VERSION ""

NS_ :

BS_:

BU_: ICC DVR EPC BBCM EAMP CMSM SBOX FLZCU_HCU_IC FLZCU_IC HCU_IC FLZCU_Signal_IC CGW TBOX BNCM CWC FRZCU

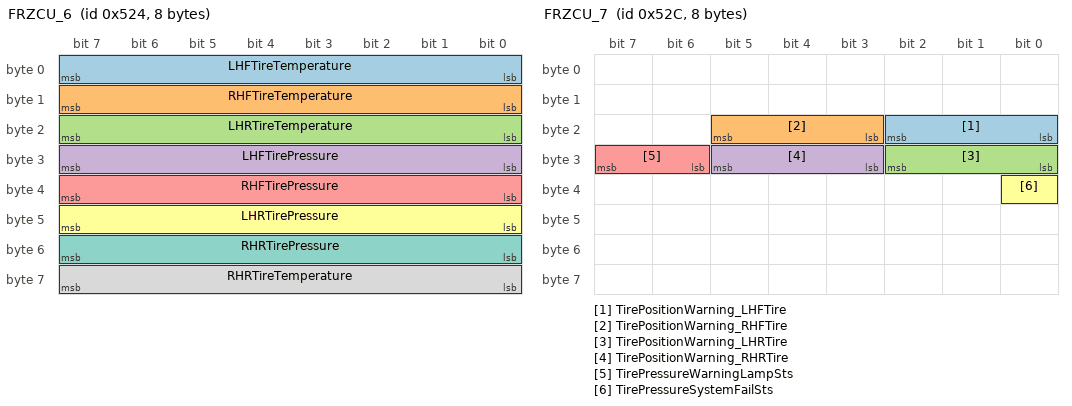
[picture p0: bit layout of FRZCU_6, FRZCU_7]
BO_ 1316 FRZCU_6: 8 CGW
 SG_ LHFTireTemperature : 7|8@0+ (0.65,-40) [-40|125.1] "℃"  ICC
 SG_ RHFTireTemperature : 15|8@0+ (0.65,-40) [-40|125.1] "℃"  ICC
 SG_ LHRTireTemperature : 23|8@0+ (0.65,-40) [-40|125.1] "℃"  ICC
 SG_ LHFTirePressure : 31|8@0+ (1.373,0) [0|350.115] "kPa"  ICC
 SG_ RHFTirePressure : 39|8@0+ (1.373,0) [0|350.115] "kPa"  ICC
 SG_ LHRTirePressure : 47|8@0+ (1.373,0) [0|350.115] "kPa"  ICC
 SG_ RHRTirePressure : 55|8@0+ (1.373,0) [0|350.115] "kPa"  ICC
 SG_ RHRTireTemperature : 63|8@0+ (0.65,-40) [-40|125.1] "℃"  ICC

BO_ 1324 FRZCU_7: 8 CGW
 SG_ TirePositionWarning_LHFTire : 18|3@0+ (1,0) [0|7] ""  ICC
 SG_ TirePositionWarning_RHFTire : 21|3@0+ (1,0) [0|7] ""  ICC
 SG_ TirePositionWarning_LHRTire : 26|3@0+ (1,0) [0|7] ""  ICC
 SG_ TirePositionWarning_RHRTire : 29|3@0+ (1,0) [0|7] ""  ICC
 SG_ TirePressureWarningLampSts : 31|2@0+ (1,0) [0|3] ""  ICC
 SG_ TirePressureSystemFailSts : 32|1@0+ (1,0) [0|1] ""  ICC

BO_ 991 TMS_2: 24 CGW
 SG_ TMS_MotorLoopErrorLevel : 126|3@0+ (1,0) [0|7] ""  ICC
 SG_ TMS_BatteryLoopErrorLevel : 123|3@0+ (1,0) [0|7] ""  ICC

BO_ 1188 TMS_3: 32 CGW
 SG_ FrontDeforestDisplaySts : 16|1@0+ (1,0) [0|1] ""  ICC
 SG_ TMS_DisplayActive : 18|1@0+ (1,0) [0|1] ""  ICC
 SG_ TMS_ZoneSelectionDisplaySts : 19|1@0+ (1,0) [0|1] ""  ICC
 SG_ TMS_AutoDisplaySts : 20|1@0+ (1,0) [0|1] ""  ICC
 SG_ TMS_FiltertchangeDisplaySts : 21|1@0+ (1,0) [0|1] ""  ICC
 SG_ TMS_AUTODefrostOnSts : 22|1@0+ (1,0) [0|1] ""  ICC
 SG_ TMS_AUTODefrostDisplaySts : 23|1@0+ (1,0) [0|1] ""  ICC
 SG_ TMS_RefInSufDispSts : 24|1@0+ (1,0) [0|1] ""  ICC
 SG_ TMS_CooltInSufDispSts : 25|1@0+ (1,0) [0|1] ""  ICC
 SG_ TMS_DLOnOffSts : 26|1@0+ (1,0) [0|1] ""  ICC
 SG_ TMS_DROnOffSts : 27|1@0+ (1,0) [0|1] ""  ICC
 SG_ TMS_PLOnOffSts : 28|1@0+ (1,0) [0|1] ""  ICC
 SG_ WorkingSts : 29|1@0+ (1,0) [0|1] ""  ICC
 SG_ TMS_PROnOffSts : 30|1@0+ (1,0) [0|1] ""  ICC
 SG_ TMS_DCOnOffSts : 31|1@0+ (1,0) [0|1] ""  ICC
 SG_ TMS_ACFastCool : 48|1@0+ (1,0) [0|1] ""  ICC
 SG_ TMS_ACFastHeat : 49|1@0+ (1,0) [0|1] ""  ICC
 SG_ TMS_LoveRemind : 50|1@0+ (1,0) [0|1] ""  ICC
 SG_ TMS_InteCleanCar : 51|1@0+ (1,0) [0|1] ""  ICC
 SG_ TMS_ACVentilationSts : 52|1@0+ (1,0) [0|1] ""  ICC
 SG_ TMS_AutoAirCleanSts : 53|1@0+ (1,0) [0|1] ""  ICC
 SG_ PM25Sts : 54|1@0+ (1,0) [0|1] ""  ICC
 SG_ TMS_ACModeCustomSts : 33|2@0+ (1,0) [0|3] ""  ICC
 SG_ TMS_ACRequestDisplaySts : 36|3@0+ (1,0) [0|7] ""  ICC
 SG_ TMS_AUTODefLevelSts : 39|3@0+ (1,0) [0|7] ""  ICC
 SG_ TMS_KeepWarm : 41|2@0+ (1,0) [0|3] ""  ICC
 SG_ TMS_DSwingSts : 44|3@0+ (1,0) [0|7] ""  ICC
 SG_ TMS_PSwingSts : 47|3@0+ (1,0) [0|7] ""  ICC
 SG_ TMS_TuisongDispSts : 58|3@0+ (1,0) [0|7] ""  ICC
 SG_ TMS_SetTemperature_L_C : 63|5@0+ (0.5,15.5) [15.5|30.5] ""  ICC
 SG_ TMS_SetTemperature_R_C : 68|5@0+ (0.5,15.5) [15.5|30.5] ""  ICC
 SG_ TMS_ModeAdjustDisplaySts : 75|4@0+ (1,0) [0|15] ""  ICC
 SG_ TMS_CirculationModeDisplaySts : 79|2@0+ (1,0) [0|3] ""  ICC
 SG_ TMS_IncarTemp : 87|8@0+ (0.5,-40) [-40|85] ""  ICC
 SG_ TMS_FliterLife : 94|7@0+ (1,0) [0|100] ""  ICC
 SG_ TMS_DLSwingUpDwnWPosn : 102|7@0+ (1,0) [0|100] ""  ICC
 SG_ TMS_DLSwingLeRiWPosn : 110|7@0+ (1,0) [0|100] ""  ICC
 SG_ TMS_DRSwingUpDwnWPosn : 118|7@0+ (1,0) [0|100] ""  ICC
 SG_ TMS_DRSwingLeRiWPosn : 126|7@0+ (1,0) [0|100] ""  ICC
 SG_ TMS_PLSwingUpDwnWPosn : 134|7@0+ (1,0) [0|100] ""  ICC
 SG_ TMS_PLSwingLeRiWPosn : 142|7@0+ (1,0) [0|100] ""  ICC
 SG_ TMS_PRSwingUpDwnWPosn : 150|7@0+ (1,0) [0|100] ""  ICC
 SG_ TMS_PRSwingLeRiWPosn : 158|7@0+ (1,0) [0|100] ""  ICC
 SG_ TMS_DCSwingLeRiWPosn : 166|7@0+ (1,0) [0|100] ""  ICC
 SG_ AirSwingSts : 168|1@0+ (1,0) [0|1] ""  ICC
 SG_ TemperatureUnit : 169|1@0+ (1,0) [0|1] ""  ICC
 SG_ BlowAdvanceOnSts : 170|1@0+ (1,0) [0|1] ""  ICC
 SG_ BlowDelayOffSts : 171|1@0+ (1,0) [0|1] ""  ICC
 SG_ TMS_PM25_ExtSts : 172|1@0+ (1,0) [0|1] ""  ICC
 SG_ TMS_PM25_IncarSts : 173|1@0+ (1,0) [0|1] ""  ICC
 SG_ TMS_AQS_Sts : 174|1@0+ (1,0) [0|1] ""  ICC
 SG_ PM25overproofDisplaySts : 175|1@0+ (1,0) [0|1] ""  ICC
 SG_ AQSDisplaySts : 176|1@0+ (1,0) [0|1] ""  ICC
 SG_ PM25AutoRunSts : 177|1@0+ (1,0) [0|1] ""  ICC
 SG_ PM25AutoRunSetSts : 178|1@0+ (1,0) [0|1] ""  ICC
 SG_ FragranceWelcomeModeSts : 179|1@0+ (1,0) [0|1] ""  ICC
 SG_ FragranceDisplaysts : 180|1@0+ (1,0) [0|1] ""  ICC
 SG_ TMS_AQS_Level : 185|2@0+ (1,0) [0|3] ""  ICC
 SG_ ACRequestCommand : 188|3@0+ (1,0) [0|7] ""  ICC
 SG_ PM25_Outcar_Level : 191|3@0+ (1,0) [0|7] ""  ICC
 SG_ PM25_Incar_Level : 194|3@0+ (1,0) [0|7] ""  ICC
 SG_ SetTemperature_L_F : 215|5@0+ (1,63) [63|93] ""  ICC
 SG_ SetTemperature_R_F : 223|5@0+ (1,63) [63|93] ""  ICC
 SG_ TMS_PM25_incar : 231|10@0+ (1,0) [0|1000] ""  ICC
 SG_ TMS_PM25_ext : 237|10@0+ (1,0) [0|1000] ""  ICC
 SG_ TMS_KeepWarmMemoryFb : 243|2@0+ (1,0) [0|3] ""  ICC

BO_ 612 EPB_R_1: 24 CGW
 SG_ Fusa_264_5 : 40|17@0+ (1,0) [0|131071] ""  ICC
 SG_ Fusa_264_4 : 47|6@0+ (1,0) [0|63] ""  ICC
 SG_ Fusa_264_3 : 24|5@0+ (1,0) [0|31] ""  ICC
 SG_ Fusa_264_2 : 16|7@0+ (1,0) [0|127] ""  ICC
 SG_ Fusa_264_1 : 15|4@0+ (1,0) [0|15] ""  ICC
 SG_ EPB_R_1_CRC1 : 7|8@0+ (1,0) [0|255] ""  ICC
 SG_ EPB_R_1_RollgCntr1 : 11|4@0+ (1,0) [0|14] ""  ICC
 SG_ EPB_1_FltLamp : 18|2@0+ (1,0) [0|3] ""  ICC
 SG_ EPB_1_ParkLamp : 20|2@0+ (1,0) [0|3] ""  ICC
 SG_ EPB_1_ActrSt : 23|3@0+ (1,0) [0|7] ""  ICC,DVR
 SG_ EPB_1_RWUSt : 25|1@0+ (1,0) [0|1] ""  ICC
 SG_ EPB_1_TextDisp : 35|4@0+ (1,0) [0|15] ""  ICC
 SG_ IPB_EPBErrorStatus : 41|1@0+ (1,0) [0|1] ""  ICC

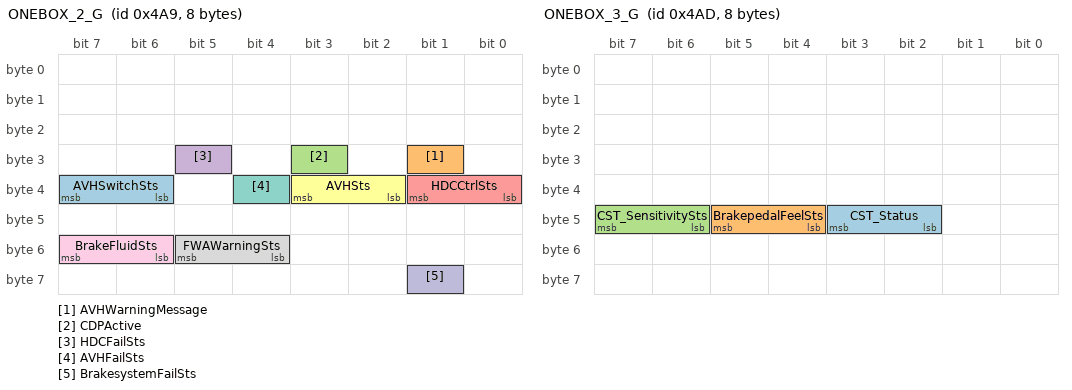
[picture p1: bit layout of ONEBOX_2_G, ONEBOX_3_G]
BO_ 1193 ONEBOX_2_G: 8 CGW
 SG_ AVHSwitchSts : 39|2@0+ (1,0) [0|3] ""  ICC
 SG_ AVHWarningMessage : 25|1@0+ (1,0) [0|1] ""  ICC
 SG_ CDPActive : 27|1@0+ (1,0) [0|1] ""  ICC
 SG_ HDCFailSts : 29|1@0+ (1,0) [0|1] ""  ICC
 SG_ HDCCtrlSts : 33|2@0+ (1,0) [0|3] ""  ICC
 SG_ AVHSts : 35|2@0+ (1,0) [0|3] ""  ICC
 SG_ AVHFailSts : 36|1@0+ (1,0) [0|1] ""  ICC
 SG_ FWAWarningSts : 53|2@0+ (1,0) [0|3] ""  ICC
 SG_ BrakeFluidSts : 55|2@0+ (1,0) [0|3] ""  ICC
 SG_ BrakesystemFailSts : 57|1@0+ (1,0) [0|1] ""  ICC

BO_ 1197 ONEBOX_3_G: 8 CGW
 SG_ CST_Status : 43|2@0+ (1,0) [0|3] ""  ICC
 SG_ BrakepedalFeelSts : 45|2@0+ (1,0) [0|3] ""  ICC
 SG_ CST_SensitivitySts : 47|2@0+ (1,0) [0|3] ""  ICC

BO_ 1200 FLZCU_6: 8 CGW
 SG_ EBS_SOC : 7|8@0+ (1,0) [0|100] "%"  ICC

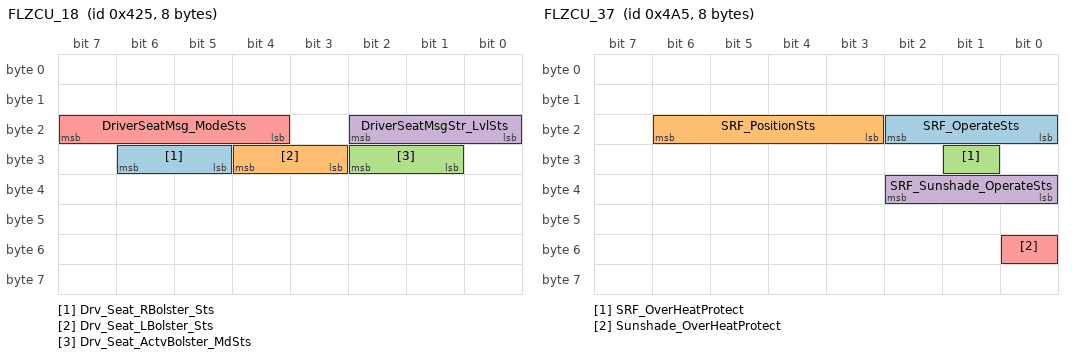
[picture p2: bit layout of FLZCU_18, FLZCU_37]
BO_ 1061 FLZCU_18: 8 CGW
 SG_ Drv_Seat_RBolster_Sts : 30|2@0+ (1,0) [0|3] ""  ICC
 SG_ Drv_Seat_LBolster_Sts : 28|2@0+ (1,0) [0|3] ""  ICC
 SG_ Drv_Seat_ActvBolster_MdSts : 26|2@0+ (1,0) [0|3] ""  ICC
 SG_ DriverSeatMsgStr_LvlSts : 18|3@0+ (1,0) [0|7] ""  ICC
 SG_ DriverSeatMsg_ModeSts : 23|4@0+ (1,0) [0|15] ""  ICC

BO_ 1065 FLZCU_19: 8 CGW
 SG_ LeftSeatMsgStr_LvlSts : 18|3@0+ (1,0) [0|7] ""  ICC
 SG_ LeftSeatMsg_ModeSts : 23|4@0+ (1,0) [0|15] ""  ICC

BO_ 1069 FLZCU_20: 8 CGW
 SG_ PassSeatMsgStr_LvlSts : 18|3@0+ (1,0) [0|7] ""  ICC
 SG_ PassSeatMsg_ModeSts : 23|4@0+ (1,0) [0|15] ""  ICC

BO_ 1087 FLZCU_21: 8 CGW
 SG_ RightSeatMsgStr_LvlSts : 18|3@0+ (1,0) [0|7] ""  ICC
 SG_ RightSeatMsg_ModeSts : 23|4@0+ (1,0) [0|15] ""  ICC

BO_ 1189 FLZCU_37: 8 CGW
 SG_ SRF_OperateSts : 18|3@0+ (1,0) [0|7] ""  ICC
 SG_ SRF_PositionSts : 22|4@0+ (1,0) [0|12] ""  ICC
 SG_ SRF_OverHeatProtect : 25|1@0+ (1,0) [0|1] ""  ICC
 SG_ SRF_Sunshade_OperateSts : 34|3@0+ (1,0) [0|7] ""  ICC
 SG_ Sunshade_OverHeatProtect : 48|1@0+ (1,0) [0|1] ""  ICC

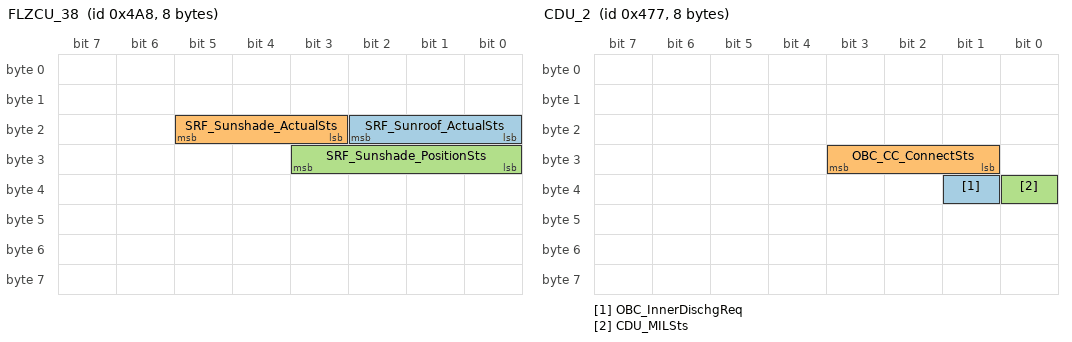
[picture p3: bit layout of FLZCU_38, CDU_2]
BO_ 1192 FLZCU_38: 8 CGW
 SG_ SRF_Sunroof_ActualSts : 18|3@0+ (1,0) [0|7] ""  ICC
 SG_ SRF_Sunshade_ActualSts : 21|3@0+ (1,0) [0|7] ""  ICC
 SG_ SRF_Sunshade_PositionSts : 27|4@0+ (1,0) [0|12] ""  ICC

BO_ 1143 CDU_2: 8 CGW
 SG_ OBC_InnerDischgReq : 33|1@0+ (1,0) [0|1] ""  ICC
 SG_ OBC_CC_ConnectSts : 27|3@0+ (1,0) [0|7] ""  ICC
 SG_ CDU_MILSts : 32|1@0+ (1,0) [0|1] ""  ICC

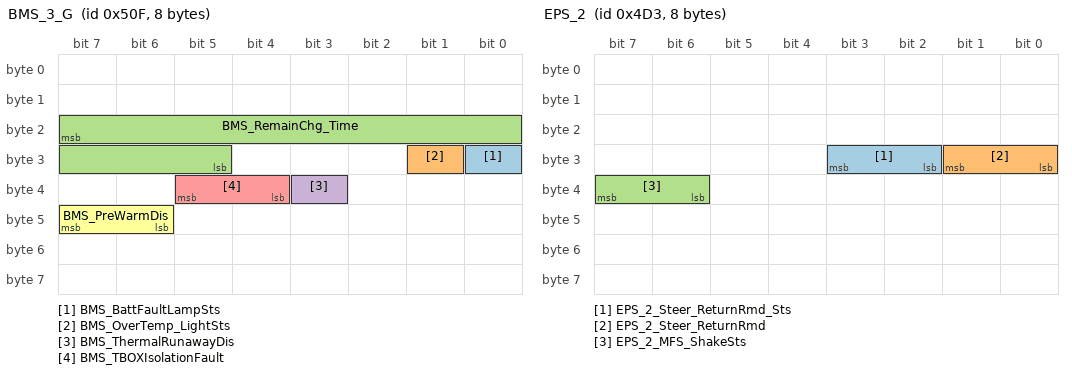
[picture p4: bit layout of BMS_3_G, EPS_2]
BO_ 1295 BMS_3_G: 8 CGW
 SG_ BMS_BattFaultLampSts : 24|1@0+ (1,0) [0|1] ""  ICC
 SG_ BMS_OverTemp_LightSts : 25|1@0+ (1,0) [0|1] ""  ICC
 SG_ BMS_RemainChg_Time : 23|11@0+ (1,0) [0|2047] "min"  ICC
 SG_ BMS_ThermalRunawayDis : 35|1@0+ (1,0) [0|1] ""  ICC
 SG_ BMS_TBOXIsolationFault : 37|2@0+ (1,0) [0|3] ""  ICC
 SG_ BMS_PreWarmDis : 47|2@0+ (1,0) [0|2] ""  ICC

BO_ 1531 BMS_9: 32 CGW
 SG_ BMS_HvBattSoeActDisChaCyc : 23|16@0+ (0.1,0) [0|999.9] "kWh"  ICC
 SG_ BMS_HvBattSoeActReChaCyc : 39|16@0+ (0.1,0) [0|999.9] "kWh"  ICC
 SG_ BMS_HvBattRatedEnergy : 55|14@0+ (0.1,0) [0|999.9] "KW?h"  ICC
 SG_ BMS_HvBattRatedU : 71|14@0+ (0.1,0) [0|999.9] "V"  ICC
 SG_ BMS_HvBattTypeCode : 87|8@0+ (1,0) [0|255] ""  ICC
 SG_ BMS_HvBattManufcCode : 95|32@0+ (1,0) [0|4294967295] ""  ICC
 SG_ BMS_HvBattTempSensorTotalNum : 127|16@0+ (1,0) [0|65534] ""  ICC
 SG_ BMS_HvBattTempSensorTempMaxNum : 143|8@0+ (1,0) [1|250] ""  ICC
 SG_ BMS_HvBattTempSensorTempMinNum : 151|8@0+ (1,0) [1|250] ""  ICC
 SG_ BMS_HvBattTempMaxNum : 159|8@0+ (1,0) [1|250] ""  ICC
 SG_ BMS_HvBattTempMinNum : 167|8@0+ (1,0) [1|250] ""  ICC
 SG_ BMS_BattCellTotalNum : 175|16@0+ (1,0) [0|65531] ""  ICC
 SG_ BMS_HvBattVoltMaxNum : 191|8@0+ (1,0) [1|250] ""  ICC
 SG_ BMS_HvBattVoltMinNum : 199|8@0+ (1,0) [1|250] ""  ICC
 SG_ BMS_ActualSOCMin : 207|12@0+ (0.025,0) [0|100] "%"  ICC
 SG_ BMS_ActualSOCMax : 211|12@0+ (0.025,0) [0|100] "%"  ICC

BO_ 1224 BMS_12: 16 CGW
 SG_ BMS_HvBattCellVoltMax_Num : 23|8@0+ (1,0) [0|250] ""  ICC
 SG_ BMS_HvBattCellVoltMax : 31|16@0+ (0.001,0) [0|15] "V"  ICC
 SG_ BMS_HvBattCellVoltMin_Num : 47|8@0+ (1,0) [0|250] ""  ICC
 SG_ BMS_HvBattCellVoltMin : 55|16@0+ (0.001,0) [0|15] "V"  ICC
 SG_ BMS_Chg_Sts : 87|4@0+ (1,0) [0|15] ""  ICC

BO_ 1235 EPS_2: 8 CGW
 SG_ EPS_2_Steer_ReturnRmd_Sts : 27|2@0+ (1,0) [0|3] ""  ICC
 SG_ EPS_2_Steer_ReturnRmd : 25|2@0+ (1,0) [0|3] ""  ICC
 SG_ EPS_2_MFS_ShakeSts : 39|2@0+ (1,0) [0|3] ""  ICC

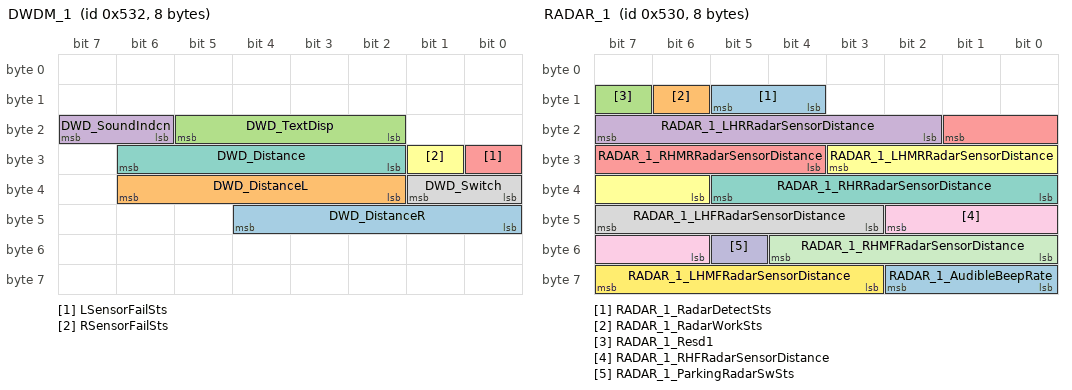
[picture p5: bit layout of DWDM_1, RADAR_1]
BO_ 1330 DWDM_1: 8 CGW
 SG_ DWD_DistanceR : 44|5@0+ (1,0) [0|31] ""  ICC
 SG_ DWD_DistanceL : 38|5@0+ (1,0) [0|31] ""  ICC
 SG_ DWD_TextDisp : 21|4@0+ (1,0) [0|15] ""  ICC
 SG_ DWD_SoundIndcn : 23|2@0+ (1,0) [0|3] ""  ICC
 SG_ LSensorFailSts : 24|1@0+ (1,0) [0|1] ""  ICC
 SG_ RSensorFailSts : 25|1@0+ (1,0) [0|1] ""  ICC
 SG_ DWD_Distance : 30|5@0+ (1,0) [0|31] ""  ICC
 SG_ DWD_Switch : 33|2@0+ (1,0) [0|3] ""  ICC

BO_ 1328 RADAR_1: 8 CGW
 SG_ RADAR_1_RadarDetectSts : 13|2@0+ (1,0) [0|3] "Bit"  ICC
 SG_ RADAR_1_RadarWorkSts : 14|1@0+ (1,0) [0|1] "Bit"  ICC
 SG_ RADAR_1_Resd1 : 15|1@0+ (1,0) [0|1] ""  ICC
 SG_ RADAR_1_LHRRadarSensorDistance : 23|6@0+ (5,25) [25|180] "Cm"  ICC
 SG_ RADAR_1_RHMRRadarSensorDistance : 17|6@0+ (5,25) [25|180] "Cm"  ICC
 SG_ RADAR_1_LHMRRadarSensorDistance : 27|6@0+ (5,25) [25|180] "Cm"  ICC
 SG_ RADAR_1_RHRRadarSensorDistance : 37|6@0+ (5,25) [25|180] "Cm"  ICC
 SG_ RADAR_1_LHFRadarSensorDistance : 47|5@0+ (5,25) [25|160] "Cm"  ICC
 SG_ RADAR_1_RHFRadarSensorDistance : 42|5@0+ (5,25) [25|160] "Cm"  ICC
 SG_ RADAR_1_ParkingRadarSwSts : 53|1@0+ (1,0) [0|1] "Bit"  ICC
 SG_ RADAR_1_RHMFRadarSensorDistance : 52|5@0+ (5,25) [25|160] "Cm"  ICC
 SG_ RADAR_1_LHMFRadarSensorDistance : 63|5@0+ (5,25) [25|160] "Cm"  ICC
 SG_ RADAR_1_AudibleBeepRate : 58|3@0+ (1,0) [0|7] "Bit"  ICC

BO_ 259 EMS_6: 16 CGW
 SG_ EMS_EngineSpeed_Actual : 39|16@0+ (0.25,0) [0|16383] "rpm"  ICC

BO_ 1234 FRZCU_11: 32 CGW
 SG_ FRZCU_ManualPowerOFFWarning_4D2h : 16|1@0+ (1,0) [0|1] ""  ICC
 SG_ FRZCU_FRSeatHeiFb : 23|7@0+ (1,-1) [-1|100] "%"  ICC,BBCM
 SG_ FRZCU_FRSeatLvlFb : 31|7@0+ (1,-1) [-1|100] "%"  ICC,BBCM
 SG_ FRZCU_FRSeatBackAgFb : 39|7@0+ (1,-1) [-1|100] "%"  ICC,BBCM
 SG_ FRZCU_FRSeatLegSpprtFb : 47|7@0+ (1,-1) [-1|100] "%"  ICC
 SG_ FRZCU_FRWinSts : 55|3@0+ (1,0) [0|7] ""  ICC
 SG_ FRZCU_RRWinSts : 52|3@0+ (1,0) [0|7] ""  ICC
 SG_ FRZCU_FRSeatLegRestAngleFb : 62|7@0+ (1,-1) [-1|100] "%"  ICC
 SG_ FRZCU_FRSeatCushFb : 86|7@0+ (1,-1) [-1|100] "%"  ICC,BBCM
 SG_ FRZCU_FRSeatNeedMemory : 105|2@0+ (1,0) [0|3] ""  ICC
 SG_ FRZCU_FRMemoryFb : 107|2@0+ (1,0) [0|3] ""  ICC
 SG_ FRZCU_FRRecoverFb : 109|2@0+ (1,0) [0|3] ""  ICC
 SG_ FRZCU_EasyEntryExitFb : 111|2@0+ (1,0) [0|3] ""  ICC
 SG_ FRZCU_EnjoyableSeatWarning : 113|2@0+ (1,0) [0|3] ""  ICC
 SG_ FRZCU_EnjoyableSeatSts : 115|2@0+ (1,0) [0|3] ""  ICC
 SG_ SeatHeatLevelsFR : 127|3@0+ (1,0) [0|7] ""  ICC
 SG_ SeatVentLevelsFR : 123|2@0+ (1,0) [0|3] ""  ICC
 SG_ SeatHeatLevelsRR : 151|3@0+ (1,0) [0|7] ""  ICC
 SG_ SeatVentLevelsRR : 147|2@0+ (1,0) [0|3] ""  ICC
 SG_ FRZCU_FRSeatFoldFb : 167|7@0+ (1,-1) [-1|100] "%"  ICC

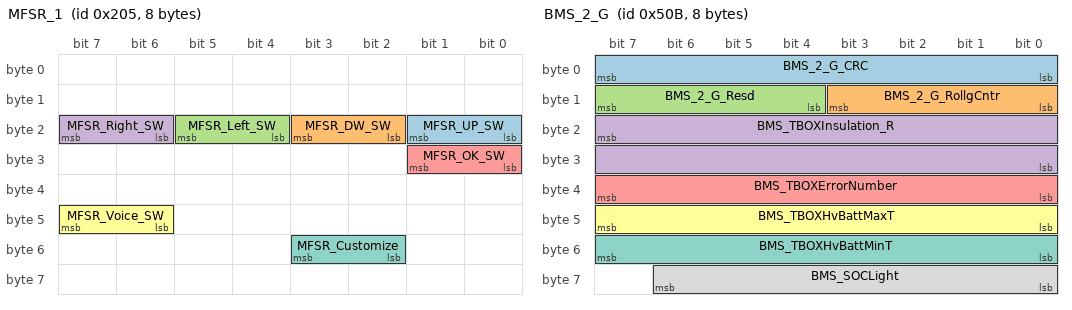
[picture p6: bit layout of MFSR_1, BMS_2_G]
BO_ 517 MFSR_1: 8 CGW
 SG_ MFSR_UP_SW : 17|2@0+ (1,0) [0|3] ""  ICC
 SG_ MFSR_DW_SW : 19|2@0+ (1,0) [0|3] ""  ICC
 SG_ MFSR_Left_SW : 21|2@0+ (1,0) [0|3] ""  ICC
 SG_ MFSR_Right_SW : 23|2@0+ (1,0) [0|3] ""  ICC
 SG_ MFSR_OK_SW : 25|2@0+ (1,0) [0|3] ""  ICC
 SG_ MFSR_Voice_SW : 47|2@0+ (1,0) [0|3] ""  ICC
 SG_ MFSR_Customize : 51|2@0+ (1,0) [0|3] ""  ICC

BO_ 1096 TMS_11: 32 CGW
 SG_ TMS_ICAstsFed_448h : 111|2@0+ (1,0) [0|3] ""  ICC
 SG_ TMS_SailEACDisable_448h : 109|2@0+ (1,0) [0|3] ""  ICC
 SG_ TMS_LowbattACDisable_448h : 107|2@0+ (1,0) [0|3] ""  ICC
 SG_ TMS_AutoDefogActiveSts : 37|1@0+ (1,0) [0|1] ""  ICC
 SG_ TMS_AirPurgeReminderSts : 17|2@0+ (1,0) [0|3] ""  ICC
 SG_ TMS_BT_Reduce_Wind_SpeedSts : 23|2@0+ (1,0) [0|3] "Bit"  ICC
 SG_ TMS_First_BlowingSts : 21|2@0+ (1,0) [0|3] "Bit"  ICC
 SG_ TMS_CirculationInTunnelsSts : 19|2@0+ (1,0) [0|3] "Bit"  ICC
 SG_ TMS_crosscountry_coolingSts : 29|2@0+ (1,0) [0|3] "Bit"  ICC
 SG_ TMS_ParkingAirConditioningStatus : 27|2@0+ (1,0) [0|3] "Bit"  ICC
 SG_ TMS_CoolantFillSts : 25|2@0+ (1,0) [0|3] "Bit"  ICC
 SG_ TMS_UVC_ControlSts : 39|2@0+ (1,0) [0|3] "Bit"  ICC
 SG_ TMS_UVC_LuminanceSts : 36|3@0+ (1,0) [0|7] "Bit"  ICC
 SG_ TMS_ICC_Lightoff_Sts : 33|2@0+ (1,0) [0|3] ""  ICC
 SG_ TMS_ICC_Memoff_Sts : 47|2@0+ (1,0) [0|3] ""  ICC
 SG_ TMS_keepwarmSet_TemperatureSts : 55|8@0+ (1,0) [0|254] "Bit"  ICC
 SG_ TMS_BiochemicalFuncSts : 95|2@0+ (1,0) [0|3] ""  ICC
 SG_ TMS_TimedVentilationSts : 97|2@0+ (1,0) [0|3] ""  ICC

BO_ 1240 TDU_9: 32 CGW
 SG_ TMS_CFSSwitchFb : 17|2@0+ (1,0) [0|3] ""  ICC
 SG_ TDU_CFSPosOneType : 21|4@0+ (1,0) [0|15] ""  ICC
 SG_ TDU_CFSPosTwoType : 27|4@0+ (1,0) [0|15] ""  ICC
 SG_ TDU_CFSPosThreeType : 31|4@0+ (1,0) [0|15] ""  ICC
 SG_ TDU_CFSRunOut : 39|4@0+ (1,0) [0|15] ""  ICC
 SG_ TMS_CFSShortWarn : 43|4@0+ (1,0) [0|15] ""  ICC
 SG_ TMS_CFSLevelSetFb : 47|4@0+ (1,0) [0|15] ""  ICC
 SG_ TMS_CFSPosSetFb : 49|2@0+ (1,0) [0|3] ""  ICC
 SG_ TMS_CFSPosOneLife : 63|8@0+ (1,0) [0|100] "%"  ICC
 SG_ TMS_CFSPosTwoLife : 87|8@0+ (1,0) [0|100] "%"  ICC
 SG_ TMS_CFSPosThreeLife : 95|8@0+ (1,0) [0|100] "%"  ICC
 SG_ TMS_PM25SwitchFb : 97|2@0+ (1,0) [0|3] ""  ICC
 SG_ TMS_ThrModeStsFb : 122|3@0+ (1,0) [0|6] ""  ICC
 SG_ TMS_ThrSetTempFb_C : 127|5@0+ (0.5,15.5) [15.5|30.5] "℃"  ICC
 SG_ TMS_ThrCLMSwitchFb : 145|2@0+ (1,0) [0|3] ""  ICC
 SG_ TMS_ThrAutoSwitchFb : 147|2@0+ (1,0) [0|3] ""  ICC
 SG_ TMS_ThrBlowSpeedLevelKeyStsFb : 151|4@0+ (1,0) [0|15] ""  ICC

BO_ 638 FRZCU_9: 16 CGW
 SG_ FRZCU_HoodSts : 45|2@0+ (1,0) [0|3] ""  ICC
 SG_ FRZCU_AuthenResult : 48|1@0+ (1,0) [0|1] ""  ICC
 SG_ FRZCU_PowerMode : 51|2@0+ (1,0) [0|3] ""  ICC
 SG_ FRZCU_TrunkSts : 53|2@0+ (1,0) [0|3] ""  ICC
 SG_ FRZCU_HandleSwitchStsFL : 57|2@0+ (1,0) [0|3] ""  ICC,BBCM
 SG_ FRZCU_HandleSwitchStsFR : 59|2@0+ (1,0) [0|3] ""  ICC,BBCM
 SG_ FRZCU_HandleSwitchStsRR : 61|2@0+ (1,0) [0|3] ""  ICC
 SG_ FRZCU_HandleSwitchStsRL : 63|2@0+ (1,0) [0|3] ""  ICC
 SG_ SeatLength_target_Passenger : 87|4@0+ (1,0) [0|15] ""  ICC
 SG_ SeatBackrest_target_Passenger : 95|5@0+ (1,0) [0|15] ""  ICC
 SG_ FRZCU_TrunkLockSts : 89|2@0+ (1,0) [0|3] ""  ICC
 SG_ FRZCU_HoodLockSts : 103|2@0+ (1,0) [0|3] ""  ICC
 SG_ FrontBackSpeedAdj_Cmd : 101|3@0+ (1,0) [0|7] ""  ICC
 SG_ FRZCU_GloveboxSW : 98|1@0+ (1,0) [0|1] ""  ICC
 SG_ FRZCU_FRReleaseLockSts : 111|3@0+ (1,0) [0|7] ""  ICC
 SG_ FRZCU_RRReleaseLockSts : 108|3@0+ (1,0) [0|7] ""  ICC
 SG_ FRZCU_PELockInKeyWarning : 105|1@0+ (1,0) [0|1] ""  ICC
 SG_ FRZCU_PowerOFFWarning : 118|1@0+ (1,0) [0|1] ""  ICC
 SG_ FRZCU_KeylessWarning : 116|1@0+ (1,0) [0|1] ""  ICC
 SG_ FRZCU_OTAPwrDwnReqFb : 113|2@0+ (1,0) [0|3] ""  ICC
 SG_ FRZCU_OTAPwrOnReqFb : 127|2@0+ (1,0) [0|3] ""  ICC

BO_ 949 PEPS_1: 16 CGW
 SG_ PEPS_InformationSource : 23|2@0+ (1,0) [0|3] ""  ICC,BBCM
 SG_ PEPS_OrderInformation : 21|4@0+ (1,0) [0|15] ""  ICC,BBCM
 SG_ PEPS_IDInformation : 31|4@0+ (1,0) [0|15] ""  ICC,BBCM
 SG_ PEPS_KeySts : 27|3@0+ (1,0) [0|7] ""  ICC,BBCM
 SG_ PEPS_ETRUnLockReq : 39|2@0+ (1,0) [0|3] ""  ICC,BBCM

BO_ 1028 PEPS_2: 16 CGW
 SG_ PEPS_WelcomeON : 17|2@0+ (1,0) [0|3] ""  ICC,BBCM
 SG_ PEPS_VehicleSearchReq : 19|2@0+ (1,0) [0|3] ""  ICC,BBCM
 SG_ PEPS_SATOReminder : 21|2@0+ (1,0) [0|3] ""  ICC,BBCM
 SG_ PEPS_PLGUnlockReq : 23|2@0+ (1,0) [0|3] ""  ICC,BBCM
 SG_ PEPS_RKETrunkSts : 25|2@0+ (1,0) [0|3] ""  ICC,BBCM
 SG_ PEPS_SSBInhibitCWCSts : 27|2@0+ (1,0) [0|3] ""  ICC,BBCM
 SG_ PEPS_WirelessChargingCtrSts : 29|2@0+ (1,0) [0|3] ""  ICC,BBCM
 SG_ PEPS_EmgyShutdown : 35|2@0+ (1,0) [0|3] ""  ICC,BBCM
 SG_ PEPS_SSBInputFailure : 37|2@0+ (1,0) [0|3] ""  ICC,BBCM
 SG_ PEPS_SmartSystemWarning1_1 : 39|2@0+ (1,0) [0|3] ""  ICC,BBCM
 SG_ PEPS_SmartSystemWarning2_2 : 41|2@0+ (1,0) [0|3] ""  ICC,BBCM
 SG_ PEPS_SmartSystemWarning3_1 : 43|2@0+ (1,0) [0|3] ""  ICC,BBCM
 SG_ PEPS_SmartSystemWarning3_2 : 45|2@0+ (1,0) [0|3] ""  ICC,BBCM
 SG_ PEPS_SmartSystemWarning4_2 : 47|2@0+ (1,0) [0|3] ""  ICC,BBCM
 SG_ PEPS_SmartSystemWarning4_3 : 49|2@0+ (1,0) [0|3] ""  ICC,BBCM
 SG_ PEPS_SystemWarning : 51|2@0+ (1,0) [0|3] ""  ICC,BBCM
 SG_ PEPS_BLTKeyPESts : 53|2@0+ (1,0) [0|3] ""  ICC,BBCM

BO_ 1291 BMS_2_G: 8 CGW
 SG_ BMS_2_G_CRC : 7|8@0+ (1,0) [0|255] ""  ICC
 SG_ BMS_2_G_RollgCntr : 11|4@0+ (1,0) [0|14] ""  ICC
 SG_ BMS_2_G_Resd : 15|4@0+ (1,0) [0|15] ""  ICC
 SG_ BMS_TBOXInsulation_R : 23|16@0+ (1,0) [0|60000] "kiloohm(kΩ)"  ICC
 SG_ BMS_TBOXErrorNumber : 39|8@0+ (1,0) [0|255] ""  ICC
 SG_ BMS_TBOXHvBattMaxT : 47|8@0+ (1,-40) [-40|210] "gradcelsius(°C)"  ICC
 SG_ BMS_TBOXHvBattMinT : 55|8@0+ (1,-40) [-40|210] "gradcelsius(°C)"  ICC
 SG_ BMS_SOCLight : 62|7@0+ (1,0) [0|100] "%"  ICC

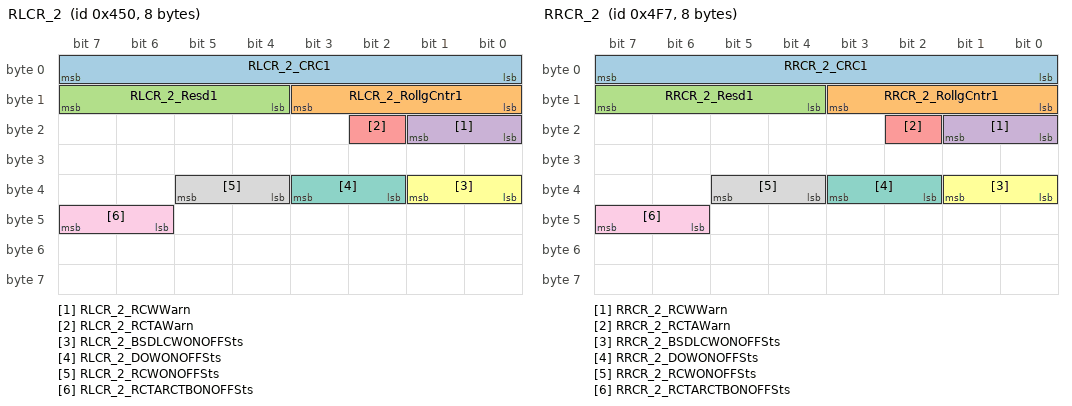
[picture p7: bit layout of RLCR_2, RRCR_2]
BO_ 1104 RLCR_2: 8 CGW
 SG_ RLCR_2_CRC1 : 7|8@0+ (1,0) [0|255] ""  ICC
 SG_ RLCR_2_RollgCntr1 : 11|4@0+ (1,0) [0|14] ""  ICC
 SG_ RLCR_2_Resd1 : 15|4@0+ (1,0) [0|15] ""  ICC
 SG_ RLCR_2_RCWWarn : 17|2@0+ (1,0) [0|3] ""  ICC
 SG_ RLCR_2_RCTAWarn : 18|1@0+ (1,0) [0|1] ""  ICC
 SG_ RLCR_2_BSDLCWONOFFSts : 33|2@0+ (1,0) [0|3] ""  ICC
 SG_ RLCR_2_DOWONOFFSts : 35|2@0+ (1,0) [0|3] ""  ICC
 SG_ RLCR_2_RCWONOFFSts : 37|2@0+ (1,0) [0|3] ""  ICC
 SG_ RLCR_2_RCTARCTBONOFFSts : 47|2@0+ (1,0) [0|3] ""  ICC

BO_ 1271 RRCR_2: 8 CGW
 SG_ RRCR_2_CRC1 : 7|8@0+ (1,0) [0|255] ""  ICC
 SG_ RRCR_2_RollgCntr1 : 11|4@0+ (1,0) [0|14] ""  ICC
 SG_ RRCR_2_Resd1 : 15|4@0+ (1,0) [0|15] ""  ICC
 SG_ RRCR_2_RCWWarn : 17|2@0+ (1,0) [0|3] ""  ICC
 SG_ RRCR_2_RCTAWarn : 18|1@0+ (1,0) [0|1] ""  ICC
 SG_ RRCR_2_BSDLCWONOFFSts : 33|2@0+ (1,0) [0|3] ""  ICC
 SG_ RRCR_2_DOWONOFFSts : 35|2@0+ (1,0) [0|3] ""  ICC
 SG_ RRCR_2_RCWONOFFSts : 37|2@0+ (1,0) [0|3] ""  ICC
 SG_ RRCR_2_RCTARCTBONOFFSts : 47|2@0+ (1,0) [0|3] ""  ICC

BO_ 587 ONEBOX_4: 48 CGW
 SG_ IPB_SandABSSwSts_24Bh : 269|2@0+ (1,0) [0|3] ""  ICC
 SG_ IPB_SandABSAvl_24Bh : 277|2@0+ (1,0) [0|3] ""  ICC
 SG_ ONEBOX_4_LHFWheelSpeedRPM : 23|16@0+ (0.0625,0) [0|4095.875] "rpm"  ICC
 SG_ ONEBOX_4_RHFWheelSpeedRPM : 39|16@0+ (0.0625,0) [0|4095.875] "rpm"  ICC
 SG_ LHRWheelSpeedRPM : 55|16@0+ (0.0625,0) [0|4095.875] "rpm"  ICC
 SG_ RHRWheelSpeedRPM : 87|16@0+ (0.0625,0) [0|4095.875] "rpm"  ICC
 SG_ LHRPulseCounterFailSts : 106|1@0+ (1,0) [0|1] ""  ICC
 SG_ LHRPulseCounter : 103|13@0+ (1,0) [0|8191] "pulse"  ICC
 SG_ RHRPulseCounterFailSts : 122|1@0+ (1,0) [0|1] ""  ICC
 SG_ RHRPulseCounter : 119|13@0+ (1,0) [0|8191] "pulse"  ICC
 SG_ RHFPulseCounterFailSts : 154|1@0+ (1,0) [0|1] ""  ICC
 SG_ RHFPulseCounter : 151|13@0+ (1,0) [0|8191] "pulse"  ICC
 SG_ LHFPulseCounterFailSts : 170|1@0+ (1,0) [0|1] ""  ICC
 SG_ LHFPulseCounter : 167|13@0+ (1,0) [0|8191] "pulse"  ICC
 SG_ LHFWheelDriveDirection : 187|3@0+ (1,0) [0|7] ""  ICC
 SG_ RHFWheelDriveDirection : 219|3@0+ (1,0) [0|7] ""  ICC
 SG_ LHRWheelDriveDirection : 235|3@0+ (1,0) [0|7] ""  ICC
 SG_ RHRWheelDriveDirection : 251|3@0+ (1,0) [0|7] ""  ICC

BO_ 1338 FMCU_1_G: 8 CGW
 SG_ FMCU_ErrLvlDis : 19|3@0+ (1,0) [0|7] ""  ICC
 SG_ FMCU_SpdAct_EDR : 39|16@0+ (1,-32767) [-32767|32766] "rpm"  ICC

BO_ 777 ISGF_2: 8 CGW
 SG_ ISGF_ErrLvl : 20|4@0+ (1,0) [0|6] ""  ICC

BO_ 1403 RMCU_1_G: 8 CGW
 SG_ RMCU_ErrLvlDis : 19|3@0+ (1,0) [0|7] ""  ICC
 SG_ RMCU_Speed_EDR : 39|16@0+ (1,-32767) [-32767|32766] "rpm"  ICC

BO_ 1299 BMS_1_G: 8 CGW
 SG_ BMS_PackVoltageDis : 23|16@0+ (0.1,0) [0|1000] "volt(V)"  ICC
 SG_ BMS_PackCurrentDis : 39|16@0+ (0.1,-2047) [-2047|2047] "ampere(A)"  ICC

BO_ 1099 ISGF_4: 8 CGW
 SG_ ISGF_SysTempOvrInd : 40|1@0+ (1,0) [0|1] ""  ICC

BO_ 1130 TCU_23: 64 CGW
 SG_ TCU_23_GBFaultstatus : 23|2@0+ (1,0) [0|3] ""  ICC
 SG_ TCU_23_TeachInState : 30|3@0+ (1,0) [0|7] ""  ICC

BO_ 1180 ACU_1: 8 CGW
 SG_ New_Signal_49C_9 : 32|25@0+ (1,0) [0|33554431] ""  ICC
 SG_ New_Signal_49C_8 : 37|4@0+ (1,0) [0|15] ""  ICC
 SG_ New_Signal_49C_7 : 27|1@0+ (1,0) [0|1] ""  ICC
 SG_ New_Signal_49C_6 : 29|1@0+ (1,0) [0|1] ""  ICC
 SG_ New_Signal_49C_5 : 31|1@0+ (1,0) [0|1] ""  ICC
 SG_ New_Signal_49C_4 : 19|2@0+ (1,0) [0|3] ""  ICC
 SG_ New_Signal_49C_3 : 21|1@0+ (1,0) [0|1] ""  ICC
 SG_ New_Signal_49C_2 : 23|1@0+ (1,0) [0|1] ""  ICC
 SG_ New_Signal_49C_1 : 15|4@0+ (1,0) [0|15] ""  ICC
 SG_ ACU_1_RollgCntr1 : 11|4@0+ (1,0) [0|15] ""  ICC
 SG_ ACU_1_CRC1 : 7|8@0+ (1,0) [0|255] ""  ICC
 SG_ ABM_1_Rollover_Status : 33|1@0+ (1,0) [0|1] ""  ICC
 SG_ ACU_1_AirBagFailSts : 17|2@0+ (1,0) [0|3] ""  ICC
 SG_ ACU_1_ThdRowLBeltWarning : 20|1@0+ (1,0) [0|1] ""  ICC
 SG_ ACU_1_ThdRowRBeltWarning : 22|1@0+ (1,0) [0|1] ""  ICC
 SG_ ACU_1_PsngrSeatBeltWarning : 25|2@0+ (1,0) [0|3] ""  ICC
 SG_ ACU_1_SecRowLBeltWarning : 26|1@0+ (1,0) [0|1] ""  ICC
 SG_ ACU_1_SecRowMBeltWarning : 28|1@0+ (1,0) [0|1] ""  ICC
 SG_ ACU_1_SecRowRBeltWarning : 30|1@0+ (1,0) [0|1] ""  ICC
 SG_ ACU_1_PsngrSeatOccupiedSts : 39|2@0+ (1,0) [0|3] ""  ICC,BBCM

BO_ 1248 FRZCU_TO_FLZCU: 48 CGW

BO_ 1341 BMS_44: 48 CGW
 SG_ BMS_44_PackPowerRealTime : 23|15@0+ (0.1,-1024) [-1024|1024] "kW"  ICC

BO_ 811 BMS_6: 16 CGW
 SG_ BMS_Chg_Sts : 87|4@0+ (1,0) [0|15] ""  ICC

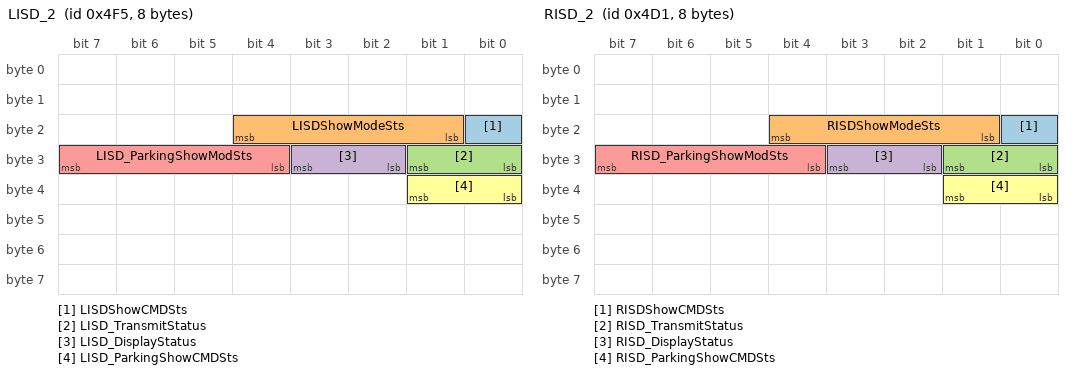
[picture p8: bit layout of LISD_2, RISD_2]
BO_ 1269 LISD_2: 8 CGW
 SG_ LISDShowCMDSts : 16|1@0+ (1,0) [0|1] ""  ICC
 SG_ LISDShowModeSts : 20|4@0+ (1,0) [0|15] ""  ICC
 SG_ LISD_TransmitStatus : 25|2@0+ (1,0) [0|3] ""  ICC
 SG_ LISD_DisplayStatus : 27|2@0+ (1,0) [0|3] ""  ICC
 SG_ LISD_ParkingShowModSts : 31|4@0+ (1,0) [0|15] ""  ICC
 SG_ LISD_ParkingShowCMDSts : 33|2@0+ (1,0) [0|3] ""  ICC

BO_ 1233 RISD_2: 8 CGW
 SG_ RISDShowCMDSts : 16|1@0+ (1,0) [0|1] ""  ICC
 SG_ RISDShowModeSts : 20|4@0+ (1,0) [0|15] ""  ICC
 SG_ RISD_TransmitStatus : 25|2@0+ (1,0) [0|3] ""  ICC
 SG_ RISD_DisplayStatus : 27|2@0+ (1,0) [0|3] ""  ICC
 SG_ RISD_ParkingShowModSts : 31|4@0+ (1,0) [0|15] ""  ICC
 SG_ RISD_ParkingShowCMDSts : 33|2@0+ (1,0) [0|3] ""  ICC

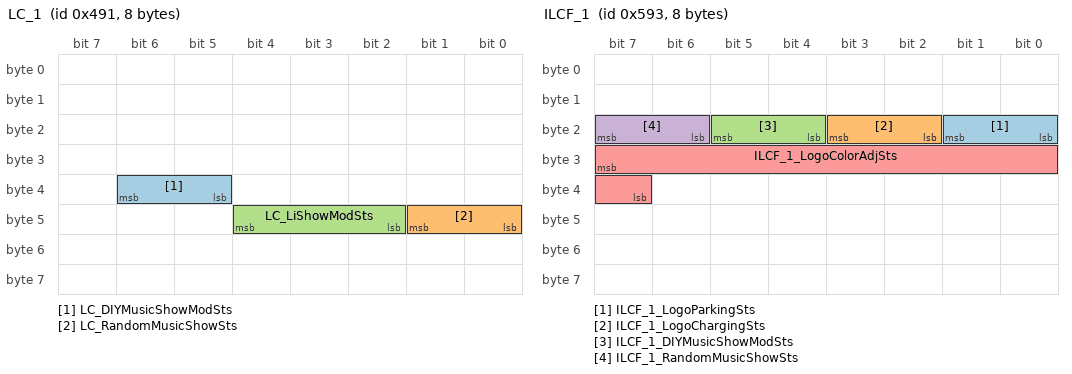
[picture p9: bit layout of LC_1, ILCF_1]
BO_ 1169 LC_1: 8 CGW
 SG_ LC_DIYMusicShowModSts : 38|2@0+ (1,0) [0|3] ""  ICC
 SG_ LC_RandomMusicShowSts : 41|2@0+ (1,0) [0|3] ""  ICC
 SG_ LC_LiShowModSts : 44|3@0+ (1,0) [0|7] ""  ICC

BO_ 1427 ILCF_1: 8 CGW
 SG_ ILCF_1_LogoParkingSts : 17|2@0+ (1,0) [0|3] ""  ICC
 SG_ ILCF_1_LogoChargingSts : 19|2@0+ (1,0) [0|3] ""  ICC
 SG_ ILCF_1_DIYMusicShowModSts : 21|2@0+ (1,0) [0|3] ""  ICC
 SG_ ILCF_1_RandomMusicShowSts : 23|2@0+ (1,0) [0|3] ""  ICC
 SG_ ILCF_1_LogoColorAdjSts : 31|9@0+ (1,0) [0|511] ""  ICC

BO_ 821 ADS_5: 48 CGW
 SG_ ADS_5_CRC1 : 7|8@0+ (1,0) [0|255] ""  ICC
 SG_ ADS_5_RollgCntr1 : 11|4@0+ (1,0) [0|14] ""  ICC
 SG_ ADS_5_Resd1 : 15|4@0+ (1,0) [0|15] ""  ICC
 SG_ ADS_5_ILOASts : 18|3@0+ (1,0) [0|7] ""  ICC
 SG_ ADS_5_ICAQuitReason : 21|3@0+ (1,0) [0|7] ""  ICC
 SG_ ADS_5_ISLISt : 23|2@0+ (1,0) [0|3] ""  ICC
 SG_ ADS_5_ILOATextInfo : 28|2@0+ (1,0) [0|3] ""  ICC
 SG_ ADS_5_ILOAActdirection : 30|2@0+ (1,0) [0|3] ""  ICC
 SG_ ADS_5_LKS_warning : 31|1@0+ (1,0) [0|1] ""  ICC
 SG_ ADS_5_ISLIOverSpeedWarn : 34|2@0+ (1,0) [0|3] ""  ICC
 SG_ ADS_5_ISLISpeedLimitSign : 26|8@0+ (1,0) [0|255] ""  ICC
 SG_ ADS_5_EgoLeftLineHeatgAg : 32|9@0+ (0.004,-1.02) [-1.02|1.02] "Rad"  ICC
 SG_ ADS_5_EgoLeLineID : 51|1@0+ (1,0) [0|1] ""  ICC
 SG_ ADS_5_EgoLeLineColor : 53|2@0+ (1,0) [0|3] ""  ICC
 SG_ ADS_5_EgoLeLineTyp : 55|2@0+ (1,0) [0|3] ""  ICC
 SG_ ADS_5_EgoLeLineHozlDst : 48|9@0+ (0.1,-25) [-25|25] "m"  ICC
 SG_ ADS_5_CRC2 : 71|8@0+ (1,0) [0|255] ""  ICC
 SG_ ADS_5_RollgCntr2 : 75|4@0+ (1,0) [0|14] ""  ICC
 SG_ ADS_5_Resd2 : 79|4@0+ (1,0) [0|15] ""  ICC
 SG_ ADS_5_NeborLeLineID : 89|1@0+ (1,0) [0|1] ""  ICC
 SG_ ADS_5_NeborLeLineColor : 91|2@0+ (1,0) [0|3] ""  ICC
 SG_ ADS_5_NeborLeLineTyp : 93|2@0+ (1,0) [0|3] ""  ICC
 SG_ ADS_5_EgoLeLineCrvt : 87|10@0+ (6E-005,-0.0156) [-0.0156|0.0156] "1/m"  ICC
 SG_ ADS_5_NeborLeLineHozlDst : 88|9@0+ (0.1,-25) [-25|25] "m"  ICC
 SG_ ADS_5_NeborRiLineID : 113|1@0+ (1,0) [0|1] ""  ICC
 SG_ ADS_5_NeborRiLineColor : 115|2@0+ (1,0) [0|3] ""  ICC
 SG_ ADS_5_NeborRiLineTyp : 117|2@0+ (1,0) [0|3] ""  ICC
 SG_ ADS_5_NeborLeLineCrvt : 111|10@0+ (6E-005,-0.0156) [-0.0156|0.0156] "1/m"  ICC
 SG_ ADS_5_NeborRiLineHozlDst : 112|9@0+ (0.1,-25) [-25|25] "m"  ICC
 SG_ ADS_5_CRC3 : 135|8@0+ (1,0) [0|255] ""  ICC
 SG_ ADS_5_RollgCntr3 : 139|4@0+ (1,0) [0|14] ""  ICC
 SG_ ADS_5_Resd3 : 143|4@0+ (1,0) [0|15] ""  ICC
 SG_ ADS_5_ELKSettingSt : 153|2@0+ (1,0) [0|3] ""  ICC
 SG_ ADS_5_LDWLDPSnvtySet : 155|2@0+ (1,0) [0|3] ""  ICC
 SG_ ADS_5_LDWWarnType : 157|2@0+ (1,0) [0|3] ""  ICC
 SG_ ADS_5_NeborRiLineCrvt : 151|10@0+ (6E-005,-0.0156) [-0.0156|0.0156] "1/m"  ICC
 SG_ ADS_5_IESSwtSet : 161|2@0+ (1,0) [0|3] ""  ICC
 SG_ ADS_5_IHCSettingSt : 163|2@0+ (1,0) [0|3] ""  ICC
 SG_ ADS_5_ISLIWarningMod : 165|2@0+ (1,0) [0|3] ""  ICC
 SG_ ADS_5_ICAEnableBtnSts : 167|2@0+ (1,0) [0|3] ""  ICC
 SG_ ADS_5_FCM_Camera_textinfo : 175|2@0+ (1,0) [0|3] ""  ICC
 SG_ ADS_5_EgoRiLineID : 183|2@0+ (1,0) [0|1] ""  ICC
 SG_ ADS_5_EgoRiLineTyp : 169|2@0+ (1,0) [0|3] ""  ICC
 SG_ ADS_5_EgoRiLineColor : 181|2@0+ (1,0) [0|3] ""  ICC
 SG_ ADS_5_EgoRiLineHozlDst : 179|9@0+ (0.1,-25) [-25|25] "m"  ICC
 SG_ ADS_5_CRC4 : 199|8@0+ (1,0) [0|255] ""  ICC
 SG_ ADS_5_RollgCntr4 : 203|4@0+ (1,0) [0|14] ""  ICC
 SG_ ADS_5_Resd4 : 207|4@0+ (1,0) [0|15] ""  ICC
 SG_ ADS_5_EgoRightLineHeatgAg : 215|9@0+ (0.004,-1.02) [-1.02|1.02] "Rad"  ICC
 SG_ ADS_5_EgoRiLineCrvt : 222|10@0+ (6E-005,-0.0156) [-0.0156|0.0156] "1/m"  ICC
 SG_ ADS_5_NeborLeftLineHeatgAg : 228|9@0+ (0.004,-1.02) [-1.02|1.02] "Rad"  ICC
 SG_ ADS_5_NeborRightLineHeatgAg : 235|9@0+ (0.004,-1.02) [-1.02|1.02] "Rad"  ICC

BO_ 819 ADS_4: 48 CGW
 SG_ ADS_4_CRC1 : 7|8@0+ (1,0) [0|255] ""  ICC
 SG_ ADS_4_RollgCntr1 : 11|4@0+ (1,0) [0|14] ""  ICC
 SG_ ADS_4_Resd1 : 15|4@0+ (1,0) [0|15] ""  ICC
 SG_ ADS_4_AEBStatus : 19|3@0+ (1,0) [0|7] ""  ICC
 SG_ ADS_4_ACCSts : 23|4@0+ (1,0) [0|15] ""  ICC
 SG_ ADS_4_TimeGapSet : 26|3@0+ (1,0) [0|7] ""  ICC
 SG_ ADS_4_FcwMode : 29|3@0+ (1,0) [0|7] ""  ICC
 SG_ ADS_4_AEBReqType : 16|3@0+ (1,0) [0|7] ""  ICC
 SG_ ADS_4_SetSpd : 39|8@0+ (1,0) [0|255] "kph"  ICC
 SG_ ADS_4_DAIStatus : 41|2@0+ (1,0) [0|3] ""  ICC
 SG_ ADS_4_ACCTextMessage : 45|4@0+ (1,0) [0|15] ""  ICC
 SG_ ADS_4_LongiTakeOverReq : 46|1@0+ (1,0) [0|1] ""  ICC
 SG_ ADS_4_SetSpdUnit : 47|1@0+ (1,0) [0|1] ""  ICC
 SG_ ADS_4_GoNotifier : 50|3@0+ (1,0) [0|7] ""  ICC
 SG_ ADS_4_DAISts : 52|2@0+ (1,0) [0|3] ""  ICC
 SG_ ADS_4_Radar_textinfo : 55|3@0+ (1,0) [0|7] ""  ICC
 SG_ ADS_4_SCF_PopoverReq : 57|1@0+ (1,0) [0|1] ""  ICC
 SG_ ADS_4_DrvrCfmSCFDispFb : 58|1@0+ (1,0) [0|1] ""  ICC
 SG_ ADS_4_SCF_SpdLimUnit : 60|2@0+ (1,0) [0|3] ""  ICC
 SG_ ADS_4_SCF_SpdLimSts : 63|3@0+ (1,0) [0|7] ""  ICC
 SG_ ADS_4_CRC2 : 71|8@0+ (1,0) [0|255] ""  ICC
 SG_ ADS_4_RollgCntr2 : 75|4@0+ (1,0) [0|14] ""  ICC
 SG_ ADS_4_Resd2 : 79|4@0+ (1,0) [0|15] ""  ICC
 SG_ ADS_4_ACCObjTyp : 83|4@0+ (1,0) [0|15] ""  ICC
 SG_ ADS_4_FrntFarObjTyp : 87|4@0+ (1,0) [0|15] ""  ICC
 SG_ ADS_4_ACCObjLgtDstX : 95|8@0+ (0.5,0) [0|127] "m"  ICC
 SG_ ADS_4_FrntFarObjID : 107|1@0+ (1,0) [0|1] ""  ICC
 SG_ ADS_4_Resd : 108|1@0+ (1,0) [0|1] ""  ICC
 SG_ ADS_4_ACCObjID : 109|1@0+ (1,0) [0|1] ""  ICC
 SG_ ADS_4_ACCObjHozDstY : 103|10@0+ (0.1,-50) [-50|50] "m"  ICC
 SG_ ADS_4_FrntFarObjHozDstY : 105|10@0+ (0.1,-50) [-50|50] "m"  ICC
 SG_ ADS_4_FrntFarObjLgtDstX : 127|8@0+ (0.5,0) [0|127] "m"  ICC
 SG_ ADS_4_CRC3 : 135|8@0+ (1,0) [0|255] ""  ICC
 SG_ ADS_4_RollgCntr3 : 139|4@0+ (1,0) [0|14] ""  ICC
 SG_ ADS_4_Resd3 : 143|4@0+ (1,0) [0|15] ""  ICC
 SG_ ADS_4_Resd_1 : 146|1@0+ (1,0) [0|1] ""  ICC
 SG_ ADS_4_LeObjID : 147|1@0+ (1,0) [0|1] ""  ICC
 SG_ ADS_4_LeObjTyp : 151|4@0+ (1,0) [0|15] ""  ICC
 SG_ ADS_4_LeObjHozDstY : 145|10@0+ (0.1,-50) [-50|50] "m"  ICC
 SG_ ADS_4_LeObjLgtDstX : 167|8@0+ (0.5,0) [0|127] "m"  ICC
 SG_ ADS_4_RiObjID : 171|1@0+ (1,0) [0|1] ""  ICC
 SG_ ADS_4_RiObjTyp : 175|4@0+ (1,0) [0|15] ""  ICC
 SG_ ADS_4_RiObjHozDstY : 169|10@0+ (0.1,-50) [-50|50] "m"  ICC
 SG_ ADS_4_RiObjLgtDstX : 191|8@0+ (0.5,0) [0|127] "m"  ICC
 SG_ ADS_4_CRC4 : 199|8@0+ (1,0) [0|255] ""  ICC
 SG_ ADS_4_RollgCntr4 : 203|4@0+ (1,0) [0|14] ""  ICC
 SG_ ADS_4_Resd4 : 207|4@0+ (1,0) [0|15] ""  ICC
 SG_ ADS_4_SCFSwtSet : 210|2@0+ (1,0) [0|3] ""  ICC
 SG_ ADS_4_AEBSettingSt : 212|2@0+ (1,0) [0|3] ""  ICC
 SG_ ADS_4_FCWSettingSt : 215|3@0+ (1,0) [0|7] ""  ICC
 SG_ ADS_4_DAISwtSet : 223|2@0+ (1,0) [0|3] ""  ICC
 SG_ ADS_4_CruiseAccelerateSts : 221|2@0+ (1,0) [0|3] ""  ICC

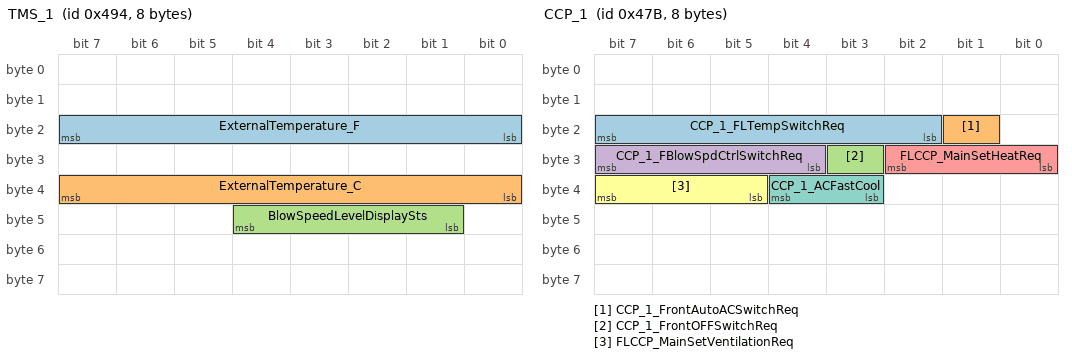
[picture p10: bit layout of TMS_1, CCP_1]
BO_ 1172 TMS_1: 8 CGW
 SG_ ExternalTemperature_F : 23|8@0+ (1,-67) [-67|158] "°F"  ICC,EPC
 SG_ ExternalTemperature_C : 39|8@0+ (0.5,-40) [-40|85] "°C"  ICC,EPC
 SG_ BlowSpeedLevelDisplaySts : 44|4@0+ (1,0) [0|15] ""  ICC,EAMP

BO_ 1147 CCP_1: 8 CGW
 SG_ CCP_1_FLTempSwitchReq : 23|6@0+ (0.5,15.5) [15.5|30.5] "℃"  ICC
 SG_ CCP_1_FrontAutoACSwitchReq : 17|1@0+ (1,0) [0|1] ""  ICC
 SG_ CCP_1_FrontOFFSwitchReq : 27|1@0+ (1,0) [0|1] ""  ICC
 SG_ CCP_1_FBlowSpdCtrlSwitchReq : 31|4@0+ (1,0) [0|15] ""  ICC
 SG_ FLCCP_MainSetHeatReq : 26|3@0+ (1,0) [0|7] ""  ICC
 SG_ FLCCP_MainSetVentilationReq : 39|3@0+ (1,0) [0|7] ""  ICC
 SG_ CCP_1_ACFastCool : 36|2@0+ (1,0) [0|3] ""  ICC

CM_ SG_ 1316 LHFTireTemperature "左前轮胎温度";
CM_ SG_ 1316 RHFTireTemperature "右前轮胎温度";
CM_ SG_ 1316 LHRTireTemperature "左后轮胎温度";
CM_ SG_ 1316 LHFTirePressure "左前轮胎胎压";
CM_ SG_ 1316 RHFTirePressure "右前轮胎胎压";
CM_ SG_ 1316 LHRTirePressure "左后轮胎胎压";
CM_ SG_ 1316 RHRTirePressure "左后轮胎胎压";
CM_ SG_ 1316 RHRTireTemperature "右后轮胎温度";
CM_ SG_ 1324 TirePositionWarning_LHFTire "左前方位轮胎胎压报警，含快速失压、低压、高压、高温。";
CM_ SG_ 1324 TirePositionWarning_RHFTire "右前方位轮胎胎压报警，含快速失压、低压、高压、高温。";
CM_ SG_ 1324 TirePositionWarning_LHRTire "左后方位轮胎胎压报警，含快速失压、低压、高压、高温。";
CM_ SG_ 1324 TirePositionWarning_RHRTire "右后方位轮胎胎压报警，含快速失压、低压、高压、高温。";
CM_ SG_ 1324 TirePressureWarningLampSts "胎压报警灯状态，含熄灭、闪烁（快速失压）、常亮（低压）三种状态";
CM_ SG_ 1324 TirePressureSystemFailSts "胎压系统故障";
CM_ SG_ 991 TMS_MotorLoopErrorLevel "Motor Loop Error Level
电驱回路故障等级";
CM_ SG_ 991 TMS_BatteryLoopErrorLevel "Battery Loop Error Level
电池回路故障等级";
CM_ SG_ 1188 FrontDeforestDisplaySts "前除霜工作指示灯
0x0:Off
0x1:On";
CM_ SG_ 1188 TMS_DisplayActive "空调信息显示状态
CLM检测到有面板击键或DVD控制命令，则发送active-1，DVD切屏显示空调信息；如果10秒没有检测到击键或命令，空调发_not_active-0，DVD停止显示空调信息；";
CM_ SG_ 1188 TMS_ZoneSelectionDisplaySts "Zone_Display_Status
空调温区状态显示";
CM_ SG_ 1188 TMS_AutoDisplaySts "Auto_Display_Status
空调自动状态显示";
CM_ SG_ 1188 TMS_FiltertchangeDisplaySts "Filter_replacement_reminder
滤芯重置提示";
CM_ SG_ 1188 TMS_AUTODefrostOnSts "AutoDefrost_Status
自动除雾开关状态";
CM_ SG_ 1188 TMS_AUTODefrostDisplaySts "When_the_AC_is_turned_on,_the_automatic_defogging_function_is_turned_on,_and_sends_this_signal
自动除雾工作状态";
CM_ SG_ 1188 TMS_RefInSufDispSts "Refrigerant_Insufficient_Display_Status
冷媒不足弹窗提醒";
CM_ SG_ 1188 TMS_CooltInSufDispSts "coolant_Insufficient_Display_Status
冷却液不足弹窗提醒";
CM_ SG_ 1188 TMS_DLOnOffSts "Driver_Left_On_Off_Status
主驾左出风口开关状态";
CM_ SG_ 1188 TMS_DROnOffSts "Driver_Right_On_Off_Status
主驾右出风口开关状态";
CM_ SG_ 1188 TMS_PLOnOffSts "Passenger_Left_On_Off_Status
副驾左出风口开关状态";
CM_ SG_ 1188 WorkingSts "Not_active-关闭空调
Active--打开空调
0x0:Off
0x1:On";
CM_ SG_ 1188 TMS_PROnOffSts "Passenger_Right_On_Off_Status
副驾右出风口开关状态";
CM_ SG_ 1188 TMS_DCOnOffSts "Driver_Center_On_Off_Status
中上出风口开关状态";
CM_ SG_ 1188 TMS_ACFastCool "AC_Fast_Cooling_Working_Status
空调极速降温工作状态";
CM_ SG_ 1188 TMS_ACFastHeat "AC_Fast_Heating_Working_Status
空调快速升温工作状态";
CM_ SG_ 1188 TMS_LoveRemind "Love_Remind_Working_Status
爱心提醒工作状态";
CM_ SG_ 1188 TMS_InteCleanCar "Intelligent_Clean_Car_Working_Status
智能除味工作状态";
CM_ SG_ 1188 TMS_ACVentilationSts "AC_Ventilation_Working_Status
新风系统通风状态";
CM_ SG_ 1188 TMS_AutoAirCleanSts "Auto_Air_Clean_Status
座舱自动清洁设置项状态";
CM_ SG_ 1188 PM25Sts "PM2.5_Status
0x0:Off
0x1:On";
CM_ SG_ 1188 TMS_ACModeCustomSts "AC_custom_mode_status_feedback
空调定制模式状态反馈";
CM_ SG_ 1188 TMS_ACRequestDisplaySts "AC请求指示
压缩机状态显示信号,和发给EMS的AC请求信号需区分开";
CM_ SG_ 1188 TMS_AUTODefLevelSts "AUTO_Defrost_Level_Status
自动除雾等级信息";
CM_ SG_ 1188 TMS_KeepWarm "Keep_Warm_Working_Status
恒温模式工作状态";
CM_ SG_ 1188 TMS_DSwingSts "Driver_Air_Swing_Mode_Status
主驾扫风模式显示";
CM_ SG_ 1188 TMS_PSwingSts "Passenge_rAir_Swing_Mode_Status
副驾扫风模式显示";
CM_ SG_ 1188 TMS_TuisongDispSts "Tuisong_Display_Status
不当操作体现";
CM_ SG_ 1188 TMS_SetTemperature_L_C "在单区模式下，调节左旋钮可以同时设定左右两边的温度设定。在双区模式下，左旋钮设定左区温度，右旋钮设定右区温度。
DVD未收到设定温值时，以及收到设定温值为startup_对应的1F时，DVD屏幕上温度显示区域均显示空白。";
CM_ SG_ 1188 TMS_ModeAdjustDisplaySts "Blower_Mode_Display_Status
出风模式现实状态";
CM_ SG_ 1188 TMS_CirculationModeDisplaySts "Circulation_Mode_Status
循环风门状态";
CM_ SG_ 1188 TMS_IncarTemp "Incar_Temperature
车内温度";
CM_ SG_ 1188 TMS_FliterLife "Fliter_Life
滤芯寿命";
CM_ SG_ 1188 TMS_DLSwingUpDwnWPosn "Driver_Left_Swing_Up_Down_Working_Position
主驾左上下扫风电机工作位置";
CM_ SG_ 1188 TMS_DLSwingLeRiWPosn "Driver_Left_Swing_Left_Right_Working_Position
主驾左左右扫风电机工作位置";
CM_ SG_ 1188 TMS_DRSwingUpDwnWPosn "Driver_Right_Swing_Up_Down_Working_Position
主驾右上下扫风电机工作位置";
CM_ SG_ 1188 TMS_DRSwingLeRiWPosn "Driver_Right_Swing_Left_Right_Working_Position
主驾右左右扫风电机工作位置";
CM_ SG_ 1188 TMS_PLSwingUpDwnWPosn "Passenger_Left_Swing_Up_Down_Working_Position
副驾左上下扫风电机工作位置";
CM_ SG_ 1188 TMS_PLSwingLeRiWPosn "Passenger_Left_Swing_Left_Right_Working_Position
副驾左左右扫风电机工作位置";
CM_ SG_ 1188 TMS_PRSwingUpDwnWPosn "Passenger_Right_Swing_Up_Down_Working_Position
副驾右上下扫风电机工作位置";
CM_ SG_ 1188 TMS_PRSwingLeRiWPosn "Passenger_Right_Swing_Left_Right_Working_Position
副驾右左右扫风电机工作位置";
CM_ SG_ 1188 TMS_DCSwingLeRiWPosn "Driver_Center_Swing_Left_Right_Working_Position
主驾中上左右扫风电机工作位置";
CM_ SG_ 1188 AirSwingSts "Air_Swing_Status
扫风状态显示";
CM_ SG_ 1188 BlowAdvanceOnSts "Blower_Advance_On_Status
鼓风机提前通风运行状态";
CM_ SG_ 1188 BlowDelayOffSts "Blower_Delay_Off_Status
鼓风机延迟关闭状态
0x0：开启延时
0x1：关闭延时";
CM_ SG_ 1188 TMS_PM25_ExtSts "External_PM2.5_sensor_fault_signal,_send_0X1_to_indicate_short_circuit_or_open_circuit_fault
车外PM2.5传感器故障状态";
CM_ SG_ 1188 TMS_PM25_IncarSts "Incar_PM2.5_sensor_fault_signal,_send_0X1_to_indicate_short_circuit_or_open_circuit_fault
车内PM2.5传感器故障状态";
CM_ SG_ 1188 TMS_AQS_Sts "Send_0X1_to_indicate_a_sensor_failure
AQS传感器故障状态";
CM_ SG_ 1188 PM25overproofDisplaySts "When_the_air_purification_is_not_turned_on_and_the_INcar_PM2.5_exceeds_the_upper_limit,_the_DVD_pop-up_window_prompts_the_user_to_turn_on_the_air_purification_function
PM2.5超标提醒";
CM_ SG_ 1188 AQSDisplaySts "AQS_Display_Status
AQS状态显示";
CM_ SG_ 1188 PM25AutoRunSts "When_the_air_quality_is_poor_and_the_air_purification_automatic_operation_setting_item_is_turned_on,This_signal_indicates_the_actual_working_mode_of_air_purification
PM2.5自动运行状态";
CM_ SG_ 1188 PM25AutoRunSetSts "Air_purification_automatic_operation_status_feedback
PM2.5自动运行开关状态";
CM_ SG_ 1188 FragranceWelcomeModeSts "Welcome_mode_status_feedback
迎宾模式状态反馈";
CM_ SG_ 1188 FragranceDisplaysts "Indicates_the_display_status_of_the_fragrance_interface";
CM_ SG_ 1188 TMS_AQS_Level "AQS_Level
AQS污染等级";
CM_ SG_ 1188 ACRequestCommand "AC_Request
AC请求指示";
CM_ SG_ 1188 PM25_Outcar_Level "Six_levels_of_out-car_air_quality_assessed_according_to_out-car_PM2.5
车外PM2.5等级";
CM_ SG_ 1188 PM25_Incar_Level "Six_levels_of_in-car_air_quality_assessed_according_to_in-car_PM2.5
车内PM2.5等级";
CM_ SG_ 1188 SetTemperature_L_F "SetLTemp_Fahrenheit";
CM_ SG_ 1188 SetTemperature_R_F "SetRTemp_Fahrenheit";
CM_ SG_ 1188 TMS_PM25_incar "In-car_PM2.5_value
车内PM2.5数值";
CM_ SG_ 1188 TMS_PM25_ext "OUTcar_PM2.5_value
车外PM2.5数值";
CM_ SG_ 1188 TMS_KeepWarmMemoryFb "Keep_Warm_Memory_Status
恒温模式记忆状态";
CM_ SG_ 612 EPB_R_1_CRC1 "Profile1A:E2E CRC (SAE J1850 CRC-8) for 8 Bytes
DataID:0x002B";
CM_ SG_ 612 EPB_R_1_RollgCntr1 "Profile1A:E2E Rolling message counter(the maximum value of Alive counter is 14)";
CM_ SG_ 612 EPB_1_FltLamp "EPB故障状态
诊断和转毂测试模式时闪烁";
CM_ SG_ 612 EPB_1_ParkLamp "EPB驻车灯状态
动态制动时闪烁";
CM_ SG_ 612 EPB_1_ActrSt "Current state of APB actuator connected to ECU
EPB卡钳执行状态

备注：
①一边夹紧一边释放，按博世最新平台策略，一按照Applied外发。
②0x5:CompletelyReleased（IPB2.0实际按照Reserved）
③0x6:Half Applied（IPB2.0实际按照Reserved）";
CM_ SG_ 612 EPB_1_RWUSt "EPB 后轮防抱死工作状态：
0x1:active仪表持续提示“紧急制动开启”且仪表红“P”灯闪烁，同时点亮制动尾灯，最后1帧信号显示完后结束";
CM_ SG_ 612 EPB_1_TextDisp "EPB文本提示
备注：
0x1:驻车坡度过大，请注意安全
0x2:IPB2.0实际按照Reserved
0x3:请关好车门并系好安全带
0x4:请同时踩下制动踏板
0x5:IPB2.0新增禁止P档手动释放EPB文字提示“请切换到非P档解除电子驻车”";
CM_ SG_ 612 IPB_EPBErrorStatus "用于EPB故障显示";
CM_ SG_ 1193 AVHWarningMessage "AVH Warning Message";
CM_ SG_ 1193 CDPActive "CDP Active";
CM_ SG_ 1193 HDCFailSts "After IGN OFF, this signal should be set to 0 for avoiding ICM HDC warning.";
CM_ SG_ 1193 HDCCtrlSts "HDC Ctrl Sts";
CM_ SG_ 1193 AVHSts "Auto Hold Status";
CM_ SG_ 1193 AVHFailSts "AVH Fail Status";
CM_ SG_ 1193 FWAWarningSts "FWA:Fading warning Assist
Indicate FWA state, dashboard need warn driver";
CM_ SG_ 1197 CST_Status "CST:Comfortable stop";
CM_ SG_ 1200 EBS_SOC "Battery state of charge calculated from IBS; 101-254 reserved;Invalid Raw Value:255.";
CM_ SG_ 1061 DriverSeatMsgStr_LvlSts "0x0:关
0x1:低
0x2:中
0x3:高";
CM_ SG_ 1061 DriverSeatMsg_ModeSts "0x0:无动作
0x1:脉冲模式
0x2:波浪模式
0x3:猫步模式
0x4:单排模式
0x5:交叉模式
0x6:蝶形模式
0x7:腰部按摩模式
0x8:蛇形模式
0x9:特殊模式1
0xA:特殊模式2
0xB:特殊模式3
0xC:特殊模式4";
CM_ SG_ 1065 LeftSeatMsgStr_LvlSts "0x0:关
0x1:低
0x2:中
0x3:高";
CM_ SG_ 1065 LeftSeatMsg_ModeSts "0x0:无动作
0x1:脉冲模式
0x2:波浪模式
0x3:猫步模式
0x4:单排模式
0x5:交叉模式
0x6:蝶形模式
0x7:腰部按摩模式
0x8:蛇形模式
0x9:特殊模式1
0xA:特殊模式2
0xB:特殊模式3
0xC:特殊模式4";
CM_ SG_ 1069 PassSeatMsgStr_LvlSts "0x0:关
0x1:低
0x2:中
0x3:高";
CM_ SG_ 1069 PassSeatMsg_ModeSts "0x0:无动作
0x1:脉冲模式
0x2:波浪模式
0x3:猫步模式
0x4:单排模式
0x5:交叉模式
0x6:蝶形模式
0x7:腰部按摩模式
0x8:蛇形模式
0x9:特殊模式1
0xA:特殊模式2
0xB:特殊模式3
0xC:特殊模式4";
CM_ SG_ 1087 RightSeatMsgStr_LvlSts "0x0:关
0x1:低
0x2:中
0x3:高";
CM_ SG_ 1087 RightSeatMsg_ModeSts "0x0:无动作
0x1:脉冲模式
0x2:波浪模式
0x3:猫步模式
0x4:单排模式
0x5:交叉模式
0x6:蝶形模式
0x7:腰部按摩模式
0x8:蛇形模式
0x9:特殊模式1
0xA:特殊模式2
0xB:特殊模式3
0xC:特殊模式4";
CM_ SG_ 1189 SRF_OperateSts "天窗玻璃运行状态";
CM_ SG_ 1189 SRF_PositionSts "天窗玻璃开度值";
CM_ SG_ 1189 SRF_OverHeatProtect "天窗过热保护激活状态";
CM_ SG_ 1189 SRF_Sunshade_OperateSts "遮阳帘状运行状态";
CM_ SG_ 1189 Sunshade_OverHeatProtect "遮阳帘过热保护激活状态";
CM_ SG_ 1192 SRF_Sunroof_ActualSts "天窗的实际状态";
CM_ SG_ 1192 SRF_Sunshade_ActualSts "遮阳帘的实际状态";
CM_ SG_ 1192 SRF_Sunshade_PositionSts "遮阳帘开度值";
CM_ SG_ 1143 OBC_CC_ConnectSts "CC connect states";
CM_ SG_ 1143 CDU_MILSts "CDU请求点亮MIL灯
OBD方案增加
0x1表示点亮MIL灯";
CM_ SG_ 1295 BMS_BattFaultLampSts "高压电池故障灯显示";
CM_ SG_ 1295 BMS_OverTemp_LightSts "BMS_OverTemp_LightSts";
CM_ SG_ 1295 BMS_RemainChg_Time "BMS_RemainChg_Time";
CM_ SG_ 1295 BMS_ThermalRunawayDis "Thermal run-away";
CM_ SG_ 1295 BMS_TBOXIsolationFault "battery insulation fault state";
CM_ SG_ 1295 BMS_PreWarmDis "preheat and keepwarm indication";
CM_ SG_ 1531 BMS_HvBattSoeActDisChaCyc "actual discahrge power acumulation in one driving cycle";
CM_ SG_ 1531 BMS_HvBattSoeActReChaCyc "actual recahrge power acumulation in one driving cycle";
CM_ SG_ 1531 BMS_HvBattRatedEnergy "battery  rated energy";
CM_ SG_ 1531 BMS_HvBattRatedU "battery  rated voltage";
CM_ SG_ 1531 BMS_HvBattTypeCode "battery type";
CM_ SG_ 1531 BMS_HvBattManufcCode "battery manufacture code";
CM_ SG_ 1531 BMS_HvBattTempSensorTotalNum "battery cell temperature sensor numbers";
CM_ SG_ 1531 BMS_HvBattTempSensorTempMaxNum "highest cell temperature sensor number";
CM_ SG_ 1531 BMS_HvBattTempSensorTempMinNum "lowest cell temperature sensor number";
CM_ SG_ 1531 BMS_HvBattTempMaxNum "highest temperature module number";
CM_ SG_ 1531 BMS_HvBattTempMinNum "lowest temperature module number";
CM_ SG_ 1531 BMS_BattCellTotalNum "battery cell numbers";
CM_ SG_ 1531 BMS_HvBattVoltMaxNum "highest cell voltage module number";
CM_ SG_ 1531 BMS_HvBattVoltMinNum "lowest cell voltage module number";
CM_ SG_ 1531 BMS_ActualSOCMin "最小真实SOC";
CM_ SG_ 1531 BMS_ActualSOCMax "最大真实SOC";
CM_ SG_ 1224 BMS_HvBattCellVoltMax_Num "highest voltage cell number";
CM_ SG_ 1224 BMS_HvBattCellVoltMax "highest cell voltage";
CM_ SG_ 1224 BMS_HvBattCellVoltMin_Num "lowest voltage cell number";
CM_ SG_ 1224 BMS_HvBattCellVoltMin "lowest cell voltage";
CM_ SG_ 1224 BMS_Chg_Sts "BMS_Chg_Sts";
CM_ SG_ 1235 EPS_2_Steer_ReturnRmd_Sts "Steer  wheeel return Sts(捷途D01）";
CM_ SG_ 1235 EPS_2_Steer_ReturnRmd "Steer  wheeel return remind(捷途D01）";
CM_ SG_ 1235 EPS_2_MFS_ShakeSts "方向盘震动反馈(捷途D01）";
CM_ SG_ 1330 DWD_TextDisp "报警提示内容";
CM_ SG_ 1330 DWD_SoundIndcn "报警声音提示";
CM_ SG_ 1330 LSensorFailSts "0x0：传感器正常
0x1：传感器故障";
CM_ SG_ 1330 RSensorFailSts "0x0：传感器正常
0x1：传感器故障";
CM_ SG_ 1330 DWD_Distance "报警距离分段";
CM_ SG_ 1330 DWD_Switch "涉水雷达开关状态";
CM_ SG_ 1328 RADAR_1_RadarDetectSts "雷达探测状态
当发01，IHU_以前探头音讯蜂鸣扬声器；
当发10，IHU_以后探头音讯蜂鸣扬声器
ICM_接收此信号，但前_后探头均用一种音讯蜂鸣。";
CM_ SG_ 1328 RADAR_1_RadarWorkSts "雷达系统工作状态
1、Active:当打开PAS_开关或打到倒文件，雷达模块开始工作，此时发1，
IHU_接收到后即便用户未打开IHU，也会通过此信号自动点亮屏幕；
2、Not_Active:当不在倒档且PAS_开关关闭，或者车速大于15km_h_时，发0(Not_Active)。
3、自检提示音:雷达工作状态位由0_变化为1_时，仪表根据探头状态信息发出相应提示音，如果探头有故障则长鸣2_秒提示探头故障，如果探头没有故障则鸣叫，0.5_秒提示雷达进入工作状态。";
CM_ SG_ 1328 RADAR_1_Resd1 "Profile1A:E2E Reserved";
CM_ SG_ 1328 RADAR_1_LHRRadarSensorDistance "左后探头信息
自检故障:发送Sensor_Err
自检正常或雷达待机:发送0x3
E正常测距:距离=(D)*5+25
无障碍物:发送0x3E
0x20~0x3D:无效数据";
CM_ SG_ 1328 RADAR_1_RHMRRadarSensorDistance "右中后探头信息
自检故障:发送Sensor_Err
自检正常或雷达待机:发送0x3
E正常测距:距离=(D)*5+25
无障碍物:发送0x3E
0x20~0x3D:无效数据";
CM_ SG_ 1328 RADAR_1_LHMRRadarSensorDistance "左中后探头信息
自检故障:发送Sensor_Err
自检正常或雷达待机:发送0x3
E正常测距:距离=(D)*5+25
无障碍物:发送0x3E
0x20~0x3D:无效数据";
CM_ SG_ 1328 RADAR_1_RHRRadarSensorDistance "右后探头信息
自检故障:发送Sensor_Err
自检正常或雷达待机:发送0x3
E正常测距:距离=(D)*5+25
无障碍物:发送0x3E
0x20~0x3D:无效数据";
CM_ SG_ 1328 RADAR_1_LHFRadarSensorDistance "左前探头信息
自检故障:发送Sensor_Err
自检正常或雷达待机:发送0x3
E正常测距:距离=(D)*5+25
无障碍物:发送0x1E
0x20~0x3D:无效数据";
CM_ SG_ 1328 RADAR_1_RHFRadarSensorDistance "右前探头信息
自检故障:发送Sensor_Err
自检正常或雷达待机:发送0x3
E正常测距:距离=(D)*5+25
无障碍物:发送0x1E
0x20~0x3D:无效数据";
CM_ SG_ 1328 RADAR_1_RHMFRadarSensorDistance "右中前探头信息
自检故障:发送Sensor_Err
自检正常或雷达待机:发送0x1E
正常测距:距离=(D)*5+25
无障碍物:发送0x1E
低配雷达(后4_探头):发送0x1E
0x1C~0x1D:无效数据";
CM_ SG_ 1328 RADAR_1_LHMFRadarSensorDistance "左中前探头信息
自检故障:发送Sensor_Err
自检正常或雷达待机:发送0x1E
正常测距:距离=(D)*5+25
无障碍物:发送0x1E
低配雷达(后4_探头):发送0x1E
0x1C~0x1D:无效数据";
CM_ SG_ 1328 RADAR_1_AudibleBeepRate "报警频率
1、自检过程或雷达待机时发送Startup
2、进入测距模式后:发送频率信息
3、自检提示音见
RadarWorkSts_详细说明";
CM_ SG_ 259 EMS_EngineSpeed_Actual "PHEV:Actual Engine speed send by EMS to HCU";
CM_ SG_ 1234 FRZCU_FRSeatHeiFb "副驾座椅高度调节目标位置";
CM_ SG_ 1234 FRZCU_FRSeatLvlFb "副驾座椅水平调节目标值";
CM_ SG_ 1234 FRZCU_FRSeatBackAgFb "副驾座椅靠背角度调节目标值";
CM_ SG_ 1234 FRZCU_FRSeatLegSpprtFb "副驾座椅腿托";
CM_ SG_ 1234 FRZCU_FRWinSts "右前车窗运行状态反馈";
CM_ SG_ 1234 FRZCU_RRWinSts "右后车窗运行状态反馈";
CM_ SG_ 1234 FRZCU_FRSeatLegRestAngleFb "副驾座椅腿托延伸调节目标";
CM_ SG_ 1234 FRZCU_FRSeatCushFb "副驾座椅坐垫角度调节目标";
CM_ SG_ 1234 FRZCU_FRSeatNeedMemory "副驾座椅记忆弹框请求";
CM_ SG_ 1234 FRZCU_FRMemoryFb "副驾记忆保存状态";
CM_ SG_ 1234 FRZCU_FRRecoverFb "副驾记忆恢复状态";
CM_ SG_ 1234 FRZCU_EasyEntryExitFb "副驾便捷进入\离车";
CM_ SG_ 1234 FRZCU_EnjoyableSeatWarning "一键尊享警示提示";
CM_ SG_ 1234 FRZCU_EnjoyableSeatSts "一键尊享状态反馈";
CM_ SG_ 1234 SeatHeatLevelsFR "座椅加热-副驾";
CM_ SG_ 1234 SeatVentLevelsFR "座椅通风-副驾";
CM_ SG_ 1234 SeatHeatLevelsRR "座椅加热-二排右侧";
CM_ SG_ 1234 SeatVentLevelsRR "座椅通风-二排右侧";
CM_ SG_ 1234 FRZCU_FRSeatFoldFb "副驾座椅放倒调节目标";
CM_ SG_ 517 MFSR_Voice_SW "语音唤醒";
CM_ SG_ 1096 TMS_AirPurgeReminderSts "空气净化提醒开关状态";
CM_ SG_ 1096 TMS_BT_Reduce_Wind_SpeedSts "蓝牙通话降低风速状态";
CM_ SG_ 1096 TMS_First_BlowingSts "空调启动时第一口风状态";
CM_ SG_ 1096 TMS_CirculationInTunnelsSts "隧道内循环状态";
CM_ SG_ 1096 TMS_crosscountry_coolingSts "越野散热状态";
CM_ SG_ 1096 TMS_ParkingAirConditioningStatus "驻车空调状态工作状态";
CM_ SG_ 1096 TMS_CoolantFillSts "一键除气";
CM_ SG_ 1096 TMS_UVC_ControlSts "UVC控制反馈";
CM_ SG_ 1096 TMS_UVC_LuminanceSts "UVC亮度反馈";
CM_ SG_ 1096 TMS_ICC_Lightoff_Sts "香氛氛围灯开关状态";
CM_ SG_ 1096 TMS_ICC_Memoff_Sts "香氛记忆开关状态";
CM_ SG_ 1096 TMS_keepwarmSet_TemperatureSts "恒温模式温度设置";
CM_ SG_ 1096 TMS_BiochemicalFuncSts "生化功能开关反馈";
CM_ SG_ 1096 TMS_TimedVentilationSts "大屏定时换气开关状态反馈";
CM_ SG_ 1240 TMS_CFSSwitchFb "香氛系统开关设置反馈";
CM_ SG_ 1240 TDU_CFSPosOneType "香氛位置1香型";
CM_ SG_ 1240 TDU_CFSPosTwoType "香氛位置2香型";
CM_ SG_ 1240 TDU_CFSPosThreeType "香氛位置3香型";
CM_ SG_ 1240 TDU_CFSRunOut "香氛已用完提醒";
CM_ SG_ 1240 TMS_CFSShortWarn "香氛不足提醒";
CM_ SG_ 1240 TMS_CFSLevelSetFb "香氛工作浓度";
CM_ SG_ 1240 TMS_CFSPosSetFb "香氛工作位置反馈";
CM_ SG_ 1240 TMS_CFSPosOneLife "通道一香氛寿命";
CM_ SG_ 1240 TMS_CFSPosTwoLife "通道二香氛寿命";
CM_ SG_ 1240 TMS_CFSPosThreeLife "通道三香氛寿命";
CM_ SG_ 1240 TMS_PM25SwitchFb "PM2.5状态反馈";
CM_ SG_ 1240 TMS_ThrModeStsFb "三排模式反馈";
CM_ SG_ 1240 TMS_ThrSetTempFb_C "三排温度反馈";
CM_ SG_ 1240 TMS_ThrCLMSwitchFb "三排空调状态反馈";
CM_ SG_ 1240 TMS_ThrAutoSwitchFb "空调自动状态显示";
CM_ SG_ 1240 TMS_ThrBlowSpeedLevelKeyStsFb "三排鼓风机档位";
CM_ SG_ 638 FRZCU_HoodSts "前舱盖状态";
CM_ SG_ 638 FRZCU_PowerMode "低压电源状态";
CM_ SG_ 638 SeatLength_target_Passenger "座椅水平位置调节";
CM_ SG_ 638 SeatBackrest_target_Passenger "座椅靠背角度调节";
CM_ SG_ 638 FrontBackSpeedAdj_Cmd "Front_Back_Speed_Adjust_Command
座椅前后调节速度信号";
CM_ SG_ 638 FRZCU_GloveboxSW "上报手套箱开关状态";
CM_ SG_ 638 FRZCU_FRReleaseLockSts "右前电释放状态
0x0:None
0x1:已释放
0x2:释放中
0x3:已复位
0x4:复位中";
CM_ SG_ 638 FRZCU_RRReleaseLockSts "右后电释放状态
0x0:None
0x1:已释放
0x2:释放中
0x3:已复位
0x4:复位中";
CM_ SG_ 638 FRZCU_PELockInKeyWarning "PE闭锁车内有钥匙提醒";
CM_ SG_ 638 FRZCU_PowerOFFWarning "电源下电提醒";
CM_ SG_ 638 FRZCU_KeylessWarning "无合法钥匙提醒";
CM_ SG_ 638 FRZCU_OTAPwrDwnReqFb "OTA_Power_Down_Request_FeedBack";
CM_ SG_ 638 FRZCU_OTAPwrOnReqFb "OTA_Power_On_Request_FeedBack";
CM_ SG_ 949 PEPS_InformationSource "To_show_the_lock/unlock_information_is_from_Smart_or_RKE_.";
CM_ SG_ 949 PEPS_OrderInformation "PEPS_do_not_add_any_additional_logic._Just_reflect_the_status_of_the_switch_state.";
CM_ SG_ 949 PEPS_KeySts "PEPS钥匙位置状态";
CM_ SG_ 949 PEPS_ETRUnLockReq "尾门靠近解锁请求";
CM_ SG_ 1028 PEPS_WelcomeON "welcome_light_request
迎宾开启请求";
CM_ SG_ 1028 PEPS_VehicleSearchReq "寻车请VehicleSearchRequest
寻车请求";
CM_ SG_ 1028 PEPS_SATOReminder "Easy_trunk_function_start_light
进入后备箱区域激活ETR功能闪灯信号";
CM_ SG_ 1028 PEPS_PLGUnlockReq "PLG解锁指令";
CM_ SG_ 1028 PEPS_RKETrunkSts "实体钥匙尾门按键";
CM_ SG_ 1028 PEPS_SSBInhibitCWCSts "OFF档时点按SSB，发送1值。
OFF档，CWC接收到SSBInhibitCWCSts=1后屏蔽无线充电功能；";
CM_ SG_ 1028 PEPS_WirelessChargingCtrSts "发送1时，PEPS处于搜索遥控钥匙的状态，无线充电功能应关闭";
CM_ SG_ 1028 PEPS_EmgyShutdown "Emergency_shut_down._If_happen_,Send_three_frame_continuous_signal_1
此信号代表发生过紧急熄火功能。如果没发生都是发0，如果发生了，连续发3帧1出来。";
CM_ SG_ 1028 PEPS_SSBInputFailure "The_warning_indicator_the_SSB_is_faulty";
CM_ SG_ 1028 PEPS_SmartSystemWarning1_1 "非OFF档关门钥匙不在车内报警";
CM_ SG_ 1028 PEPS_SmartSystemWarning2_2 "车速无钥匙报警";
CM_ SG_ 1028 PEPS_SmartSystemWarning3_1 "钥匙电池电量低报警";
CM_ SG_ 1028 PEPS_SmartSystemWarning3_2 "用于SSB启动时，非P档时启动报警";
CM_ SG_ 1028 PEPS_SmartSystemWarning4_2 "用于SSB启动时，未踩刹车提醒报警";
CM_ SG_ 1028 PEPS_SmartSystemWarning4_3 "下电不在P档报警";
CM_ SG_ 1028 PEPS_SystemWarning "PEPS系统故障提醒";
CM_ SG_ 1028 PEPS_BLTKeyPESts "蓝牙钥匙的PE功能开启关闭状态信号";
CM_ SG_ 1291 BMS_2_G_CRC "Profile1A:E2E CRC (SAE J1850 CRC-8) for 8 Bytes
DataID:0x0075";
CM_ SG_ 1291 BMS_2_G_RollgCntr "Profile1A:E2E Rolling message counter(the maximum value of Alive counter is 14)";
CM_ SG_ 1291 BMS_2_G_Resd "Profile1A:E2E Reserved";
CM_ SG_ 1291 BMS_TBOXInsulation_R "insulation resistance";
CM_ SG_ 1291 BMS_TBOXErrorNumber "BMS Error Numbers";
CM_ SG_ 1291 BMS_TBOXHvBattMaxT "battery max temperature";
CM_ SG_ 1291 BMS_TBOXHvBattMinT "battery min temperature";
CM_ SG_ 1291 BMS_SOCLight "BMS_SOCLight
SOC电量显示（仪表显示）";
CM_ SG_ 1104 RLCR_2_CRC1 "Profile1A:E2E CRC (SAE J1850 CRC-8) for 8 Bytes
DataID:0x0045";
CM_ SG_ 1104 RLCR_2_RollgCntr1 "Profile1A:E2E Rolling message counter(the maximum value of Alive counter is 14)";
CM_ SG_ 1104 RLCR_2_Resd1 "Profile1A:E2E Reserved";
CM_ SG_ 1104 RLCR_2_RCWWarn "Rear Collision Warning Warning";
CM_ SG_ 1104 RLCR_2_RCTAWarn "RCTA Warning（高配不发）";
CM_ SG_ 1104 RLCR_2_BSDLCWONOFFSts "BSD/LCA Switch status";
CM_ SG_ 1104 RLCR_2_DOWONOFFSts "Door open warning Switch status";
CM_ SG_ 1104 RLCR_2_RCWONOFFSts "Rear Collision Warning Switch Status";
CM_ SG_ 1104 RLCR_2_RCTARCTBONOFFSts "RCTA/RCTB Switch status（高配不发，低配无0x2）";
CM_ SG_ 1271 RRCR_2_CRC1 "Profile1A:E2E CRC (SAE J1850 CRC-8) for 8 Bytes
DataID:0x0047";
CM_ SG_ 1271 RRCR_2_RollgCntr1 "Profile1A:E2E Rolling message counter(the maximum value of Alive counter is 14)";
CM_ SG_ 1271 RRCR_2_Resd1 "Profile1A:E2E Reserved";
CM_ SG_ 1271 RRCR_2_RCWWarn "Rear Collision Warning Warning";
CM_ SG_ 1271 RRCR_2_RCTAWarn "FCTA Warning";
CM_ SG_ 1271 RRCR_2_BSDLCWONOFFSts "BSD/LCA Switch status";
CM_ SG_ 1271 RRCR_2_DOWONOFFSts "Door open warning Switch status";
CM_ SG_ 1271 RRCR_2_RCWONOFFSts "Rear Collision Warning Switch Status";
CM_ SG_ 1271 RRCR_2_RCTARCTBONOFFSts "RCTA/RCTB Switch status";
CM_ SG_ 587 ONEBOX_4_LHFWheelSpeedRPM "left front Wheel Speed(the unit is RPM)";
CM_ SG_ 587 ONEBOX_4_RHFWheelSpeedRPM "right front  Wheel Speed(the unit is RPM)";
CM_ SG_ 587 LHRWheelSpeedRPM "Left Rear Wheel Speed(the unit is RPM)";
CM_ SG_ 587 RHRWheelSpeedRPM "right Rear  Wheel Speed(the unit is RPM)";
CM_ SG_ 587 LHRPulseCounterFailSts "left rear wheel Pulse Counter Fail Status";
CM_ SG_ 587 LHRPulseCounter "left rear wheel Pulse Counter";
CM_ SG_ 587 RHRPulseCounterFailSts "right rear wheel Pulse Counter FailSts";
CM_ SG_ 587 RHRPulseCounter "right rear wheel Pulse Counter";
CM_ SG_ 587 RHFPulseCounterFailSts "right front wheel Pulse Counter FailSts";
CM_ SG_ 587 RHFPulseCounter "right front wheel Pulse Counter";
CM_ SG_ 587 LHFPulseCounterFailSts "left front wheel Pulse Counter FailSts";
CM_ SG_ 587 LHFPulseCounter "left front wheel Pulse Counter";
CM_ SG_ 587 LHFWheelDriveDirection "left front Wheel Drive Direction";
CM_ SG_ 587 RHFWheelDriveDirection "right front Wheel Speed Drive Direction";
CM_ SG_ 587 LHRWheelDriveDirection "left rear Wheel Speed Drive Direction";
CM_ SG_ 587 RHRWheelDriveDirection "right rear Wheel Speed Drive Direction";
CM_ SG_ 1338 FMCU_ErrLvlDis "Error Level";
CM_ SG_ 1338 FMCU_SpdAct_EDR "FMCU motor actual speed";
CM_ SG_ 777 ISGF_ErrLvl "Error Level";
CM_ SG_ 1403 RMCU_ErrLvlDis "Error Level";
CM_ SG_ 1403 RMCU_Speed_EDR "RMCU motor actual speed";
CM_ SG_ 1299 BMS_PackVoltageDis "Battery Voltage（高压后的表显电压，不上高压发0）";
CM_ SG_ 1299 BMS_PackCurrentDis "Battery Current(direction:discharge+ charge -)";
CM_ SG_ 1099 ISGF_SysTempOvrInd "Indicator of overheat warning lamp（捷途D01不使用）";
CM_ SG_ 1130 TCU_23_GBFaultstatus "Activation gearbox error Lamp, only for ICM including LCD to light LED and LCD. This signal should be sent with “AGErrorLamp” simultaneously";
CM_ SG_ 1130 TCU_23_TeachInState "TCU自学习状态";
CM_ SG_ 1180 ACU_1_ThdRowLBeltWarning "With Occupancy detection：
Third row (left) safety belt status
0x0:not occupied/occupied and fastened
0x1:occupied and not fastened 
Without Occupancy detection：
0x0:Seat belt is fastened
0x1:Seat belt is not fastened";
CM_ SG_ 1180 ACU_1_ThdRowRBeltWarning "With Occupancy detection：
Third row (right) safety belt status
0x0:not occupied/occupied and fastened
0x1:occupied and not fastened 
Without Occupancy detection：
0x0:Seat belt is fastened
0x1:Seat belt is not fastened";
CM_ SG_ 1180 ACU_1_PsngrSeatBeltWarning "In addition to the corresponding value sent by ACU with copilot safety belt alarm, the signal sent by ACU without alarm configuration sends the startup value.
The signal is judged in combination with SBR";
CM_ SG_ 1180 ACU_1_SecRowLBeltWarning "With Occupancy detection：
Second row (left) safety belt status
0x0:not occupied/occupied and fastened
0x1:occupied and not fastened 
Without Occupancy detection：
0x0:Seat belt is fastened
0x1:Seat belt is not fastened";
CM_ SG_ 1180 ACU_1_SecRowMBeltWarning "With Occupancy detection：
Second row (middle) safety belt status
0x0:not occupied/occupied and fastened
0x1:occupied and not fastened 
Without Occupancy detection：
0x0:Seat belt is fastened
0x1:Seat belt is not fastened";
CM_ SG_ 1180 ACU_1_SecRowRBeltWarning "With Occupancy detection：
Second row (right) safety belt status
0x0:not occupied/occupied and fastened
0x1:occupied and not fastened 
Without Occupancy detection：
0x0:Seat belt is fastened
0x1:Seat belt is not fastened";
CM_ SG_ 1180 ACU_1_PsngrSeatOccupiedSts "副驾座椅占位状态，0为未占位，1为占位
E03：国内\国际非欧盟一、二阶段都体现，类欧盟\欧盟不分阶段都体现；
E0Y：国内\国际非欧盟，类欧盟\欧盟都体现；
0x2:open circuit (03仅欧盟、类欧盟做，0Y都做)
0x3:short circuit (03仅欧盟、类欧盟做，0Y都做)";
CM_ SG_ 1341 BMS_44_PackPowerRealTime "捷途新增动力电池包实时功率";
CM_ SG_ 811 BMS_Chg_Sts "BMS_Chg_Sts";
CM_ SG_ 1269 LISDShowCMDSts "ISD灯光开启状态";
CM_ SG_ 1269 LISDShowModeSts "ISD灯光模式状态";
CM_ SG_ 1269 LISD_TransmitStatus "灯具反馈信息：反馈当前数据帧是否接收成功、数据校验是否正确、图片显示是否成功。";
CM_ SG_ 1269 LISD_DisplayStatus "灯具反馈信息：反馈当前图片显示状态。";
CM_ SG_ 1269 LISD_ParkingShowModSts "LISD驻车动画状态反馈";
CM_ SG_ 1269 LISD_ParkingShowCMDSts "驻车动画开关反馈";
CM_ SG_ 1233 RISDShowCMDSts "ISD灯光开启状态";
CM_ SG_ 1233 RISDShowModeSts "ISD灯光模式状态";
CM_ SG_ 1233 RISD_TransmitStatus "灯具反馈信息：反馈当前数据帧是否接收成功、数据校验是否正确、图片显示是否成功。";
CM_ SG_ 1233 RISD_DisplayStatus "灯具反馈信息：反馈当前图片显示状态。";
CM_ SG_ 1233 RISD_ParkingShowModSts "RISD驻车动画状态反馈";
CM_ SG_ 1233 RISD_ParkingShowCMDSts "驻车动画开关反馈";
CM_ SG_ 1169 LC_DIYMusicShowModSts "固定灯光秀状态反馈信号";
CM_ SG_ 1169 LC_RandomMusicShowSts "随机灯光秀状态反馈信号";
CM_ SG_ 1169 LC_LiShowModSts "解闭锁模式状态反馈信号";
CM_ SG_ 1427 ILCF_1_LogoParkingSts "前LOGO驻车点亮开关状态反馈";
CM_ SG_ 1427 ILCF_1_LogoChargingSts "前LOGO充电灯效开关状态反馈";
CM_ SG_ 1427 ILCF_1_DIYMusicShowModSts "固定灯光秀状态反馈信号";
CM_ SG_ 1427 ILCF_1_RandomMusicShowSts "随机灯光秀状态反馈信号";
CM_ SG_ 1427 ILCF_1_LogoColorAdjSts "Logo灯颜色设置反馈，1-256分别对应256种颜色";
CM_ SG_ 821 ADS_5_CRC1 "Profile1A:E2E CRC (SAE J1850 CRC-8) for 8 Bytes
DataID:No ASIL requirements.Not configure
CRC Reserved.";
CM_ SG_ 821 ADS_5_RollgCntr1 "Profile1A:E2E Rolling message counter(the maximum value of Alive counter is 14)";
CM_ SG_ 821 ADS_5_Resd1 "Profile1A:E2E Reserved";
CM_ SG_ 821 ADS_5_ILOASts "智慧躲闪功能执行状态";
CM_ SG_ 821 ADS_5_ICAQuitReason "ICA 退出原因";
CM_ SG_ 821 ADS_5_ISLISt "超速报警功能状态";
CM_ SG_ 821 ADS_5_ILOATextInfo "智慧躲闪提示信息";
CM_ SG_ 821 ADS_5_ILOAActdirection "智慧躲闪方向";
CM_ SG_ 821 ADS_5_LKS_warning "LKS声音报警信号";
CM_ SG_ 821 ADS_5_ISLIOverSpeedWarn "超速报警状态";
CM_ SG_ 821 ADS_5_ISLISpeedLimitSign "限速标志值";
CM_ SG_ 821 ADS_5_EgoLeftLineHeatgAg "自车中心线与本车道
 车道线的夹角";
CM_ SG_ 821 ADS_5_EgoLeLineID "左侧车道线有效信号";
CM_ SG_ 821 ADS_5_EgoLeLineColor "本车道左侧车道线颜色";
CM_ SG_ 821 ADS_5_EgoLeLineTyp "本车道左侧车道线类型";
CM_ SG_ 821 ADS_5_EgoLeLineHozlDst "自车中心线与本车道左侧车道线横向距离";
CM_ SG_ 821 ADS_5_CRC2 "Profile1A:E2E CRC (SAE J1850 CRC-8) for 8 Bytes
DataID:No ASIL requirements.Not configure
CRC Reserved.";
CM_ SG_ 821 ADS_5_RollgCntr2 "Profile1A:E2E Rolling message counter(the maximum value of Alive counter is 14)";
CM_ SG_ 821 ADS_5_Resd2 "Profile1A:E2E Reserved";
CM_ SG_ 821 ADS_5_NeborLeLineID "左侧相邻车道线有效信号";
CM_ SG_ 821 ADS_5_NeborLeLineColor "左侧相邻车道线颜色";
CM_ SG_ 821 ADS_5_NeborLeLineTyp "左侧相邻车道线类型";
CM_ SG_ 821 ADS_5_EgoLeLineCrvt "本车道左侧车道线曲率";
CM_ SG_ 821 ADS_5_NeborLeLineHozlDst "自车中心线与左侧相邻车 
 道线横向距离";
CM_ SG_ 821 ADS_5_NeborRiLineID "右侧相邻车道线有效信号";
CM_ SG_ 821 ADS_5_NeborRiLineColor "右侧相邻车道线颜色";
CM_ SG_ 821 ADS_5_NeborRiLineTyp "右侧相邻车道线类型";
CM_ SG_ 821 ADS_5_NeborLeLineCrvt "左侧相邻车道线曲率";
CM_ SG_ 821 ADS_5_NeborRiLineHozlDst "自车中心线与右侧相邻车 
 道线横向距离";
CM_ SG_ 821 ADS_5_CRC3 "Profile1A:E2E CRC (SAE J1850 CRC-8) for 8 Bytes
DataID:No ASIL requirements.Not configure
CRC Reserved.";
CM_ SG_ 821 ADS_5_RollgCntr3 "Profile1A:E2E Rolling message counter(the maximum value of Alive counter is 14)";
CM_ SG_ 821 ADS_5_Resd3 "Profile1A:E2E Reserved";
CM_ SG_ 821 ADS_5_ELKSettingSt "ELK功能设置状态反馈";
CM_ SG_ 821 ADS_5_LDWLDPSnvtySet "车道偏离敏感度反馈";
CM_ SG_ 821 ADS_5_LDWWarnType "LDW/LDP报警方式反馈";
CM_ SG_ 821 ADS_5_NeborRiLineCrvt "右侧相邻车道线曲率";
CM_ SG_ 821 ADS_5_IESSwtSet "智慧躲闪反馈开关（预留默认开）";
CM_ SG_ 821 ADS_5_IHCSettingSt "智能远光辅助开关反馈";
CM_ SG_ 821 ADS_5_ISLIWarningMod "智能限速提醒方式反馈";
CM_ SG_ 821 ADS_5_ICAEnableBtnSts "ICA功能使能开关反馈（车道居中辅助）";
CM_ SG_ 821 ADS_5_EgoRiLineID "右侧车道线有效信号";
CM_ SG_ 821 ADS_5_EgoRiLineTyp "本车道右侧车道线类型";
CM_ SG_ 821 ADS_5_EgoRiLineColor "本车道右侧车道线颜色";
CM_ SG_ 821 ADS_5_EgoRiLineHozlDst "自车中心线与本车道右侧车道线横向距离";
CM_ SG_ 821 ADS_5_CRC4 "Profile1A:E2E CRC (SAE J1850 CRC-8) for 8 Bytes
DataID:No ASIL requirements.Not configure
CRC Reserved.";
CM_ SG_ 821 ADS_5_RollgCntr4 "Profile1A:E2E Rolling message counter(the maximum value of Alive counter is 14)";
CM_ SG_ 821 ADS_5_Resd4 "Profile1A:E2E Reserved";
CM_ SG_ 821 ADS_5_EgoRightLineHeatgAg "自车中心线与本车道右侧车道线的夹角";
CM_ SG_ 821 ADS_5_EgoRiLineCrvt "本车道右侧车道线曲率";
CM_ SG_ 821 ADS_5_NeborLeftLineHeatgAg "自车中心线与相邻车道左侧车道线的夹角";
CM_ SG_ 821 ADS_5_NeborRightLineHeatgAg "自车中心线与相邻车道右侧车道线的夹角";
CM_ SG_ 819 ADS_4_CRC1 "Profile1A:E2E CRC (SAE J1850 CRC-8) for 8 Bytes
DataID:No ASIL requirements.Not configure
CRC Reserved.";
CM_ SG_ 819 ADS_4_RollgCntr1 "Profile1A:E2E Rolling message counter(the maximum value of Alive counter is 14)";
CM_ SG_ 819 ADS_4_Resd1 "Profile1A:E2E Reserved";
CM_ SG_ 819 ADS_4_AEBStatus "AEB功能状态";
CM_ SG_ 819 ADS_4_ACCSts "ACC功能状态";
CM_ SG_ 819 ADS_4_TimeGapSet "跟车时距";
CM_ SG_ 819 ADS_4_FcwMode "FCW功能状态";
CM_ SG_ 819 ADS_4_AEBReqType "AEB请求类型";
CM_ SG_ 819 ADS_4_SetSpd "巡航车速";
CM_ SG_ 819 ADS_4_DAIStatus "起步提醒功能状态";
CM_ SG_ 819 ADS_4_ACCTextMessage "ACC提示信息";
CM_ SG_ 819 ADS_4_LongiTakeOverReq "接管请求";
CM_ SG_ 819 ADS_4_SetSpdUnit "巡航车速单位";
CM_ SG_ 819 ADS_4_GoNotifier "起步提醒文言";
CM_ SG_ 819 ADS_4_DAISts "起步提醒功能执行状态";
CM_ SG_ 819 ADS_4_Radar_textinfo "雷达提示信息";
CM_ SG_ 819 ADS_4_SCF_PopoverReq "智能限速辅助弹窗提醒";
CM_ SG_ 819 ADS_4_DrvrCfmSCFDispFb "SCF 驾驶员确认信号 （确认后，setspeed变为摄像头限速值）";
CM_ SG_ 819 ADS_4_SCF_SpdLimUnit "智能限速辅助单位";
CM_ SG_ 819 ADS_4_SCF_SpdLimSts "智能限速辅助功能状态";
CM_ SG_ 819 ADS_4_CRC2 "Profile1A:E2E CRC (SAE J1850 CRC-8) for 8 Bytes
DataID:No ASIL requirements.Not configure
CRC Reserved.";
CM_ SG_ 819 ADS_4_RollgCntr2 "Profile1A:E2E Rolling message counter(the maximum value of Alive counter is 14)";
CM_ SG_ 819 ADS_4_Resd2 "Profile1A:E2E Reserved";
CM_ SG_ 819 ADS_4_ACCObjTyp "跟车目标类型";
CM_ SG_ 819 ADS_4_FrntFarObjTyp "前前车目标类型";
CM_ SG_ 819 ADS_4_ACCObjLgtDstX "跟车目标纵向距离";
CM_ SG_ 819 ADS_4_FrntFarObjID "前前车有效性";
CM_ SG_ 819 ADS_4_ACCObjID "跟车目标有效性";
CM_ SG_ 819 ADS_4_ACCObjHozDstY "跟车目标横向距离";
CM_ SG_ 819 ADS_4_FrntFarObjHozDstY "前前车横向距离";
CM_ SG_ 819 ADS_4_FrntFarObjLgtDstX "前前车纵向距离";
CM_ SG_ 819 ADS_4_CRC3 "Profile1A:E2E CRC (SAE J1850 CRC-8) for 8 Bytes
DataID:No ASIL requirements.Not configure
CRC Reserved.";
CM_ SG_ 819 ADS_4_RollgCntr3 "Profile1A:E2E Rolling message counter(the maximum value of Alive counter is 14)";
CM_ SG_ 819 ADS_4_Resd3 "Profile1A:E2E Reserved";
CM_ SG_ 819 ADS_4_LeObjID "左边车辆类型有效性";
CM_ SG_ 819 ADS_4_LeObjTyp "左边车辆类型";
CM_ SG_ 819 ADS_4_LeObjHozDstY "左边车辆横向距离";
CM_ SG_ 819 ADS_4_LeObjLgtDstX "左边车辆纵向距离";
CM_ SG_ 819 ADS_4_RiObjID "右边车辆类型有效性";
CM_ SG_ 819 ADS_4_RiObjTyp "右边车辆类型";
CM_ SG_ 819 ADS_4_RiObjHozDstY "右边车辆横向距离";
CM_ SG_ 819 ADS_4_RiObjLgtDstX "右边车辆纵向距离";
CM_ SG_ 819 ADS_4_CRC4 "Profile1A:E2E CRC (SAE J1850 CRC-8) for 8 Bytes
DataID:No ASIL requirements.Not configure
CRC Reserved.";
CM_ SG_ 819 ADS_4_RollgCntr4 "Profile1A:E2E Rolling message counter(the maximum value of Alive counter is 14)";
CM_ SG_ 819 ADS_4_Resd4 "Profile1A:E2E Reserved";
CM_ SG_ 819 ADS_4_SCFSwtSet "智能限速辅助反馈开关（预留默认开）";
CM_ SG_ 819 ADS_4_AEBSettingSt "AEB功能设置状态反馈";
CM_ SG_ 819 ADS_4_FCWSettingSt "FCW功能设置状态反馈";
CM_ SG_ 819 ADS_4_DAISwtSet "驶离提醒开关（预留默认开）";
CM_ SG_ 819 ADS_4_CruiseAccelerateSts "巡航跟车加减速状态指示，低配用于HMI显示";
CM_ SG_ 1172 ExternalTemperature_F "External_temperature（F）（外部温度（华氏度））";
CM_ SG_ 1172 ExternalTemperature_C "External_temperature（℃）
Invalid:_When_external_temperature_is_fail,_the_signal_value_is_0xFE.";
CM_ SG_ 1172 BlowSpeedLevelDisplaySts "Blow_Speed_Level_feedback
鼓风机档位
0xB:Auto后面要加这个属性";
CM_ SG_ 1147 CCP_1_FLTempSwitchReq "按下触摸到抬起一次，20ms信号有效的时候连发3帧，后期周期间隔100ms，按照当前状态发送";
CM_ SG_ 1147 CCP_1_FrontAutoACSwitchReq "前排自动功能";
CM_ SG_ 1147 CCP_1_FrontOFFSwitchReq "前排空调关闭";
CM_ SG_ 1147 CCP_1_FBlowSpdCtrlSwitchReq "前排风速";
CM_ SG_ 1147 FLCCP_MainSetHeatReq "主驾座椅加热";
CM_ SG_ 1147 FLCCP_MainSetVentilationReq "主驾座椅通风";
CM_ SG_ 1147 CCP_1_ACFastCool "一键制冷请求";
BA_DEF_ BO_  "GenMsgCycleTimeFast" INT 0 50000;
BA_DEF_ BO_  "GenMsgNrOfRepetition" INT 0 999999;
BA_DEF_ BO_  "GenMsgDelayTime" INT 0 1000;
BA_DEF_ BO_  "VFrameFormat" ENUM  "StandardCAN","ExtendedCAN","reserved","reserved","reserved","reserved","reserved","reserved","reserved","reserved","reserved","reserved","reserved","reserved","StandardCAN_FD","ExtendedCAN_FD";
BA_DEF_ BO_  "GenMsgILSupport" ENUM  "No","Yes";
BA_DEF_ BO_  "NmMessage" ENUM  "No","Yes";
BA_DEF_ BO_  "GenMsgSendType" ENUM  "Cycle","Event","IfActive","CE","CA","NoMsgSendType";
BA_DEF_ BO_  "GenMsgCycleTime" INT 0 50000;
BA_DEF_ BO_  "CANFD_BRS" INT 0 1;
BA_DEF_ BO_  "NmAsrMessage" ENUM  "No","Yes";
BA_DEF_ BO_  "GRC_ASIL" ENUM  "vector_leerstring","QM","A","B","C","D";
BA_DEF_ BO_  "GRC_History" STRING ;
BA_DEF_ SG_  "GenSigStartValue" FLOAT 0 100000000000;
BA_DEF_ SG_  "GenSigInactiveValue" INT 0 100000;
BA_DEF_ SG_  "GenSigInvalidValue" INT 0 100000;
BA_DEF_ SG_  "GenSigSendType" ENUM  "Cycle","OnChange","OnWrite","IfActive","OnChangeWithRepetition","OnWriteWithRepetition","IfActiveWithRepetition","NoSigSendType","OnChangeAndIfActive","OnChangeAndIfActiveWithRepetition","CA","CE","Event";
BA_DEF_ SG_  "GRC_Sig_ASIL" ENUM  "vector_leerstring","QM","A","B","C","D";
BA_DEF_ SG_  "E2EDataId" INT 0 0;
BA_DEF_ SG_  "E2EProfile" STRING ;
BA_DEF_ SG_  "E2EDataLength" INT 0 512;
BA_DEF_DEF_  "GenMsgCycleTimeFast" 0;
BA_DEF_DEF_  "GenMsgNrOfRepetition" 0;
BA_DEF_DEF_  "GenMsgDelayTime" 0;
BA_DEF_DEF_  "VFrameFormat" "StandardCAN";
BA_DEF_DEF_  "GenMsgILSupport" "No";
BA_DEF_DEF_  "NmMessage" "No";
BA_DEF_DEF_  "GenMsgSendType" "NoMsgSendType";
BA_DEF_DEF_  "GenMsgCycleTime" 0;
BA_DEF_DEF_  "CANFD_BRS" 0;
BA_DEF_DEF_  "NmAsrMessage" "No";
BA_DEF_DEF_  "GRC_ASIL" "";
BA_DEF_DEF_  "GRC_History" "";
BA_DEF_DEF_  "GenSigStartValue" 0;
BA_DEF_DEF_  "GenSigInactiveValue" 0;
BA_DEF_DEF_  "GenSigInvalidValue" 0;
BA_DEF_DEF_  "GenSigSendType" "NoSigSendType";
BA_DEF_DEF_  "GRC_Sig_ASIL" "";
BA_DEF_DEF_  "E2EDataId" 0;
BA_DEF_DEF_  "E2EProfile" "";
BA_DEF_DEF_  "E2EDataLength" 0;
BA_ "CANFD_BRS" BO_ 1316 1;
BA_ "GenMsgSendType" BO_ 1316 0;
BA_ "GenMsgCycleTime" BO_ 1316 500;
BA_ "GenMsgILSupport" BO_ 1316 1;
BA_ "VFrameFormat" BO_ 1316 14;
BA_ "CANFD_BRS" BO_ 1324 1;
BA_ "GenMsgSendType" BO_ 1324 0;
BA_ "GenMsgCycleTime" BO_ 1324 500;
BA_ "GenMsgILSupport" BO_ 1324 1;
BA_ "GRC_ASIL" BO_ 1324 3;
BA_ "VFrameFormat" BO_ 1324 14;
BA_ "CANFD_BRS" BO_ 991 1;
BA_ "GenMsgSendType" BO_ 991 0;
BA_ "GenMsgCycleTime" BO_ 991 50;
BA_ "GenMsgILSupport" BO_ 991 1;
BA_ "VFrameFormat" BO_ 991 14;
BA_ "CANFD_BRS" BO_ 1188 1;
BA_ "GenMsgSendType" BO_ 1188 0;
BA_ "GenMsgCycleTime" BO_ 1188 100;
BA_ "GenMsgILSupport" BO_ 1188 1;
BA_ "GRC_History" BO_ 1188 "[{'approvedBy':'贾少辉','author':'吴慧','changesComments':'同步史文妍GL网段：根据热管理TMS罗康燕反馈\nBlowDelayOffSts备注更新为“0x0：开启延时，0x1：关闭延时”，ICC接收','date':'2025/3/31','ecu':'TMS_3(0x4A4)','ecuName':'ICC','reviewedBy':'杨华','revisio";
BA_ "VFrameFormat" BO_ 1188 14;
BA_ "CANFD_BRS" BO_ 612 1;
BA_ "GenMsgSendType" BO_ 612 0;
BA_ "GenMsgCycleTime" BO_ 612 20;
BA_ "GenMsgILSupport" BO_ 612 1;
BA_ "GRC_History" BO_ 612 "[{'approvedBy':'贾少辉','author':'吴慧','changesComments':'ONEBOX新增发送EpbSwt（EPB开关状态）、EcdActvSts（动态减速激活状态）、EPB_RwuAvl（动态减速接口可用）、ESC_EpbAvl（EPB驻车接口可用状态）无接收端','date':'2025/3/10','ecu':'EPB_R_1(0x264)','ecuName'";
BA_ "VFrameFormat" BO_ 612 14;
BA_ "CANFD_BRS" BO_ 1193 1;
BA_ "GenMsgSendType" BO_ 1193 0;
BA_ "GenMsgCycleTime" BO_ 1193 100;
BA_ "GenMsgILSupport" BO_ 1193 1;
BA_ "GRC_ASIL" BO_ 1193 3;
BA_ "GRC_History" BO_ 1193 "[{'approvedBy':'贾少辉','author':'吴慧','changesComments':'（同步T1J华为智驾版更改）汪苇CH网段-新增发送ONEBOX_2_G_TAB_Active坦克掉头反馈信号，无接收端','date':'2025/3/10','ecu':'ONEBOX_2_G(0x4A9)','ecuName':'CGW','reviewedBy':'杨华','revision':'V2.3'}]";
BA_ "VFrameFormat" BO_ 1193 14;
BA_ "CANFD_BRS" BO_ 1197 1;
BA_ "GenMsgSendType" BO_ 1197 0;
BA_ "GenMsgCycleTime" BO_ 1197 100;
BA_ "GenMsgILSupport" BO_ 1197 1;
BA_ "VFrameFormat" BO_ 1197 14;
BA_ "CANFD_BRS" BO_ 1200 1;
BA_ "GenMsgSendType" BO_ 1200 0;
BA_ "GenMsgCycleTime" BO_ 1200 100;
BA_ "GenMsgILSupport" BO_ 1200 1;
BA_ "VFrameFormat" BO_ 1200 14;
BA_ "CANFD_BRS" BO_ 1061 1;
BA_ "GenMsgSendType" BO_ 1061 0;
BA_ "GenMsgCycleTime" BO_ 1061 100;
BA_ "GenMsgILSupport" BO_ 1061 1;
BA_ "VFrameFormat" BO_ 1061 14;
BA_ "CANFD_BRS" BO_ 1065 1;
BA_ "GenMsgSendType" BO_ 1065 0;
BA_ "GenMsgCycleTime" BO_ 1065 100;
BA_ "GenMsgILSupport" BO_ 1065 1;
BA_ "VFrameFormat" BO_ 1065 14;
BA_ "CANFD_BRS" BO_ 1069 1;
BA_ "GenMsgSendType" BO_ 1069 0;
BA_ "GenMsgCycleTime" BO_ 1069 100;
BA_ "GenMsgILSupport" BO_ 1069 1;
BA_ "VFrameFormat" BO_ 1069 14;
BA_ "CANFD_BRS" BO_ 1087 1;
BA_ "GenMsgSendType" BO_ 1087 0;
BA_ "GenMsgCycleTime" BO_ 1087 100;
BA_ "GenMsgILSupport" BO_ 1087 1;
BA_ "VFrameFormat" BO_ 1087 14;
BA_ "CANFD_BRS" BO_ 1189 1;
BA_ "GenMsgSendType" BO_ 1189 0;
BA_ "GenMsgCycleTime" BO_ 1189 100;
BA_ "GenMsgILSupport" BO_ 1189 1;
BA_ "VFrameFormat" BO_ 1189 14;
BA_ "CANFD_BRS" BO_ 1192 1;
BA_ "GenMsgSendType" BO_ 1192 0;
BA_ "GenMsgCycleTime" BO_ 1192 100;
BA_ "GenMsgILSupport" BO_ 1192 1;
BA_ "VFrameFormat" BO_ 1192 14;
BA_ "CANFD_BRS" BO_ 1143 1;
BA_ "GenMsgSendType" BO_ 1143 0;
BA_ "GenMsgCycleTime" BO_ 1143 100;
BA_ "GenMsgILSupport" BO_ 1143 1;
BA_ "VFrameFormat" BO_ 1143 14;
BA_ "CANFD_BRS" BO_ 1295 1;
BA_ "GenMsgSendType" BO_ 1295 0;
BA_ "GenMsgCycleTime" BO_ 1295 500;
BA_ "GenMsgILSupport" BO_ 1295 1;
BA_ "VFrameFormat" BO_ 1295 14;
BA_ "CANFD_BRS" BO_ 1531 1;
BA_ "GenMsgSendType" BO_ 1531 0;
BA_ "GenMsgCycleTime" BO_ 1531 1000;
BA_ "GenMsgILSupport" BO_ 1531 1;
BA_ "VFrameFormat" BO_ 1531 14;
BA_ "CANFD_BRS" BO_ 1224 1;
BA_ "GenMsgSendType" BO_ 1224 0;
BA_ "GenMsgCycleTime" BO_ 1224 100;
BA_ "GenMsgILSupport" BO_ 1224 1;
BA_ "VFrameFormat" BO_ 1224 14;
BA_ "CANFD_BRS" BO_ 1235 1;
BA_ "GenMsgSendType" BO_ 1235 0;
BA_ "GenMsgCycleTime" BO_ 1235 100;
BA_ "GenMsgILSupport" BO_ 1235 1;
BA_ "VFrameFormat" BO_ 1235 14;
BA_ "CANFD_BRS" BO_ 1330 1;
BA_ "GenMsgSendType" BO_ 1330 0;
BA_ "GenMsgCycleTime" BO_ 1330 100;
BA_ "GenMsgILSupport" BO_ 1330 1;
BA_ "VFrameFormat" BO_ 1330 14;
BA_ "CANFD_BRS" BO_ 1328 1;
BA_ "GenMsgSendType" BO_ 1328 0;
BA_ "GenMsgCycleTime" BO_ 1328 100;
BA_ "GenMsgILSupport" BO_ 1328 1;
BA_ "GRC_History" BO_ 1328 "[{'approvedBy':'贾少辉','author':'吴慧','changesComments':'史文妍BD2网段删除该节点，ICC删除接收，矩阵预留（预留BD2-GL-IC路由）','date':'2025/3/10','ecu':'RADAR_1(0x530)','ecuName':'ICC','reviewedBy':'杨华','revision':'V3.0'}]";
BA_ "VFrameFormat" BO_ 1328 14;
BA_ "CANFD_BRS" BO_ 259 1;
BA_ "GenMsgSendType" BO_ 259 0;
BA_ "GenMsgCycleTime" BO_ 259 10;
BA_ "GenMsgILSupport" BO_ 259 1;
BA_ "VFrameFormat" BO_ 259 14;
BA_ "CANFD_BRS" BO_ 1234 1;
BA_ "GenMsgSendType" BO_ 1234 0;
BA_ "GenMsgCycleTime" BO_ 1234 100;
BA_ "GenMsgILSupport" BO_ 1234 1;
BA_ "VFrameFormat" BO_ 1234 14;
BA_ "CANFD_BRS" BO_ 517 1;
BA_ "GenMsgSendType" BO_ 517 0;
BA_ "GenMsgCycleTime" BO_ 517 20;
BA_ "GenMsgILSupport" BO_ 517 1;
BA_ "VFrameFormat" BO_ 517 14;
BA_ "CANFD_BRS" BO_ 1096 1;
BA_ "GenMsgSendType" BO_ 1096 0;
BA_ "GenMsgCycleTime" BO_ 1096 100;
BA_ "GenMsgILSupport" BO_ 1096 1;
BA_ "GRC_History" BO_ 1096 "[{'approvedBy':'贾少辉','author':'吴慧','changesComments':'史文妍GL网段：根据热管理TMS魏成贤需求（LSB 37 69 66被T1J FL2华为智驾版占用）\n1、新增2个信号TMS_RemotekeySts、TMS_TimedVentilationReasSts无接收端，为TMS观测信号；\n2、新增2个信号TMS_BiochemicalFu";
BA_ "VFrameFormat" BO_ 1096 14;
BA_ "CANFD_BRS" BO_ 1240 1;
BA_ "GenMsgSendType" BO_ 1240 0;
BA_ "GenMsgCycleTime" BO_ 1240 100;
BA_ "GenMsgILSupport" BO_ 1240 1;
BA_ "VFrameFormat" BO_ 1240 14;
BA_ "CANFD_BRS" BO_ 638 1;
BA_ "GenMsgSendType" BO_ 638 0;
BA_ "GenMsgCycleTime" BO_ 638 20;
BA_ "GenMsgILSupport" BO_ 638 1;
BA_ "VFrameFormat" BO_ 638 14;
BA_ "CANFD_BRS" BO_ 949 1;
BA_ "GenMsgSendType" BO_ 949 3;
BA_ "GenMsgCycleTime" BO_ 949 50;
BA_ "GenMsgCycleTimeFast" BO_ 949 50;
BA_ "GenMsgNrOfRepetition" BO_ 949 3;
BA_ "GenMsgDelayTime" BO_ 949 5;
BA_ "GenMsgILSupport" BO_ 949 1;
BA_ "VFrameFormat" BO_ 949 14;
BA_ "CANFD_BRS" BO_ 1028 1;
BA_ "GenMsgSendType" BO_ 1028 3;
BA_ "GenMsgCycleTime" BO_ 1028 100;
BA_ "GenMsgCycleTimeFast" BO_ 1028 50;
BA_ "GenMsgNrOfRepetition" BO_ 1028 3;
BA_ "GenMsgDelayTime" BO_ 1028 5;
BA_ "GenMsgILSupport" BO_ 1028 1;
BA_ "VFrameFormat" BO_ 1028 14;
BA_ "CANFD_BRS" BO_ 1291 1;
BA_ "GenMsgSendType" BO_ 1291 0;
BA_ "GenMsgCycleTime" BO_ 1291 500;
BA_ "GenMsgILSupport" BO_ 1291 1;
BA_ "VFrameFormat" BO_ 1291 14;
BA_ "CANFD_BRS" BO_ 1104 1;
BA_ "GenMsgSendType" BO_ 1104 0;
BA_ "GenMsgCycleTime" BO_ 1104 100;
BA_ "GenMsgILSupport" BO_ 1104 1;
BA_ "GRC_History" BO_ 1104 "[{'approvedBy':'贾少辉','author':'吴慧','changesComments':'匹配华为MDC需求，重新编制DA矩阵，矩阵预留（预留DA-DK路由）','date':'2025/3/10','ecu':'RLCR_2(0x450)','ecuName':'ICC','reviewedBy':'杨华','revision':'V3.0'}]";
BA_ "VFrameFormat" BO_ 1104 14;
BA_ "CANFD_BRS" BO_ 1271 1;
BA_ "GenMsgSendType" BO_ 1271 0;
BA_ "GenMsgCycleTime" BO_ 1271 100;
BA_ "GenMsgILSupport" BO_ 1271 1;
BA_ "GRC_History" BO_ 1271 "[{'approvedBy':'贾少辉','author':'吴慧','changesComments':'匹配华为MDC需求，重新编制DA矩阵，矩阵预留（预留DA-DK路由）','date':'2025/3/10','ecu':'RRCR_2(0x4F7)','ecuName':'ICC','reviewedBy':'杨华','revision':'V3.0'}]";
BA_ "VFrameFormat" BO_ 1271 14;
BA_ "CANFD_BRS" BO_ 587 1;
BA_ "GenMsgSendType" BO_ 587 0;
BA_ "GenMsgCycleTime" BO_ 587 20;
BA_ "GenMsgILSupport" BO_ 587 1;
BA_ "GRC_ASIL" BO_ 587 5;
BA_ "VFrameFormat" BO_ 587 14;
BA_ "CANFD_BRS" BO_ 1338 1;
BA_ "GenMsgSendType" BO_ 1338 0;
BA_ "GenMsgCycleTime" BO_ 1338 500;
BA_ "GenMsgILSupport" BO_ 1338 1;
BA_ "GRC_History" BO_ 1338 "[{'approvedBy':'贾少辉','author':'吴慧','changesComments':'（同步T1J华为智驾版更改）冯夏新PT网段-FMCU新增发送FMCU_1_G_ISGMotWorkState信号，无接收','date':'2025/3/10','ecu':'FMCU_1_G(0x53A)','ecuName':'CGW','reviewedBy':'杨华','revision':'V2.3'}]";
BA_ "VFrameFormat" BO_ 1338 14;
BA_ "CANFD_BRS" BO_ 777 1;
BA_ "GenMsgSendType" BO_ 777 0;
BA_ "GenMsgCycleTime" BO_ 777 50;
BA_ "GenMsgILSupport" BO_ 777 1;
BA_ "VFrameFormat" BO_ 777 14;
BA_ "CANFD_BRS" BO_ 1403 1;
BA_ "GenMsgSendType" BO_ 1403 0;
BA_ "GenMsgCycleTime" BO_ 1403 500;
BA_ "GenMsgILSupport" BO_ 1403 1;
BA_ "VFrameFormat" BO_ 1403 14;
BA_ "CANFD_BRS" BO_ 1299 1;
BA_ "GenMsgSendType" BO_ 1299 0;
BA_ "GenMsgCycleTime" BO_ 1299 500;
BA_ "GenMsgILSupport" BO_ 1299 1;
BA_ "VFrameFormat" BO_ 1299 14;
BA_ "CANFD_BRS" BO_ 1099 1;
BA_ "GenMsgSendType" BO_ 1099 0;
BA_ "GenMsgCycleTime" BO_ 1099 100;
BA_ "GenMsgILSupport" BO_ 1099 1;
BA_ "GRC_History" BO_ 1099 "[{'approvedBy':'贾少辉','author':'吴慧','changesComments':'冯夏欣PT网段更新部分信号的备注，以及ISGF_SysTempOvrInd和ISGF_HVILFault（捷途D01不使用）','date':'2025/3/14','ecu':'ISGF_4(0x44B)','ecuName':'ICC','reviewedBy':'杨华','revision':'V2.3'}]";
BA_ "VFrameFormat" BO_ 1099 14;
BA_ "CANFD_BRS" BO_ 1130 1;
BA_ "GenMsgSendType" BO_ 1130 0;
BA_ "GenMsgCycleTime" BO_ 1130 100;
BA_ "GenMsgILSupport" BO_ 1130 1;
BA_ "VFrameFormat" BO_ 1130 14;
BA_ "CANFD_BRS" BO_ 1180 1;
BA_ "GenMsgSendType" BO_ 1180 0;
BA_ "GenMsgCycleTime" BO_ 1180 100;
BA_ "GenMsgILSupport" BO_ 1180 1;
BA_ "GRC_History" BO_ 1180 "[{'approvedBy':'贾少辉','author':'吴慧','changesComments':'（同步D01主项目V2.3.1版本更新）李思思BBCM新增接收ACU_1_PsngrSeatOccupiedSts信号，判断占位情况','date':'2025/5/6','ecu':'ACU_1(0x49C)','ecuName':'BBCM','reviewedBy':'杨华','revision':'V3.2'}]";
BA_ "VFrameFormat" BO_ 1180 14;
BA_ "CANFD_BRS" BO_ 1248 1;
BA_ "GenMsgSendType" BO_ 1248 3;
BA_ "GenMsgCycleTime" BO_ 1248 100;
BA_ "GenMsgCycleTimeFast" BO_ 1248 10;
BA_ "GenMsgNrOfRepetition" BO_ 1248 5;
BA_ "GenMsgDelayTime" BO_ 1248 5;
BA_ "GenMsgILSupport" BO_ 1248 1;
BA_ "VFrameFormat" BO_ 1248 14;
BA_ "CANFD_BRS" BO_ 1341 1;
BA_ "GenMsgSendType" BO_ 1341 0;
BA_ "GenMsgCycleTime" BO_ 1341 100;
BA_ "GenMsgILSupport" BO_ 1341 1;
BA_ "VFrameFormat" BO_ 1341 14;
BA_ "CANFD_BRS" BO_ 811 1;
BA_ "GenMsgSendType" BO_ 811 0;
BA_ "GenMsgCycleTime" BO_ 811 50;
BA_ "GenMsgILSupport" BO_ 811 1;
BA_ "VFrameFormat" BO_ 811 14;
BA_ "CANFD_BRS" BO_ 1269 1;
BA_ "GenMsgSendType" BO_ 1269 0;
BA_ "GenMsgCycleTime" BO_ 1269 100;
BA_ "GenMsgILSupport" BO_ 1269 1;
BA_ "VFrameFormat" BO_ 1269 14;
BA_ "CANFD_BRS" BO_ 1233 1;
BA_ "GenMsgSendType" BO_ 1233 0;
BA_ "GenMsgCycleTime" BO_ 1233 100;
BA_ "GenMsgILSupport" BO_ 1233 1;
BA_ "VFrameFormat" BO_ 1233 14;
BA_ "CANFD_BRS" BO_ 1169 1;
BA_ "GenMsgSendType" BO_ 1169 0;
BA_ "GenMsgCycleTime" BO_ 1169 100;
BA_ "GenMsgILSupport" BO_ 1169 1;
BA_ "VFrameFormat" BO_ 1169 14;
BA_ "CANFD_BRS" BO_ 1427 1;
BA_ "GenMsgSendType" BO_ 1427 0;
BA_ "GenMsgCycleTime" BO_ 1427 100;
BA_ "GenMsgILSupport" BO_ 1427 1;
BA_ "VFrameFormat" BO_ 1427 14;
BA_ "CANFD_BRS" BO_ 821 1;
BA_ "GenMsgSendType" BO_ 821 0;
BA_ "GenMsgCycleTime" BO_ 821 50;
BA_ "GenMsgILSupport" BO_ 821 1;
BA_ "GRC_History" BO_ 821 "[{'approvedBy':'贾少辉','author':'吴慧','changesComments':'匹配华为MDC需求，重新编制DA矩阵，矩阵预留（预留DA-DK路由）','date':'2025/3/10','ecu':'ADS_5(0x335)','ecuName':'ICC,DVR','reviewedBy':'杨华','revision':'V3.0'}]";
BA_ "VFrameFormat" BO_ 821 14;
BA_ "CANFD_BRS" BO_ 819 1;
BA_ "GenMsgSendType" BO_ 819 0;
BA_ "GenMsgCycleTime" BO_ 819 50;
BA_ "GenMsgILSupport" BO_ 819 1;
BA_ "GRC_History" BO_ 819 "[{'approvedBy':'贾少辉','author':'吴慧','changesComments':'匹配华为MDC需求，重新编制DA矩阵，矩阵预留（预留DA-DK路由）','date':'2025/3/10','ecu':'ADS_4(0x333)','ecuName':'ICC','reviewedBy':'杨华','revision':'V3.0'}]";
BA_ "VFrameFormat" BO_ 819 14;
BA_ "CANFD_BRS" BO_ 1172 1;
BA_ "GenMsgSendType" BO_ 1172 0;
BA_ "GenMsgCycleTime" BO_ 1172 100;
BA_ "GenMsgILSupport" BO_ 1172 1;
BA_ "VFrameFormat" BO_ 1172 14;
BA_ "CANFD_BRS" BO_ 1147 1;
BA_ "GenMsgSendType" BO_ 1147 3;
BA_ "GenMsgCycleTime" BO_ 1147 100;
BA_ "GenMsgCycleTimeFast" BO_ 1147 20;
BA_ "GenMsgNrOfRepetition" BO_ 1147 3;
BA_ "GenMsgDelayTime" BO_ 1147 5;
BA_ "GenMsgILSupport" BO_ 1147 1;
BA_ "GRC_History" BO_ 1147 "[{'approvedBy':'贾少辉','author':'吴慧','changesComments':'刘标ICC需求新增接收CCP_1_ACFastCool一键制冷请求，D01P使用','date':'2025/3/10','ecu':'CCP_1(0x47B)','ecuName':'ICC','reviewedBy':'杨华','revision':'V2.3'}]";
BA_ "VFrameFormat" BO_ 1147 14;
BA_ "GenSigSendType" SG_ 1316 LHFTireTemperature 0;
BA_ "GenSigInvalidValue" SG_ 1316 LHFTireTemperature 255;
BA_ "GenSigSendType" SG_ 1316 RHFTireTemperature 0;
BA_ "GenSigInvalidValue" SG_ 1316 RHFTireTemperature 255;
BA_ "GenSigSendType" SG_ 1316 LHRTireTemperature 0;
BA_ "GenSigInvalidValue" SG_ 1316 LHRTireTemperature 255;
BA_ "GenSigSendType" SG_ 1316 LHFTirePressure 0;
BA_ "GenSigInvalidValue" SG_ 1316 LHFTirePressure 255;
BA_ "GenSigSendType" SG_ 1316 RHFTirePressure 0;
BA_ "GenSigInvalidValue" SG_ 1316 RHFTirePressure 255;
BA_ "GenSigSendType" SG_ 1316 LHRTirePressure 0;
BA_ "GenSigInvalidValue" SG_ 1316 LHRTirePressure 255;
BA_ "GenSigSendType" SG_ 1316 RHRTirePressure 0;
BA_ "GenSigInvalidValue" SG_ 1316 RHRTirePressure 255;
BA_ "GenSigSendType" SG_ 1316 RHRTireTemperature 0;
BA_ "GenSigInvalidValue" SG_ 1316 RHRTireTemperature 255;
BA_ "GenSigSendType" SG_ 1324 TirePositionWarning_LHFTire 0;
BA_ "GenSigSendType" SG_ 1324 TirePositionWarning_RHFTire 0;
BA_ "GenSigSendType" SG_ 1324 TirePositionWarning_LHRTire 0;
BA_ "GenSigSendType" SG_ 1324 TirePositionWarning_RHRTire 0;
BA_ "GRC_Sig_ASIL" SG_ 1324 TirePressureWarningLampSts 3;
BA_ "GenSigSendType" SG_ 1324 TirePressureWarningLampSts 0;
BA_ "GRC_Sig_ASIL" SG_ 1324 TirePressureSystemFailSts 3;
BA_ "GenSigSendType" SG_ 1324 TirePressureSystemFailSts 0;
BA_ "GenSigSendType" SG_ 991 TMS_MotorLoopErrorLevel 0;
BA_ "GenSigSendType" SG_ 991 TMS_BatteryLoopErrorLevel 0;
BA_ "GenSigSendType" SG_ 1188 FrontDeforestDisplaySts 0;
BA_ "GenSigSendType" SG_ 1188 TMS_DisplayActive 0;
BA_ "GenSigSendType" SG_ 1188 TMS_ZoneSelectionDisplaySts 0;
BA_ "GenSigSendType" SG_ 1188 TMS_AutoDisplaySts 0;
BA_ "GenSigSendType" SG_ 1188 TMS_FiltertchangeDisplaySts 0;
BA_ "GenSigSendType" SG_ 1188 TMS_AUTODefrostOnSts 0;
BA_ "GenSigSendType" SG_ 1188 TMS_AUTODefrostDisplaySts 0;
BA_ "GenSigSendType" SG_ 1188 TMS_RefInSufDispSts 0;
BA_ "GenSigSendType" SG_ 1188 TMS_CooltInSufDispSts 0;
BA_ "GenSigSendType" SG_ 1188 TMS_DLOnOffSts 0;
BA_ "GenSigSendType" SG_ 1188 TMS_DROnOffSts 0;
BA_ "GenSigSendType" SG_ 1188 TMS_PLOnOffSts 0;
BA_ "GenSigSendType" SG_ 1188 WorkingSts 0;
BA_ "GenSigSendType" SG_ 1188 TMS_PROnOffSts 0;
BA_ "GenSigSendType" SG_ 1188 TMS_DCOnOffSts 0;
BA_ "GenSigSendType" SG_ 1188 TMS_ACFastCool 0;
BA_ "GenSigSendType" SG_ 1188 TMS_ACFastHeat 0;
BA_ "GenSigSendType" SG_ 1188 TMS_LoveRemind 0;
BA_ "GenSigSendType" SG_ 1188 TMS_InteCleanCar 0;
BA_ "GenSigSendType" SG_ 1188 TMS_ACVentilationSts 0;
BA_ "GenSigSendType" SG_ 1188 TMS_AutoAirCleanSts 0;
BA_ "GenSigSendType" SG_ 1188 PM25Sts 0;
BA_ "GenSigSendType" SG_ 1188 TMS_ACModeCustomSts 0;
BA_ "GenSigSendType" SG_ 1188 TMS_ACRequestDisplaySts 0;
BA_ "GenSigSendType" SG_ 1188 TMS_AUTODefLevelSts 0;
BA_ "GenSigSendType" SG_ 1188 TMS_KeepWarm 0;
BA_ "GenSigSendType" SG_ 1188 TMS_DSwingSts 0;
BA_ "GenSigSendType" SG_ 1188 TMS_PSwingSts 0;
BA_ "GenSigSendType" SG_ 1188 TMS_TuisongDispSts 0;
BA_ "GenSigSendType" SG_ 1188 TMS_SetTemperature_L_C 0;
BA_ "GenSigInvalidValue" SG_ 1188 TMS_SetTemperature_L_C 31;
BA_ "GenSigStartValue" SG_ 1188 TMS_SetTemperature_L_C 31;
BA_ "GenSigSendType" SG_ 1188 TMS_SetTemperature_R_C 0;
BA_ "GenSigInvalidValue" SG_ 1188 TMS_SetTemperature_R_C 31;
BA_ "GenSigStartValue" SG_ 1188 TMS_SetTemperature_R_C 31;
BA_ "GenSigSendType" SG_ 1188 TMS_ModeAdjustDisplaySts 0;
BA_ "GenSigStartValue" SG_ 1188 TMS_ModeAdjustDisplaySts 5;
BA_ "GenSigSendType" SG_ 1188 TMS_CirculationModeDisplaySts 0;
BA_ "GenSigStartValue" SG_ 1188 TMS_CirculationModeDisplaySts 1;
BA_ "GenSigSendType" SG_ 1188 TMS_IncarTemp 0;
BA_ "GenSigStartValue" SG_ 1188 TMS_IncarTemp 254;
BA_ "GenSigSendType" SG_ 1188 TMS_FliterLife 0;
BA_ "GenSigSendType" SG_ 1188 TMS_DLSwingUpDwnWPosn 0;
BA_ "GenSigInvalidValue" SG_ 1188 TMS_DLSwingUpDwnWPosn 127;
BA_ "GenSigSendType" SG_ 1188 TMS_DLSwingLeRiWPosn 0;
BA_ "GenSigInvalidValue" SG_ 1188 TMS_DLSwingLeRiWPosn 127;
BA_ "GenSigSendType" SG_ 1188 TMS_DRSwingUpDwnWPosn 0;
BA_ "GenSigInvalidValue" SG_ 1188 TMS_DRSwingUpDwnWPosn 127;
BA_ "GenSigSendType" SG_ 1188 TMS_DRSwingLeRiWPosn 0;
BA_ "GenSigInvalidValue" SG_ 1188 TMS_DRSwingLeRiWPosn 127;
BA_ "GenSigSendType" SG_ 1188 TMS_PLSwingUpDwnWPosn 0;
BA_ "GenSigInvalidValue" SG_ 1188 TMS_PLSwingUpDwnWPosn 127;
BA_ "GenSigSendType" SG_ 1188 TMS_PLSwingLeRiWPosn 0;
BA_ "GenSigInvalidValue" SG_ 1188 TMS_PLSwingLeRiWPosn 127;
BA_ "GenSigSendType" SG_ 1188 TMS_PRSwingUpDwnWPosn 0;
BA_ "GenSigInvalidValue" SG_ 1188 TMS_PRSwingUpDwnWPosn 127;
BA_ "GenSigSendType" SG_ 1188 TMS_PRSwingLeRiWPosn 0;
BA_ "GenSigInvalidValue" SG_ 1188 TMS_PRSwingLeRiWPosn 127;
BA_ "GenSigSendType" SG_ 1188 TMS_DCSwingLeRiWPosn 0;
BA_ "GenSigInvalidValue" SG_ 1188 TMS_DCSwingLeRiWPosn 127;
BA_ "GenSigSendType" SG_ 1188 AirSwingSts 0;
BA_ "GenSigSendType" SG_ 1188 TemperatureUnit 0;
BA_ "GenSigSendType" SG_ 1188 BlowAdvanceOnSts 0;
BA_ "GenSigSendType" SG_ 1188 BlowDelayOffSts 0;
BA_ "GenSigSendType" SG_ 1188 TMS_PM25_ExtSts 0;
BA_ "GenSigSendType" SG_ 1188 TMS_PM25_IncarSts 0;
BA_ "GenSigSendType" SG_ 1188 TMS_AQS_Sts 0;
BA_ "GenSigSendType" SG_ 1188 PM25overproofDisplaySts 0;
BA_ "GenSigSendType" SG_ 1188 AQSDisplaySts 0;
BA_ "GenSigSendType" SG_ 1188 PM25AutoRunSts 0;
BA_ "GenSigSendType" SG_ 1188 PM25AutoRunSetSts 0;
BA_ "GenSigSendType" SG_ 1188 FragranceWelcomeModeSts 0;
BA_ "GenSigSendType" SG_ 1188 FragranceDisplaysts 0;
BA_ "GenSigSendType" SG_ 1188 TMS_AQS_Level 0;
BA_ "GenSigSendType" SG_ 1188 ACRequestCommand 0;
BA_ "GenSigSendType" SG_ 1188 PM25_Outcar_Level 0;
BA_ "GenSigSendType" SG_ 1188 PM25_Incar_Level 0;
BA_ "GenSigSendType" SG_ 1188 SetTemperature_L_F 0;
BA_ "GenSigInvalidValue" SG_ 1188 SetTemperature_L_F 31;
BA_ "GenSigStartValue" SG_ 1188 SetTemperature_L_F 31;
BA_ "GenSigSendType" SG_ 1188 SetTemperature_R_F 0;
BA_ "GenSigInvalidValue" SG_ 1188 SetTemperature_R_F 31;
BA_ "GenSigStartValue" SG_ 1188 SetTemperature_R_F 31;
BA_ "GenSigSendType" SG_ 1188 TMS_PM25_incar 0;
BA_ "GenSigSendType" SG_ 1188 TMS_PM25_ext 0;
BA_ "GenSigSendType" SG_ 1188 TMS_KeepWarmMemoryFb 0;
BA_ "E2EDataLength" SG_ 612 Fusa_264_5 64;
BA_ "E2EProfile" SG_ 612 Fusa_264_5 "P01";
BA_ "E2EDataId" SG_ 612 Fusa_264_5 43;
BA_ "GenSigSendType" SG_ 612 Fusa_264_5 0;
BA_ "E2EDataLength" SG_ 612 Fusa_264_4 64;
BA_ "E2EProfile" SG_ 612 Fusa_264_4 "P01";
BA_ "E2EDataId" SG_ 612 Fusa_264_4 43;
BA_ "GenSigSendType" SG_ 612 Fusa_264_4 0;
BA_ "E2EDataLength" SG_ 612 Fusa_264_3 64;
BA_ "E2EProfile" SG_ 612 Fusa_264_3 "P01";
BA_ "E2EDataId" SG_ 612 Fusa_264_3 43;
BA_ "GenSigSendType" SG_ 612 Fusa_264_3 0;
BA_ "E2EDataLength" SG_ 612 Fusa_264_2 64;
BA_ "E2EProfile" SG_ 612 Fusa_264_2 "P01";
BA_ "E2EDataId" SG_ 612 Fusa_264_2 43;
BA_ "GenSigSendType" SG_ 612 Fusa_264_2 0;
BA_ "E2EDataLength" SG_ 612 Fusa_264_1 64;
BA_ "E2EProfile" SG_ 612 Fusa_264_1 "P01";
BA_ "E2EDataId" SG_ 612 Fusa_264_1 43;
BA_ "GenSigSendType" SG_ 612 Fusa_264_1 0;
BA_ "GenSigSendType" SG_ 612 EPB_R_1_CRC1 0;
BA_ "E2EDataId" SG_ 612 EPB_R_1_CRC1 43;
BA_ "E2EProfile" SG_ 612 EPB_R_1_CRC1 "P01";
BA_ "E2EDataLength" SG_ 612 EPB_R_1_CRC1 64;
BA_ "GenSigSendType" SG_ 612 EPB_R_1_RollgCntr1 0;
BA_ "E2EDataId" SG_ 612 EPB_R_1_RollgCntr1 43;
BA_ "E2EProfile" SG_ 612 EPB_R_1_RollgCntr1 "P01";
BA_ "E2EDataLength" SG_ 612 EPB_R_1_RollgCntr1 64;
BA_ "GenSigSendType" SG_ 612 EPB_1_FltLamp 0;
BA_ "E2EDataId" SG_ 612 EPB_1_FltLamp 43;
BA_ "E2EProfile" SG_ 612 EPB_1_FltLamp "P01";
BA_ "E2EDataLength" SG_ 612 EPB_1_FltLamp 64;
BA_ "GenSigSendType" SG_ 612 EPB_1_ParkLamp 0;
BA_ "E2EDataId" SG_ 612 EPB_1_ParkLamp 43;
BA_ "E2EProfile" SG_ 612 EPB_1_ParkLamp "P01";
BA_ "E2EDataLength" SG_ 612 EPB_1_ParkLamp 64;
BA_ "GenSigSendType" SG_ 612 EPB_1_ActrSt 0;
BA_ "E2EDataId" SG_ 612 EPB_1_ActrSt 43;
BA_ "E2EProfile" SG_ 612 EPB_1_ActrSt "P01";
BA_ "E2EDataLength" SG_ 612 EPB_1_ActrSt 64;
BA_ "GenSigSendType" SG_ 612 EPB_1_RWUSt 0;
BA_ "E2EDataId" SG_ 612 EPB_1_RWUSt 43;
BA_ "E2EProfile" SG_ 612 EPB_1_RWUSt "P01";
BA_ "E2EDataLength" SG_ 612 EPB_1_RWUSt 64;
BA_ "GenSigSendType" SG_ 612 EPB_1_TextDisp 0;
BA_ "E2EDataId" SG_ 612 EPB_1_TextDisp 43;
BA_ "E2EProfile" SG_ 612 EPB_1_TextDisp "P01";
BA_ "E2EDataLength" SG_ 612 EPB_1_TextDisp 64;
BA_ "GenSigSendType" SG_ 612 IPB_EPBErrorStatus 0;
BA_ "E2EDataId" SG_ 612 IPB_EPBErrorStatus 43;
BA_ "E2EProfile" SG_ 612 IPB_EPBErrorStatus "P01";
BA_ "E2EDataLength" SG_ 612 IPB_EPBErrorStatus 64;
BA_ "GenSigSendType" SG_ 1193 AVHSwitchSts 0;
BA_ "GenSigSendType" SG_ 1193 AVHWarningMessage 0;
BA_ "GenSigSendType" SG_ 1193 CDPActive 0;
BA_ "GenSigSendType" SG_ 1193 HDCFailSts 0;
BA_ "GenSigSendType" SG_ 1193 HDCCtrlSts 0;
BA_ "GenSigSendType" SG_ 1193 AVHSts 0;
BA_ "GenSigSendType" SG_ 1193 AVHFailSts 0;
BA_ "GenSigSendType" SG_ 1193 FWAWarningSts 0;
BA_ "GRC_Sig_ASIL" SG_ 1193 BrakeFluidSts 3;
BA_ "GenSigSendType" SG_ 1193 BrakeFluidSts 0;
BA_ "GRC_Sig_ASIL" SG_ 1193 BrakesystemFailSts 3;
BA_ "GenSigSendType" SG_ 1193 BrakesystemFailSts 0;
BA_ "GenSigSendType" SG_ 1197 CST_Status 0;
BA_ "GenSigStartValue" SG_ 1197 CST_Status 1;
BA_ "GenSigSendType" SG_ 1197 BrakepedalFeelSts 0;
BA_ "GenSigSendType" SG_ 1197 CST_SensitivitySts 0;
BA_ "GenSigStartValue" SG_ 1197 CST_SensitivitySts 2;
BA_ "GenSigSendType" SG_ 1200 EBS_SOC 0;
BA_ "GenSigInvalidValue" SG_ 1200 EBS_SOC 255;
BA_ "GenSigStartValue" SG_ 1200 EBS_SOC 255;
BA_ "GenSigSendType" SG_ 1061 Drv_Seat_RBolster_Sts 0;
BA_ "GenSigSendType" SG_ 1061 Drv_Seat_LBolster_Sts 0;
BA_ "GenSigSendType" SG_ 1061 Drv_Seat_ActvBolster_MdSts 0;
BA_ "GenSigSendType" SG_ 1061 DriverSeatMsgStr_LvlSts 0;
BA_ "GenSigSendType" SG_ 1061 DriverSeatMsg_ModeSts 0;
BA_ "GenSigSendType" SG_ 1065 LeftSeatMsgStr_LvlSts 0;
BA_ "GenSigSendType" SG_ 1065 LeftSeatMsg_ModeSts 0;
BA_ "GenSigSendType" SG_ 1069 PassSeatMsgStr_LvlSts 0;
BA_ "GenSigSendType" SG_ 1069 PassSeatMsg_ModeSts 0;
BA_ "GenSigSendType" SG_ 1087 RightSeatMsgStr_LvlSts 0;
BA_ "GenSigSendType" SG_ 1087 RightSeatMsg_ModeSts 0;
BA_ "GenSigSendType" SG_ 1189 SRF_OperateSts 0;
BA_ "GenSigSendType" SG_ 1189 SRF_PositionSts 0;
BA_ "GenSigSendType" SG_ 1189 SRF_OverHeatProtect 0;
BA_ "GenSigSendType" SG_ 1189 SRF_Sunshade_OperateSts 0;
BA_ "GenSigSendType" SG_ 1189 Sunshade_OverHeatProtect 0;
BA_ "GenSigSendType" SG_ 1192 SRF_Sunroof_ActualSts 0;
BA_ "GenSigSendType" SG_ 1192 SRF_Sunshade_ActualSts 0;
BA_ "GenSigSendType" SG_ 1192 SRF_Sunshade_PositionSts 0;
BA_ "GenSigSendType" SG_ 1143 OBC_InnerDischgReq 0;
BA_ "GRC_Sig_ASIL" SG_ 1143 OBC_CC_ConnectSts 2;
BA_ "GenSigSendType" SG_ 1143 OBC_CC_ConnectSts 0;
BA_ "GenSigSendType" SG_ 1143 CDU_MILSts 0;
BA_ "GenSigSendType" SG_ 1295 BMS_BattFaultLampSts 0;
BA_ "GenSigSendType" SG_ 1295 BMS_OverTemp_LightSts 0;
BA_ "GenSigSendType" SG_ 1295 BMS_RemainChg_Time 0;
BA_ "GRC_Sig_ASIL" SG_ 1295 BMS_ThermalRunawayDis 4;
BA_ "GenSigSendType" SG_ 1295 BMS_ThermalRunawayDis 0;
BA_ "GRC_Sig_ASIL" SG_ 1295 BMS_TBOXIsolationFault 3;
BA_ "GenSigSendType" SG_ 1295 BMS_TBOXIsolationFault 0;
BA_ "GenSigSendType" SG_ 1295 BMS_PreWarmDis 0;
BA_ "GenSigSendType" SG_ 1531 BMS_HvBattSoeActDisChaCyc 0;
BA_ "GenSigStartValue" SG_ 1531 BMS_HvBattSoeActDisChaCyc 65535;
BA_ "GenSigSendType" SG_ 1531 BMS_HvBattSoeActReChaCyc 0;
BA_ "GenSigStartValue" SG_ 1531 BMS_HvBattSoeActReChaCyc 65535;
BA_ "GenSigSendType" SG_ 1531 BMS_HvBattRatedEnergy 0;
BA_ "GenSigStartValue" SG_ 1531 BMS_HvBattRatedEnergy 16382;
BA_ "GenSigSendType" SG_ 1531 BMS_HvBattRatedU 0;
BA_ "GenSigStartValue" SG_ 1531 BMS_HvBattRatedU 16382;
BA_ "GenSigSendType" SG_ 1531 BMS_HvBattTypeCode 0;
BA_ "GenSigStartValue" SG_ 1531 BMS_HvBattTypeCode 255;
BA_ "GenSigSendType" SG_ 1531 BMS_HvBattManufcCode 0;
BA_ "GenSigSendType" SG_ 1531 BMS_HvBattTempSensorTotalNum 0;
BA_ "GenSigStartValue" SG_ 1531 BMS_HvBattTempSensorTotalNum 65535;
BA_ "GenSigSendType" SG_ 1531 BMS_HvBattTempSensorTempMaxNum 0;
BA_ "GenSigStartValue" SG_ 1531 BMS_HvBattTempSensorTempMaxNum 255;
BA_ "GenSigSendType" SG_ 1531 BMS_HvBattTempSensorTempMinNum 0;
BA_ "GenSigStartValue" SG_ 1531 BMS_HvBattTempSensorTempMinNum 255;
BA_ "GenSigSendType" SG_ 1531 BMS_HvBattTempMaxNum 0;
BA_ "GenSigStartValue" SG_ 1531 BMS_HvBattTempMaxNum 255;
BA_ "GenSigSendType" SG_ 1531 BMS_HvBattTempMinNum 0;
BA_ "GenSigStartValue" SG_ 1531 BMS_HvBattTempMinNum 255;
BA_ "GenSigSendType" SG_ 1531 BMS_BattCellTotalNum 0;
BA_ "GenSigStartValue" SG_ 1531 BMS_BattCellTotalNum 65535;
BA_ "GenSigSendType" SG_ 1531 BMS_HvBattVoltMaxNum 0;
BA_ "GenSigStartValue" SG_ 1531 BMS_HvBattVoltMaxNum 255;
BA_ "GenSigSendType" SG_ 1531 BMS_HvBattVoltMinNum 0;
BA_ "GenSigStartValue" SG_ 1531 BMS_HvBattVoltMinNum 255;
BA_ "GenSigSendType" SG_ 1531 BMS_ActualSOCMin 0;
BA_ "GenSigStartValue" SG_ 1531 BMS_ActualSOCMin 4095;
BA_ "GenSigSendType" SG_ 1531 BMS_ActualSOCMax 0;
BA_ "GenSigStartValue" SG_ 1531 BMS_ActualSOCMax 4095;
BA_ "GenSigSendType" SG_ 1224 BMS_HvBattCellVoltMax_Num 0;
BA_ "GenSigStartValue" SG_ 1224 BMS_HvBattCellVoltMax_Num 255;
BA_ "GRC_Sig_ASIL" SG_ 1224 BMS_HvBattCellVoltMax 4;
BA_ "GenSigSendType" SG_ 1224 BMS_HvBattCellVoltMax 0;
BA_ "GenSigStartValue" SG_ 1224 BMS_HvBattCellVoltMax 65534;
BA_ "GenSigSendType" SG_ 1224 BMS_HvBattCellVoltMin_Num 0;
BA_ "GenSigStartValue" SG_ 1224 BMS_HvBattCellVoltMin_Num 255;
BA_ "GRC_Sig_ASIL" SG_ 1224 BMS_HvBattCellVoltMin 4;
BA_ "GenSigSendType" SG_ 1224 BMS_HvBattCellVoltMin 0;
BA_ "GenSigStartValue" SG_ 1224 BMS_HvBattCellVoltMin 65534;
BA_ "GenSigSendType" SG_ 1224 BMS_Chg_Sts 0;
BA_ "GenSigSendType" SG_ 1235 EPS_2_Steer_ReturnRmd_Sts 0;
BA_ "GenSigSendType" SG_ 1235 EPS_2_Steer_ReturnRmd 0;
BA_ "GenSigSendType" SG_ 1235 EPS_2_MFS_ShakeSts 0;
BA_ "GenSigSendType" SG_ 1330 DWD_DistanceR 0;
BA_ "GenSigSendType" SG_ 1330 DWD_DistanceL 0;
BA_ "GenSigSendType" SG_ 1330 DWD_TextDisp 0;
BA_ "GenSigSendType" SG_ 1330 DWD_SoundIndcn 0;
BA_ "GenSigSendType" SG_ 1330 LSensorFailSts 0;
BA_ "GenSigSendType" SG_ 1330 RSensorFailSts 0;
BA_ "GenSigSendType" SG_ 1330 DWD_Distance 0;
BA_ "GenSigSendType" SG_ 1330 DWD_Switch 0;
BA_ "GenSigSendType" SG_ 1328 RADAR_1_RadarDetectSts 0;
BA_ "E2EProfile" SG_ 1328 RADAR_1_RadarDetectSts "*";
BA_ "GenSigSendType" SG_ 1328 RADAR_1_RadarWorkSts 0;
BA_ "E2EProfile" SG_ 1328 RADAR_1_RadarWorkSts "*";
BA_ "GenSigSendType" SG_ 1328 RADAR_1_Resd1 0;
BA_ "E2EProfile" SG_ 1328 RADAR_1_Resd1 "*";
BA_ "GenSigSendType" SG_ 1328 RADAR_1_LHRRadarSensorDistance 0;
BA_ "GenSigStartValue" SG_ 1328 RADAR_1_LHRRadarSensorDistance 62;
BA_ "E2EProfile" SG_ 1328 RADAR_1_LHRRadarSensorDistance "*";
BA_ "GenSigSendType" SG_ 1328 RADAR_1_RHMRRadarSensorDistance 0;
BA_ "GenSigStartValue" SG_ 1328 RADAR_1_RHMRRadarSensorDistance 62;
BA_ "E2EProfile" SG_ 1328 RADAR_1_RHMRRadarSensorDistance "*";
BA_ "GenSigSendType" SG_ 1328 RADAR_1_LHMRRadarSensorDistance 0;
BA_ "GenSigStartValue" SG_ 1328 RADAR_1_LHMRRadarSensorDistance 62;
BA_ "E2EProfile" SG_ 1328 RADAR_1_LHMRRadarSensorDistance "*";
BA_ "GenSigSendType" SG_ 1328 RADAR_1_RHRRadarSensorDistance 0;
BA_ "GenSigStartValue" SG_ 1328 RADAR_1_RHRRadarSensorDistance 62;
BA_ "E2EProfile" SG_ 1328 RADAR_1_RHRRadarSensorDistance "*";
BA_ "GenSigSendType" SG_ 1328 RADAR_1_LHFRadarSensorDistance 0;
BA_ "GenSigStartValue" SG_ 1328 RADAR_1_LHFRadarSensorDistance 30;
BA_ "E2EProfile" SG_ 1328 RADAR_1_LHFRadarSensorDistance "*";
BA_ "GenSigSendType" SG_ 1328 RADAR_1_RHFRadarSensorDistance 0;
BA_ "GenSigStartValue" SG_ 1328 RADAR_1_RHFRadarSensorDistance 30;
BA_ "E2EProfile" SG_ 1328 RADAR_1_RHFRadarSensorDistance "*";
BA_ "GenSigSendType" SG_ 1328 RADAR_1_ParkingRadarSwSts 0;
BA_ "E2EProfile" SG_ 1328 RADAR_1_ParkingRadarSwSts "*";
BA_ "GenSigSendType" SG_ 1328 RADAR_1_RHMFRadarSensorDistance 0;
BA_ "GenSigStartValue" SG_ 1328 RADAR_1_RHMFRadarSensorDistance 30;
BA_ "E2EProfile" SG_ 1328 RADAR_1_RHMFRadarSensorDistance "*";
BA_ "GenSigSendType" SG_ 1328 RADAR_1_LHMFRadarSensorDistance 0;
BA_ "GenSigStartValue" SG_ 1328 RADAR_1_LHMFRadarSensorDistance 30;
BA_ "E2EProfile" SG_ 1328 RADAR_1_LHMFRadarSensorDistance "*";
BA_ "GenSigSendType" SG_ 1328 RADAR_1_AudibleBeepRate 0;
BA_ "E2EProfile" SG_ 1328 RADAR_1_AudibleBeepRate "*";
BA_ "GRC_Sig_ASIL" SG_ 259 EMS_EngineSpeed_Actual 2;
BA_ "GenSigSendType" SG_ 259 EMS_EngineSpeed_Actual 0;
BA_ "GenSigInvalidValue" SG_ 259 EMS_EngineSpeed_Actual 65535;
BA_ "GenSigSendType" SG_ 1234 FRZCU_ManualPowerOFFWarning_4D2h 0;
BA_ "GenSigSendType" SG_ 1234 FRZCU_FRSeatHeiFb 0;
BA_ "GenSigInvalidValue" SG_ 1234 FRZCU_FRSeatHeiFb 127;
BA_ "GenSigSendType" SG_ 1234 FRZCU_FRSeatLvlFb 0;
BA_ "GenSigInvalidValue" SG_ 1234 FRZCU_FRSeatLvlFb 127;
BA_ "GenSigSendType" SG_ 1234 FRZCU_FRSeatBackAgFb 0;
BA_ "GenSigInvalidValue" SG_ 1234 FRZCU_FRSeatBackAgFb 127;
BA_ "GenSigSendType" SG_ 1234 FRZCU_FRSeatLegSpprtFb 0;
BA_ "GenSigInvalidValue" SG_ 1234 FRZCU_FRSeatLegSpprtFb 127;
BA_ "GenSigSendType" SG_ 1234 FRZCU_FRWinSts 0;
BA_ "GenSigSendType" SG_ 1234 FRZCU_RRWinSts 0;
BA_ "GenSigSendType" SG_ 1234 FRZCU_FRSeatLegRestAngleFb 0;
BA_ "GenSigInvalidValue" SG_ 1234 FRZCU_FRSeatLegRestAngleFb 127;
BA_ "GenSigSendType" SG_ 1234 FRZCU_FRSeatCushFb 0;
BA_ "GenSigInvalidValue" SG_ 1234 FRZCU_FRSeatCushFb 127;
BA_ "GenSigSendType" SG_ 1234 FRZCU_FRSeatNeedMemory 0;
BA_ "GenSigSendType" SG_ 1234 FRZCU_FRMemoryFb 0;
BA_ "GenSigSendType" SG_ 1234 FRZCU_FRRecoverFb 0;
BA_ "GenSigSendType" SG_ 1234 FRZCU_EasyEntryExitFb 0;
BA_ "GenSigSendType" SG_ 1234 FRZCU_EnjoyableSeatWarning 0;
BA_ "GenSigSendType" SG_ 1234 FRZCU_EnjoyableSeatSts 0;
BA_ "GenSigSendType" SG_ 1234 SeatHeatLevelsFR 0;
BA_ "GenSigSendType" SG_ 1234 SeatVentLevelsFR 0;
BA_ "GenSigSendType" SG_ 1234 SeatHeatLevelsRR 0;
BA_ "GenSigSendType" SG_ 1234 SeatVentLevelsRR 0;
BA_ "GenSigSendType" SG_ 1234 FRZCU_FRSeatFoldFb 0;
BA_ "GenSigInvalidValue" SG_ 1234 FRZCU_FRSeatFoldFb 127;
BA_ "GenSigSendType" SG_ 517 MFSR_UP_SW 0;
BA_ "GenSigSendType" SG_ 517 MFSR_DW_SW 0;
BA_ "GenSigSendType" SG_ 517 MFSR_Left_SW 0;
BA_ "GenSigSendType" SG_ 517 MFSR_Right_SW 0;
BA_ "GenSigSendType" SG_ 517 MFSR_OK_SW 0;
BA_ "GenSigSendType" SG_ 517 MFSR_Voice_SW 0;
BA_ "GenSigSendType" SG_ 517 MFSR_Customize 0;
BA_ "GenSigSendType" SG_ 1096 TMS_ICAstsFed_448h 0;
BA_ "GenSigSendType" SG_ 1096 TMS_SailEACDisable_448h 0;
BA_ "GenSigSendType" SG_ 1096 TMS_LowbattACDisable_448h 0;
BA_ "GenSigSendType" SG_ 1096 TMS_AutoDefogActiveSts 0;
BA_ "GenSigSendType" SG_ 1096 TMS_AirPurgeReminderSts 0;
BA_ "GenSigSendType" SG_ 1096 TMS_BT_Reduce_Wind_SpeedSts 0;
BA_ "GenSigSendType" SG_ 1096 TMS_First_BlowingSts 0;
BA_ "GenSigSendType" SG_ 1096 TMS_CirculationInTunnelsSts 0;
BA_ "GenSigSendType" SG_ 1096 TMS_crosscountry_coolingSts 0;
BA_ "GenSigSendType" SG_ 1096 TMS_ParkingAirConditioningStatus 0;
BA_ "GenSigSendType" SG_ 1096 TMS_CoolantFillSts 0;
BA_ "GenSigSendType" SG_ 1096 TMS_UVC_ControlSts 0;
BA_ "GenSigSendType" SG_ 1096 TMS_UVC_LuminanceSts 0;
BA_ "GenSigSendType" SG_ 1096 TMS_ICC_Lightoff_Sts 0;
BA_ "GenSigSendType" SG_ 1096 TMS_ICC_Memoff_Sts 0;
BA_ "GenSigSendType" SG_ 1096 TMS_keepwarmSet_TemperatureSts 0;
BA_ "GenSigSendType" SG_ 1096 TMS_BiochemicalFuncSts 0;
BA_ "GenSigSendType" SG_ 1096 TMS_TimedVentilationSts 0;
BA_ "GenSigSendType" SG_ 1240 TMS_CFSSwitchFb 0;
BA_ "GenSigSendType" SG_ 1240 TDU_CFSPosOneType 0;
BA_ "GenSigStartValue" SG_ 1240 TDU_CFSPosOneType 15;
BA_ "GenSigSendType" SG_ 1240 TDU_CFSPosTwoType 0;
BA_ "GenSigStartValue" SG_ 1240 TDU_CFSPosTwoType 15;
BA_ "GenSigSendType" SG_ 1240 TDU_CFSPosThreeType 0;
BA_ "GenSigStartValue" SG_ 1240 TDU_CFSPosThreeType 15;
BA_ "GenSigSendType" SG_ 1240 TDU_CFSRunOut 0;
BA_ "GenSigStartValue" SG_ 1240 TDU_CFSRunOut 15;
BA_ "GenSigSendType" SG_ 1240 TMS_CFSShortWarn 0;
BA_ "GenSigStartValue" SG_ 1240 TMS_CFSShortWarn 15;
BA_ "GenSigSendType" SG_ 1240 TMS_CFSLevelSetFb 0;
BA_ "GenSigSendType" SG_ 1240 TMS_CFSPosSetFb 0;
BA_ "GenSigSendType" SG_ 1240 TMS_CFSPosOneLife 0;
BA_ "GenSigInvalidValue" SG_ 1240 TMS_CFSPosOneLife 255;
BA_ "GenSigSendType" SG_ 1240 TMS_CFSPosTwoLife 0;
BA_ "GenSigInvalidValue" SG_ 1240 TMS_CFSPosTwoLife 255;
BA_ "GenSigSendType" SG_ 1240 TMS_CFSPosThreeLife 0;
BA_ "GenSigInvalidValue" SG_ 1240 TMS_CFSPosThreeLife 255;
BA_ "GenSigSendType" SG_ 1240 TMS_PM25SwitchFb 0;
BA_ "GenSigSendType" SG_ 1240 TMS_ThrModeStsFb 0;
BA_ "GenSigStartValue" SG_ 1240 TMS_ThrModeStsFb 7;
BA_ "GenSigSendType" SG_ 1240 TMS_ThrSetTempFb_C 0;
BA_ "GenSigInvalidValue" SG_ 1240 TMS_ThrSetTempFb_C 31;
BA_ "GenSigStartValue" SG_ 1240 TMS_ThrSetTempFb_C 31;
BA_ "GenSigSendType" SG_ 1240 TMS_ThrCLMSwitchFb 0;
BA_ "GenSigSendType" SG_ 1240 TMS_ThrAutoSwitchFb 0;
BA_ "GenSigSendType" SG_ 1240 TMS_ThrBlowSpeedLevelKeyStsFb 0;
BA_ "GenSigSendType" SG_ 638 FRZCU_HoodSts 0;
BA_ "GenSigSendType" SG_ 638 FRZCU_AuthenResult 0;
BA_ "GenSigSendType" SG_ 638 FRZCU_PowerMode 0;
BA_ "GenSigSendType" SG_ 638 FRZCU_TrunkSts 0;
BA_ "GenSigSendType" SG_ 638 FRZCU_HandleSwitchStsFL 0;
BA_ "GenSigSendType" SG_ 638 FRZCU_HandleSwitchStsFR 0;
BA_ "GenSigSendType" SG_ 638 FRZCU_HandleSwitchStsRR 0;
BA_ "GenSigSendType" SG_ 638 FRZCU_HandleSwitchStsRL 0;
BA_ "GenSigSendType" SG_ 638 SeatLength_target_Passenger 0;
BA_ "GenSigSendType" SG_ 638 SeatBackrest_target_Passenger 0;
BA_ "GenSigSendType" SG_ 638 FRZCU_TrunkLockSts 0;
BA_ "GenSigStartValue" SG_ 638 FRZCU_TrunkLockSts 3;
BA_ "GenSigSendType" SG_ 638 FRZCU_HoodLockSts 0;
BA_ "GenSigStartValue" SG_ 638 FRZCU_HoodLockSts 3;
BA_ "GenSigSendType" SG_ 638 FrontBackSpeedAdj_Cmd 0;
BA_ "GenSigSendType" SG_ 638 FRZCU_GloveboxSW 0;
BA_ "GenSigSendType" SG_ 638 FRZCU_FRReleaseLockSts 0;
BA_ "GenSigSendType" SG_ 638 FRZCU_RRReleaseLockSts 0;
BA_ "GenSigSendType" SG_ 638 FRZCU_PELockInKeyWarning 0;
BA_ "GenSigSendType" SG_ 638 FRZCU_PowerOFFWarning 0;
BA_ "GenSigSendType" SG_ 638 FRZCU_KeylessWarning 0;
BA_ "GenSigSendType" SG_ 638 FRZCU_OTAPwrDwnReqFb 0;
BA_ "GenSigSendType" SG_ 638 FRZCU_OTAPwrOnReqFb 0;
BA_ "GenSigSendType" SG_ 949 PEPS_InformationSource 0;
BA_ "GenSigSendType" SG_ 949 PEPS_OrderInformation 0;
BA_ "GenSigSendType" SG_ 949 PEPS_IDInformation 0;
BA_ "GenSigSendType" SG_ 949 PEPS_KeySts 0;
BA_ "GenSigSendType" SG_ 949 PEPS_ETRUnLockReq 4;
BA_ "GenSigSendType" SG_ 1028 PEPS_WelcomeON 4;
BA_ "GenSigSendType" SG_ 1028 PEPS_VehicleSearchReq 4;
BA_ "GenSigSendType" SG_ 1028 PEPS_SATOReminder 4;
BA_ "GenSigSendType" SG_ 1028 PEPS_PLGUnlockReq 4;
BA_ "GenSigSendType" SG_ 1028 PEPS_RKETrunkSts 0;
BA_ "GenSigSendType" SG_ 1028 PEPS_SSBInhibitCWCSts 0;
BA_ "GenSigSendType" SG_ 1028 PEPS_WirelessChargingCtrSts 0;
BA_ "GenSigSendType" SG_ 1028 PEPS_EmgyShutdown 0;
BA_ "GenSigSendType" SG_ 1028 PEPS_SSBInputFailure 0;
BA_ "GenSigSendType" SG_ 1028 PEPS_SmartSystemWarning1_1 0;
BA_ "GenSigSendType" SG_ 1028 PEPS_SmartSystemWarning2_2 0;
BA_ "GenSigSendType" SG_ 1028 PEPS_SmartSystemWarning3_1 0;
BA_ "GenSigSendType" SG_ 1028 PEPS_SmartSystemWarning3_2 0;
BA_ "GenSigSendType" SG_ 1028 PEPS_SmartSystemWarning4_2 0;
BA_ "GenSigSendType" SG_ 1028 PEPS_SmartSystemWarning4_3 0;
BA_ "GenSigSendType" SG_ 1028 PEPS_SystemWarning 0;
BA_ "GenSigSendType" SG_ 1028 PEPS_BLTKeyPESts 0;
BA_ "GenSigSendType" SG_ 1291 BMS_2_G_CRC 0;
BA_ "E2EDataId" SG_ 1291 BMS_2_G_CRC 117;
BA_ "E2EProfile" SG_ 1291 BMS_2_G_CRC "P01";
BA_ "E2EDataLength" SG_ 1291 BMS_2_G_CRC 64;
BA_ "GenSigSendType" SG_ 1291 BMS_2_G_RollgCntr 0;
BA_ "E2EDataId" SG_ 1291 BMS_2_G_RollgCntr 117;
BA_ "E2EProfile" SG_ 1291 BMS_2_G_RollgCntr "P01";
BA_ "E2EDataLength" SG_ 1291 BMS_2_G_RollgCntr 64;
BA_ "GenSigSendType" SG_ 1291 BMS_2_G_Resd 0;
BA_ "E2EDataId" SG_ 1291 BMS_2_G_Resd 117;
BA_ "E2EProfile" SG_ 1291 BMS_2_G_Resd "P01";
BA_ "E2EDataLength" SG_ 1291 BMS_2_G_Resd 64;
BA_ "GenSigSendType" SG_ 1291 BMS_TBOXInsulation_R 0;
BA_ "E2EDataId" SG_ 1291 BMS_TBOXInsulation_R 117;
BA_ "E2EProfile" SG_ 1291 BMS_TBOXInsulation_R "P01";
BA_ "E2EDataLength" SG_ 1291 BMS_TBOXInsulation_R 64;
BA_ "GenSigSendType" SG_ 1291 BMS_TBOXErrorNumber 0;
BA_ "E2EDataId" SG_ 1291 BMS_TBOXErrorNumber 117;
BA_ "E2EProfile" SG_ 1291 BMS_TBOXErrorNumber "P01";
BA_ "E2EDataLength" SG_ 1291 BMS_TBOXErrorNumber 64;
BA_ "GenSigSendType" SG_ 1291 BMS_TBOXHvBattMaxT 0;
BA_ "GenSigStartValue" SG_ 1291 BMS_TBOXHvBattMaxT 255;
BA_ "E2EDataId" SG_ 1291 BMS_TBOXHvBattMaxT 117;
BA_ "E2EProfile" SG_ 1291 BMS_TBOXHvBattMaxT "P01";
BA_ "E2EDataLength" SG_ 1291 BMS_TBOXHvBattMaxT 64;
BA_ "GenSigSendType" SG_ 1291 BMS_TBOXHvBattMinT 0;
BA_ "GenSigStartValue" SG_ 1291 BMS_TBOXHvBattMinT 255;
BA_ "E2EDataId" SG_ 1291 BMS_TBOXHvBattMinT 117;
BA_ "E2EProfile" SG_ 1291 BMS_TBOXHvBattMinT "P01";
BA_ "E2EDataLength" SG_ 1291 BMS_TBOXHvBattMinT 64;
BA_ "GRC_Sig_ASIL" SG_ 1291 BMS_SOCLight 3;
BA_ "GenSigSendType" SG_ 1291 BMS_SOCLight 0;
BA_ "GenSigInvalidValue" SG_ 1291 BMS_SOCLight 127;
BA_ "E2EDataId" SG_ 1291 BMS_SOCLight 117;
BA_ "E2EProfile" SG_ 1291 BMS_SOCLight "P01";
BA_ "E2EDataLength" SG_ 1291 BMS_SOCLight 64;
BA_ "GenSigSendType" SG_ 1104 RLCR_2_CRC1 0;
BA_ "E2EDataId" SG_ 1104 RLCR_2_CRC1 69;
BA_ "E2EProfile" SG_ 1104 RLCR_2_CRC1 "P01";
BA_ "E2EDataLength" SG_ 1104 RLCR_2_CRC1 64;
BA_ "GenSigSendType" SG_ 1104 RLCR_2_RollgCntr1 0;
BA_ "E2EDataId" SG_ 1104 RLCR_2_RollgCntr1 69;
BA_ "E2EProfile" SG_ 1104 RLCR_2_RollgCntr1 "P01";
BA_ "E2EDataLength" SG_ 1104 RLCR_2_RollgCntr1 64;
BA_ "GenSigSendType" SG_ 1104 RLCR_2_Resd1 0;
BA_ "E2EDataId" SG_ 1104 RLCR_2_Resd1 69;
BA_ "E2EProfile" SG_ 1104 RLCR_2_Resd1 "P01";
BA_ "E2EDataLength" SG_ 1104 RLCR_2_Resd1 64;
BA_ "GenSigSendType" SG_ 1104 RLCR_2_RCWWarn 0;
BA_ "E2EDataId" SG_ 1104 RLCR_2_RCWWarn 69;
BA_ "E2EProfile" SG_ 1104 RLCR_2_RCWWarn "P01";
BA_ "E2EDataLength" SG_ 1104 RLCR_2_RCWWarn 64;
BA_ "GenSigSendType" SG_ 1104 RLCR_2_RCTAWarn 0;
BA_ "E2EDataId" SG_ 1104 RLCR_2_RCTAWarn 69;
BA_ "E2EProfile" SG_ 1104 RLCR_2_RCTAWarn "P01";
BA_ "E2EDataLength" SG_ 1104 RLCR_2_RCTAWarn 64;
BA_ "GenSigSendType" SG_ 1104 RLCR_2_BSDLCWONOFFSts 0;
BA_ "E2EDataId" SG_ 1104 RLCR_2_BSDLCWONOFFSts 69;
BA_ "E2EProfile" SG_ 1104 RLCR_2_BSDLCWONOFFSts "P01";
BA_ "E2EDataLength" SG_ 1104 RLCR_2_BSDLCWONOFFSts 64;
BA_ "GenSigSendType" SG_ 1104 RLCR_2_DOWONOFFSts 0;
BA_ "E2EDataId" SG_ 1104 RLCR_2_DOWONOFFSts 69;
BA_ "E2EProfile" SG_ 1104 RLCR_2_DOWONOFFSts "P01";
BA_ "E2EDataLength" SG_ 1104 RLCR_2_DOWONOFFSts 64;
BA_ "GenSigSendType" SG_ 1104 RLCR_2_RCWONOFFSts 0;
BA_ "E2EDataId" SG_ 1104 RLCR_2_RCWONOFFSts 69;
BA_ "E2EProfile" SG_ 1104 RLCR_2_RCWONOFFSts "P01";
BA_ "E2EDataLength" SG_ 1104 RLCR_2_RCWONOFFSts 64;
BA_ "GenSigSendType" SG_ 1104 RLCR_2_RCTARCTBONOFFSts 0;
BA_ "E2EDataId" SG_ 1104 RLCR_2_RCTARCTBONOFFSts 69;
BA_ "E2EProfile" SG_ 1104 RLCR_2_RCTARCTBONOFFSts "P01";
BA_ "E2EDataLength" SG_ 1104 RLCR_2_RCTARCTBONOFFSts 64;
BA_ "GenSigSendType" SG_ 1271 RRCR_2_CRC1 0;
BA_ "E2EDataId" SG_ 1271 RRCR_2_CRC1 71;
BA_ "E2EProfile" SG_ 1271 RRCR_2_CRC1 "P01";
BA_ "E2EDataLength" SG_ 1271 RRCR_2_CRC1 64;
BA_ "GenSigSendType" SG_ 1271 RRCR_2_RollgCntr1 0;
BA_ "E2EDataId" SG_ 1271 RRCR_2_RollgCntr1 71;
BA_ "E2EProfile" SG_ 1271 RRCR_2_RollgCntr1 "P01";
BA_ "E2EDataLength" SG_ 1271 RRCR_2_RollgCntr1 64;
BA_ "GenSigSendType" SG_ 1271 RRCR_2_Resd1 0;
BA_ "E2EDataId" SG_ 1271 RRCR_2_Resd1 71;
BA_ "E2EProfile" SG_ 1271 RRCR_2_Resd1 "P01";
BA_ "E2EDataLength" SG_ 1271 RRCR_2_Resd1 64;
BA_ "GenSigSendType" SG_ 1271 RRCR_2_RCWWarn 0;
BA_ "E2EDataId" SG_ 1271 RRCR_2_RCWWarn 71;
BA_ "E2EProfile" SG_ 1271 RRCR_2_RCWWarn "P01";
BA_ "E2EDataLength" SG_ 1271 RRCR_2_RCWWarn 64;
BA_ "GenSigSendType" SG_ 1271 RRCR_2_RCTAWarn 0;
BA_ "E2EDataId" SG_ 1271 RRCR_2_RCTAWarn 71;
BA_ "E2EProfile" SG_ 1271 RRCR_2_RCTAWarn "P01";
BA_ "E2EDataLength" SG_ 1271 RRCR_2_RCTAWarn 64;
BA_ "GenSigSendType" SG_ 1271 RRCR_2_BSDLCWONOFFSts 0;
BA_ "E2EDataId" SG_ 1271 RRCR_2_BSDLCWONOFFSts 71;
BA_ "E2EProfile" SG_ 1271 RRCR_2_BSDLCWONOFFSts "P01";
BA_ "E2EDataLength" SG_ 1271 RRCR_2_BSDLCWONOFFSts 64;
BA_ "GenSigSendType" SG_ 1271 RRCR_2_DOWONOFFSts 0;
BA_ "E2EDataId" SG_ 1271 RRCR_2_DOWONOFFSts 71;
BA_ "E2EProfile" SG_ 1271 RRCR_2_DOWONOFFSts "P01";
BA_ "E2EDataLength" SG_ 1271 RRCR_2_DOWONOFFSts 64;
BA_ "GenSigSendType" SG_ 1271 RRCR_2_RCWONOFFSts 0;
BA_ "E2EDataId" SG_ 1271 RRCR_2_RCWONOFFSts 71;
BA_ "E2EProfile" SG_ 1271 RRCR_2_RCWONOFFSts "P01";
BA_ "E2EDataLength" SG_ 1271 RRCR_2_RCWONOFFSts 64;
BA_ "GenSigSendType" SG_ 1271 RRCR_2_RCTARCTBONOFFSts 0;
BA_ "E2EDataId" SG_ 1271 RRCR_2_RCTARCTBONOFFSts 71;
BA_ "E2EProfile" SG_ 1271 RRCR_2_RCTARCTBONOFFSts "P01";
BA_ "E2EDataLength" SG_ 1271 RRCR_2_RCTARCTBONOFFSts 64;
BA_ "GenSigSendType" SG_ 587 IPB_SandABSSwSts_24Bh 0;
BA_ "GRC_Sig_ASIL" SG_ 587 IPB_SandABSSwSts_24Bh 3;
BA_ "GenSigSendType" SG_ 587 IPB_SandABSAvl_24Bh 0;
BA_ "GRC_Sig_ASIL" SG_ 587 IPB_SandABSAvl_24Bh 3;
BA_ "GRC_Sig_ASIL" SG_ 587 ONEBOX_4_LHFWheelSpeedRPM 5;
BA_ "GenSigSendType" SG_ 587 ONEBOX_4_LHFWheelSpeedRPM 0;
BA_ "GenSigInvalidValue" SG_ 587 ONEBOX_4_LHFWheelSpeedRPM 65535;
BA_ "GRC_Sig_ASIL" SG_ 587 ONEBOX_4_RHFWheelSpeedRPM 5;
BA_ "GenSigSendType" SG_ 587 ONEBOX_4_RHFWheelSpeedRPM 0;
BA_ "GenSigInvalidValue" SG_ 587 ONEBOX_4_RHFWheelSpeedRPM 65535;
BA_ "GRC_Sig_ASIL" SG_ 587 LHRWheelSpeedRPM 3;
BA_ "GenSigSendType" SG_ 587 LHRWheelSpeedRPM 0;
BA_ "GenSigInvalidValue" SG_ 587 LHRWheelSpeedRPM 65535;
BA_ "GRC_Sig_ASIL" SG_ 587 RHRWheelSpeedRPM 3;
BA_ "GenSigSendType" SG_ 587 RHRWheelSpeedRPM 0;
BA_ "GenSigInvalidValue" SG_ 587 RHRWheelSpeedRPM 65535;
BA_ "GRC_Sig_ASIL" SG_ 587 LHRPulseCounterFailSts 3;
BA_ "GenSigSendType" SG_ 587 LHRPulseCounterFailSts 0;
BA_ "GRC_Sig_ASIL" SG_ 587 LHRPulseCounter 3;
BA_ "GenSigSendType" SG_ 587 LHRPulseCounter 0;
BA_ "GRC_Sig_ASIL" SG_ 587 RHRPulseCounterFailSts 3;
BA_ "GenSigSendType" SG_ 587 RHRPulseCounterFailSts 0;
BA_ "GRC_Sig_ASIL" SG_ 587 RHRPulseCounter 3;
BA_ "GenSigSendType" SG_ 587 RHRPulseCounter 0;
BA_ "GRC_Sig_ASIL" SG_ 587 RHFPulseCounterFailSts 3;
BA_ "GenSigSendType" SG_ 587 RHFPulseCounterFailSts 0;
BA_ "GRC_Sig_ASIL" SG_ 587 RHFPulseCounter 3;
BA_ "GenSigSendType" SG_ 587 RHFPulseCounter 0;
BA_ "GRC_Sig_ASIL" SG_ 587 LHFPulseCounterFailSts 3;
BA_ "GenSigSendType" SG_ 587 LHFPulseCounterFailSts 0;
BA_ "GRC_Sig_ASIL" SG_ 587 LHFPulseCounter 3;
BA_ "GenSigSendType" SG_ 587 LHFPulseCounter 0;
BA_ "GRC_Sig_ASIL" SG_ 587 LHFWheelDriveDirection 3;
BA_ "GenSigSendType" SG_ 587 LHFWheelDriveDirection 0;
BA_ "GenSigInvalidValue" SG_ 587 LHFWheelDriveDirection 4;
BA_ "GRC_Sig_ASIL" SG_ 587 RHFWheelDriveDirection 3;
BA_ "GenSigSendType" SG_ 587 RHFWheelDriveDirection 0;
BA_ "GenSigInvalidValue" SG_ 587 RHFWheelDriveDirection 4;
BA_ "GRC_Sig_ASIL" SG_ 587 LHRWheelDriveDirection 3;
BA_ "GenSigSendType" SG_ 587 LHRWheelDriveDirection 0;
BA_ "GenSigInvalidValue" SG_ 587 LHRWheelDriveDirection 4;
BA_ "GRC_Sig_ASIL" SG_ 587 RHRWheelDriveDirection 3;
BA_ "GenSigSendType" SG_ 587 RHRWheelDriveDirection 0;
BA_ "GenSigInvalidValue" SG_ 587 RHRWheelDriveDirection 4;
BA_ "GenSigSendType" SG_ 1338 FMCU_ErrLvlDis 0;
BA_ "GenSigSendType" SG_ 1338 FMCU_SpdAct_EDR 0;
BA_ "GenSigInvalidValue" SG_ 1338 FMCU_SpdAct_EDR 65535;
BA_ "GenSigStartValue" SG_ 1338 FMCU_SpdAct_EDR 32767;
BA_ "GenSigSendType" SG_ 777 ISGF_ErrLvl 0;
BA_ "GenSigSendType" SG_ 1403 RMCU_ErrLvlDis 0;
BA_ "GenSigSendType" SG_ 1403 RMCU_Speed_EDR 0;
BA_ "GenSigSendType" SG_ 1299 BMS_PackVoltageDis 0;
BA_ "GenSigInvalidValue" SG_ 1299 BMS_PackVoltageDis 65535;
BA_ "GenSigStartValue" SG_ 1299 BMS_PackVoltageDis 65535;
BA_ "GenSigSendType" SG_ 1299 BMS_PackCurrentDis 0;
BA_ "GenSigInvalidValue" SG_ 1299 BMS_PackCurrentDis 65535;
BA_ "GenSigStartValue" SG_ 1299 BMS_PackCurrentDis 65535;
BA_ "GenSigSendType" SG_ 1099 ISGF_SysTempOvrInd 0;
BA_ "GenSigSendType" SG_ 1130 TCU_23_GBFaultstatus 0;
BA_ "GRC_Sig_ASIL" SG_ 1130 TCU_23_TeachInState 1;
BA_ "GenSigSendType" SG_ 1130 TCU_23_TeachInState 0;
BA_ "GenSigSendType" SG_ 1180 New_Signal_49C_9 0;
BA_ "E2EDataId" SG_ 1180 New_Signal_49C_9 173;
BA_ "E2EProfile" SG_ 1180 New_Signal_49C_9 "P01";
BA_ "E2EDataLength" SG_ 1180 New_Signal_49C_9 64;
BA_ "GenSigSendType" SG_ 1180 New_Signal_49C_8 0;
BA_ "E2EDataId" SG_ 1180 New_Signal_49C_8 173;
BA_ "E2EProfile" SG_ 1180 New_Signal_49C_8 "P01";
BA_ "E2EDataLength" SG_ 1180 New_Signal_49C_8 64;
BA_ "GenSigSendType" SG_ 1180 New_Signal_49C_7 0;
BA_ "E2EDataId" SG_ 1180 New_Signal_49C_7 173;
BA_ "E2EProfile" SG_ 1180 New_Signal_49C_7 "P01";
BA_ "E2EDataLength" SG_ 1180 New_Signal_49C_7 64;
BA_ "GenSigSendType" SG_ 1180 New_Signal_49C_6 0;
BA_ "E2EDataId" SG_ 1180 New_Signal_49C_6 173;
BA_ "E2EProfile" SG_ 1180 New_Signal_49C_6 "P01";
BA_ "E2EDataLength" SG_ 1180 New_Signal_49C_6 64;
BA_ "GenSigSendType" SG_ 1180 New_Signal_49C_5 0;
BA_ "E2EDataId" SG_ 1180 New_Signal_49C_5 173;
BA_ "E2EProfile" SG_ 1180 New_Signal_49C_5 "P01";
BA_ "E2EDataLength" SG_ 1180 New_Signal_49C_5 64;
BA_ "GenSigSendType" SG_ 1180 New_Signal_49C_4 0;
BA_ "E2EDataId" SG_ 1180 New_Signal_49C_4 173;
BA_ "E2EProfile" SG_ 1180 New_Signal_49C_4 "P01";
BA_ "E2EDataLength" SG_ 1180 New_Signal_49C_4 64;
BA_ "GenSigSendType" SG_ 1180 New_Signal_49C_3 0;
BA_ "E2EDataId" SG_ 1180 New_Signal_49C_3 173;
BA_ "E2EProfile" SG_ 1180 New_Signal_49C_3 "P01";
BA_ "E2EDataLength" SG_ 1180 New_Signal_49C_3 64;
BA_ "GenSigSendType" SG_ 1180 New_Signal_49C_2 0;
BA_ "E2EDataId" SG_ 1180 New_Signal_49C_2 173;
BA_ "E2EProfile" SG_ 1180 New_Signal_49C_2 "P01";
BA_ "E2EDataLength" SG_ 1180 New_Signal_49C_2 64;
BA_ "GenSigSendType" SG_ 1180 New_Signal_49C_1 0;
BA_ "E2EDataId" SG_ 1180 New_Signal_49C_1 173;
BA_ "E2EProfile" SG_ 1180 New_Signal_49C_1 "P01";
BA_ "E2EDataLength" SG_ 1180 New_Signal_49C_1 64;
BA_ "GenSigSendType" SG_ 1180 ACU_1_RollgCntr1 0;
BA_ "E2EDataId" SG_ 1180 ACU_1_RollgCntr1 173;
BA_ "E2EProfile" SG_ 1180 ACU_1_RollgCntr1 "P01";
BA_ "E2EDataLength" SG_ 1180 ACU_1_RollgCntr1 64;
BA_ "GenSigSendType" SG_ 1180 ACU_1_CRC1 0;
BA_ "E2EDataId" SG_ 1180 ACU_1_CRC1 173;
BA_ "E2EProfile" SG_ 1180 ACU_1_CRC1 "P01";
BA_ "E2EDataLength" SG_ 1180 ACU_1_CRC1 64;
BA_ "GenSigSendType" SG_ 1180 ABM_1_Rollover_Status 0;
BA_ "GRC_Sig_ASIL" SG_ 1180 ABM_1_Rollover_Status 2;
BA_ "E2EDataId" SG_ 1180 ABM_1_Rollover_Status 173;
BA_ "E2EProfile" SG_ 1180 ABM_1_Rollover_Status "P01";
BA_ "E2EDataLength" SG_ 1180 ABM_1_Rollover_Status 64;
BA_ "GenSigSendType" SG_ 1180 ACU_1_AirBagFailSts 0;
BA_ "GenSigStartValue" SG_ 1180 ACU_1_AirBagFailSts 3;
BA_ "E2EDataId" SG_ 1180 ACU_1_AirBagFailSts 173;
BA_ "E2EProfile" SG_ 1180 ACU_1_AirBagFailSts "P01";
BA_ "E2EDataLength" SG_ 1180 ACU_1_AirBagFailSts 64;
BA_ "GenSigSendType" SG_ 1180 ACU_1_ThdRowLBeltWarning 0;
BA_ "E2EDataId" SG_ 1180 ACU_1_ThdRowLBeltWarning 173;
BA_ "E2EProfile" SG_ 1180 ACU_1_ThdRowLBeltWarning "P01";
BA_ "E2EDataLength" SG_ 1180 ACU_1_ThdRowLBeltWarning 64;
BA_ "GenSigSendType" SG_ 1180 ACU_1_ThdRowRBeltWarning 0;
BA_ "E2EDataId" SG_ 1180 ACU_1_ThdRowRBeltWarning 173;
BA_ "E2EProfile" SG_ 1180 ACU_1_ThdRowRBeltWarning "P01";
BA_ "E2EDataLength" SG_ 1180 ACU_1_ThdRowRBeltWarning 64;
BA_ "GenSigSendType" SG_ 1180 ACU_1_PsngrSeatBeltWarning 0;
BA_ "E2EDataId" SG_ 1180 ACU_1_PsngrSeatBeltWarning 173;
BA_ "E2EProfile" SG_ 1180 ACU_1_PsngrSeatBeltWarning "P01";
BA_ "E2EDataLength" SG_ 1180 ACU_1_PsngrSeatBeltWarning 64;
BA_ "GenSigSendType" SG_ 1180 ACU_1_SecRowLBeltWarning 0;
BA_ "E2EDataId" SG_ 1180 ACU_1_SecRowLBeltWarning 173;
BA_ "E2EProfile" SG_ 1180 ACU_1_SecRowLBeltWarning "P01";
BA_ "E2EDataLength" SG_ 1180 ACU_1_SecRowLBeltWarning 64;
BA_ "GenSigSendType" SG_ 1180 ACU_1_SecRowMBeltWarning 0;
BA_ "E2EDataId" SG_ 1180 ACU_1_SecRowMBeltWarning 173;
BA_ "E2EProfile" SG_ 1180 ACU_1_SecRowMBeltWarning "P01";
BA_ "E2EDataLength" SG_ 1180 ACU_1_SecRowMBeltWarning 64;
BA_ "GenSigSendType" SG_ 1180 ACU_1_SecRowRBeltWarning 0;
BA_ "E2EDataId" SG_ 1180 ACU_1_SecRowRBeltWarning 173;
BA_ "E2EProfile" SG_ 1180 ACU_1_SecRowRBeltWarning "P01";
BA_ "E2EDataLength" SG_ 1180 ACU_1_SecRowRBeltWarning 64;
BA_ "GenSigSendType" SG_ 1180 ACU_1_PsngrSeatOccupiedSts 0;
BA_ "E2EDataId" SG_ 1180 ACU_1_PsngrSeatOccupiedSts 173;
BA_ "E2EProfile" SG_ 1180 ACU_1_PsngrSeatOccupiedSts "P01";
BA_ "E2EDataLength" SG_ 1180 ACU_1_PsngrSeatOccupiedSts 64;
BA_ "GenSigSendType" SG_ 1341 BMS_44_PackPowerRealTime 0;
BA_ "GenSigInvalidValue" SG_ 1341 BMS_44_PackPowerRealTime 16383;
BA_ "GenSigStartValue" SG_ 1341 BMS_44_PackPowerRealTime 10240;
BA_ "GenSigSendType" SG_ 811 BMS_Chg_Sts 0;
BA_ "GenSigInvalidValue" SG_ 811 BMS_Chg_Sts 15;
BA_ "GenSigSendType" SG_ 1269 LISDShowCMDSts 0;
BA_ "GenSigSendType" SG_ 1269 LISDShowModeSts 0;
BA_ "GenSigSendType" SG_ 1269 LISD_TransmitStatus 0;
BA_ "GenSigSendType" SG_ 1269 LISD_DisplayStatus 0;
BA_ "GenSigSendType" SG_ 1269 LISD_ParkingShowModSts 0;
BA_ "GenSigSendType" SG_ 1269 LISD_ParkingShowCMDSts 0;
BA_ "GenSigSendType" SG_ 1233 RISDShowCMDSts 0;
BA_ "GenSigSendType" SG_ 1233 RISDShowModeSts 0;
BA_ "GenSigSendType" SG_ 1233 RISD_TransmitStatus 0;
BA_ "GenSigSendType" SG_ 1233 RISD_DisplayStatus 0;
BA_ "GenSigSendType" SG_ 1233 RISD_ParkingShowModSts 0;
BA_ "GenSigSendType" SG_ 1233 RISD_ParkingShowCMDSts 0;
BA_ "GenSigSendType" SG_ 1169 LC_DIYMusicShowModSts 0;
BA_ "GenSigSendType" SG_ 1169 LC_RandomMusicShowSts 0;
BA_ "GenSigSendType" SG_ 1169 LC_LiShowModSts 0;
BA_ "GenSigSendType" SG_ 1427 ILCF_1_LogoParkingSts 0;
BA_ "GenSigStartValue" SG_ 1427 ILCF_1_LogoParkingSts 1;
BA_ "GenSigSendType" SG_ 1427 ILCF_1_LogoChargingSts 0;
BA_ "GenSigSendType" SG_ 1427 ILCF_1_DIYMusicShowModSts 0;
BA_ "GenSigSendType" SG_ 1427 ILCF_1_RandomMusicShowSts 0;
BA_ "GenSigSendType" SG_ 1427 ILCF_1_LogoColorAdjSts 0;
BA_ "GenSigStartValue" SG_ 1427 ILCF_1_LogoColorAdjSts 117;
BA_ "GenSigSendType" SG_ 821 ADS_5_CRC1 0;
BA_ "GenSigSendType" SG_ 821 ADS_5_RollgCntr1 0;
BA_ "GenSigSendType" SG_ 821 ADS_5_Resd1 0;
BA_ "GenSigSendType" SG_ 821 ADS_5_ILOASts 0;
BA_ "GenSigSendType" SG_ 821 ADS_5_ICAQuitReason 0;
BA_ "GenSigSendType" SG_ 821 ADS_5_ISLISt 0;
BA_ "GenSigSendType" SG_ 821 ADS_5_ILOATextInfo 0;
BA_ "GenSigSendType" SG_ 821 ADS_5_ILOAActdirection 0;
BA_ "GenSigSendType" SG_ 821 ADS_5_LKS_warning 0;
BA_ "GenSigSendType" SG_ 821 ADS_5_ISLIOverSpeedWarn 0;
BA_ "GenSigSendType" SG_ 821 ADS_5_ISLISpeedLimitSign 0;
BA_ "GenSigSendType" SG_ 821 ADS_5_EgoLeftLineHeatgAg 0;
BA_ "GenSigSendType" SG_ 821 ADS_5_EgoLeLineID 0;
BA_ "GenSigSendType" SG_ 821 ADS_5_EgoLeLineColor 0;
BA_ "GenSigSendType" SG_ 821 ADS_5_EgoLeLineTyp 0;
BA_ "GenSigSendType" SG_ 821 ADS_5_EgoLeLineHozlDst 0;
BA_ "GenSigSendType" SG_ 821 ADS_5_CRC2 0;
BA_ "GenSigSendType" SG_ 821 ADS_5_RollgCntr2 0;
BA_ "GenSigSendType" SG_ 821 ADS_5_Resd2 0;
BA_ "GenSigSendType" SG_ 821 ADS_5_NeborLeLineID 0;
BA_ "GenSigSendType" SG_ 821 ADS_5_NeborLeLineColor 0;
BA_ "GenSigSendType" SG_ 821 ADS_5_NeborLeLineTyp 0;
BA_ "GenSigSendType" SG_ 821 ADS_5_EgoLeLineCrvt 0;
BA_ "GenSigSendType" SG_ 821 ADS_5_NeborLeLineHozlDst 0;
BA_ "GenSigSendType" SG_ 821 ADS_5_NeborRiLineID 0;
BA_ "GenSigSendType" SG_ 821 ADS_5_NeborRiLineColor 0;
BA_ "GenSigSendType" SG_ 821 ADS_5_NeborRiLineTyp 0;
BA_ "GenSigSendType" SG_ 821 ADS_5_NeborLeLineCrvt 0;
BA_ "GenSigSendType" SG_ 821 ADS_5_NeborRiLineHozlDst 0;
BA_ "GenSigSendType" SG_ 821 ADS_5_CRC3 0;
BA_ "GenSigSendType" SG_ 821 ADS_5_RollgCntr3 0;
BA_ "GenSigSendType" SG_ 821 ADS_5_Resd3 0;
BA_ "GenSigSendType" SG_ 821 ADS_5_ELKSettingSt 0;
BA_ "GenSigSendType" SG_ 821 ADS_5_LDWLDPSnvtySet 0;
BA_ "GenSigSendType" SG_ 821 ADS_5_LDWWarnType 0;
BA_ "GenSigSendType" SG_ 821 ADS_5_NeborRiLineCrvt 0;
BA_ "GenSigSendType" SG_ 821 ADS_5_IESSwtSet 0;
BA_ "GenSigSendType" SG_ 821 ADS_5_IHCSettingSt 0;
BA_ "GenSigSendType" SG_ 821 ADS_5_ISLIWarningMod 0;
BA_ "GenSigSendType" SG_ 821 ADS_5_ICAEnableBtnSts 0;
BA_ "GenSigSendType" SG_ 821 ADS_5_FCM_Camera_textinfo 0;
BA_ "GenSigSendType" SG_ 821 ADS_5_EgoRiLineID 0;
BA_ "GenSigSendType" SG_ 821 ADS_5_EgoRiLineTyp 0;
BA_ "GenSigSendType" SG_ 821 ADS_5_EgoRiLineColor 0;
BA_ "GenSigSendType" SG_ 821 ADS_5_EgoRiLineHozlDst 0;
BA_ "GenSigInvalidValue" SG_ 821 ADS_5_EgoRiLineHozlDst 511;
BA_ "GenSigSendType" SG_ 821 ADS_5_CRC4 0;
BA_ "GenSigSendType" SG_ 821 ADS_5_RollgCntr4 0;
BA_ "GenSigSendType" SG_ 821 ADS_5_Resd4 0;
BA_ "GenSigSendType" SG_ 821 ADS_5_EgoRightLineHeatgAg 0;
BA_ "GenSigInvalidValue" SG_ 821 ADS_5_EgoRightLineHeatgAg 511;
BA_ "GenSigSendType" SG_ 821 ADS_5_EgoRiLineCrvt 0;
BA_ "GenSigInvalidValue" SG_ 821 ADS_5_EgoRiLineCrvt 1023;
BA_ "GenSigSendType" SG_ 821 ADS_5_NeborLeftLineHeatgAg 0;
BA_ "GenSigInvalidValue" SG_ 821 ADS_5_NeborLeftLineHeatgAg 511;
BA_ "GenSigSendType" SG_ 821 ADS_5_NeborRightLineHeatgAg 0;
BA_ "GenSigInvalidValue" SG_ 821 ADS_5_NeborRightLineHeatgAg 511;
BA_ "GenSigSendType" SG_ 819 ADS_4_CRC1 0;
BA_ "GenSigSendType" SG_ 819 ADS_4_RollgCntr1 0;
BA_ "GenSigSendType" SG_ 819 ADS_4_Resd1 0;
BA_ "GenSigSendType" SG_ 819 ADS_4_AEBStatus 0;
BA_ "GenSigSendType" SG_ 819 ADS_4_ACCSts 0;
BA_ "GenSigSendType" SG_ 819 ADS_4_TimeGapSet 0;
BA_ "GenSigSendType" SG_ 819 ADS_4_FcwMode 0;
BA_ "GenSigSendType" SG_ 819 ADS_4_AEBReqType 0;
BA_ "GenSigSendType" SG_ 819 ADS_4_SetSpd 0;
BA_ "GenSigSendType" SG_ 819 ADS_4_DAIStatus 0;
BA_ "GenSigSendType" SG_ 819 ADS_4_ACCTextMessage 0;
BA_ "GenSigSendType" SG_ 819 ADS_4_LongiTakeOverReq 0;
BA_ "GenSigSendType" SG_ 819 ADS_4_SetSpdUnit 0;
BA_ "GenSigSendType" SG_ 819 ADS_4_GoNotifier 0;
BA_ "GenSigSendType" SG_ 819 ADS_4_DAISts 0;
BA_ "GenSigSendType" SG_ 819 ADS_4_Radar_textinfo 0;
BA_ "GenSigSendType" SG_ 819 ADS_4_SCF_PopoverReq 0;
BA_ "GenSigSendType" SG_ 819 ADS_4_DrvrCfmSCFDispFb 0;
BA_ "GenSigSendType" SG_ 819 ADS_4_SCF_SpdLimUnit 0;
BA_ "GenSigSendType" SG_ 819 ADS_4_SCF_SpdLimSts 0;
BA_ "GenSigSendType" SG_ 819 ADS_4_CRC2 0;
BA_ "GenSigSendType" SG_ 819 ADS_4_RollgCntr2 0;
BA_ "GenSigSendType" SG_ 819 ADS_4_Resd2 0;
BA_ "GenSigSendType" SG_ 819 ADS_4_ACCObjTyp 0;
BA_ "GenSigSendType" SG_ 819 ADS_4_FrntFarObjTyp 0;
BA_ "GenSigSendType" SG_ 819 ADS_4_ACCObjLgtDstX 0;
BA_ "GenSigSendType" SG_ 819 ADS_4_FrntFarObjID 0;
BA_ "GenSigSendType" SG_ 819 ADS_4_Resd 0;
BA_ "GenSigSendType" SG_ 819 ADS_4_ACCObjID 0;
BA_ "GenSigSendType" SG_ 819 ADS_4_ACCObjHozDstY 0;
BA_ "GenSigSendType" SG_ 819 ADS_4_FrntFarObjHozDstY 0;
BA_ "GenSigSendType" SG_ 819 ADS_4_FrntFarObjLgtDstX 0;
BA_ "GenSigSendType" SG_ 819 ADS_4_CRC3 0;
BA_ "GenSigSendType" SG_ 819 ADS_4_RollgCntr3 0;
BA_ "GenSigSendType" SG_ 819 ADS_4_Resd3 0;
BA_ "GenSigSendType" SG_ 819 ADS_4_Resd_1 0;
BA_ "GenSigSendType" SG_ 819 ADS_4_LeObjID 0;
BA_ "GenSigSendType" SG_ 819 ADS_4_LeObjTyp 0;
BA_ "GenSigSendType" SG_ 819 ADS_4_LeObjHozDstY 0;
BA_ "GenSigSendType" SG_ 819 ADS_4_LeObjLgtDstX 0;
BA_ "GenSigSendType" SG_ 819 ADS_4_RiObjID 0;
BA_ "GenSigSendType" SG_ 819 ADS_4_RiObjTyp 0;
BA_ "GenSigSendType" SG_ 819 ADS_4_RiObjHozDstY 0;
BA_ "GenSigSendType" SG_ 819 ADS_4_RiObjLgtDstX 0;
BA_ "GenSigSendType" SG_ 819 ADS_4_CRC4 0;
BA_ "GenSigSendType" SG_ 819 ADS_4_RollgCntr4 0;
BA_ "GenSigSendType" SG_ 819 ADS_4_Resd4 0;
BA_ "GenSigSendType" SG_ 819 ADS_4_SCFSwtSet 0;
BA_ "GenSigSendType" SG_ 819 ADS_4_AEBSettingSt 0;
BA_ "GenSigSendType" SG_ 819 ADS_4_FCWSettingSt 0;
BA_ "GenSigSendType" SG_ 819 ADS_4_DAISwtSet 0;
BA_ "GenSigSendType" SG_ 819 ADS_4_CruiseAccelerateSts 0;
BA_ "GenSigSendType" SG_ 1172 ExternalTemperature_F 0;
BA_ "GenSigStartValue" SG_ 1172 ExternalTemperature_F 225;
BA_ "GenSigSendType" SG_ 1172 ExternalTemperature_C 0;
BA_ "GenSigInvalidValue" SG_ 1172 ExternalTemperature_C 254;
BA_ "GenSigStartValue" SG_ 1172 ExternalTemperature_C 254;
BA_ "GenSigSendType" SG_ 1172 BlowSpeedLevelDisplaySts 0;
BA_ "GenSigSendType" SG_ 1147 CCP_1_FLTempSwitchReq 0;
BA_ "GenSigInvalidValue" SG_ 1147 CCP_1_FLTempSwitchReq 31;
BA_ "GenSigStartValue" SG_ 1147 CCP_1_FLTempSwitchReq 31;
BA_ "GenSigSendType" SG_ 1147 CCP_1_FrontAutoACSwitchReq 0;
BA_ "GenSigSendType" SG_ 1147 CCP_1_FrontOFFSwitchReq 0;
BA_ "GenSigSendType" SG_ 1147 CCP_1_FBlowSpdCtrlSwitchReq 0;
BA_ "GenSigSendType" SG_ 1147 FLCCP_MainSetHeatReq 0;
BA_ "GenSigSendType" SG_ 1147 FLCCP_MainSetVentilationReq 0;
BA_ "GenSigSendType" SG_ 1147 CCP_1_ACFastCool 0;
VAL_ 1324 TirePositionWarning_LHFTire 0 "Normal" 1 "Rapid_Air_Loss(Reserved)" 2 "Low_Pressure" 3 "Low Batter" 4 "High_Pressure(Reserved)" 5 "High_Temperature" 6 "Error_Mode" 7 "Not_used(Reserved)" ;
VAL_ 1324 TirePositionWarning_RHFTire 0 "Normal" 1 "Rapid_Air_Loss(Reserved)" 2 "Low_Pressure" 3 "Low Batter" 4 "High_Pressure(Reserved)" 5 "High_Temperature" 6 "Error_Mode" 7 "Not_used(Reserved)" ;
VAL_ 1324 TirePositionWarning_LHRTire 0 "Normal" 1 "Rapid_Air_Loss(Reserved)" 2 "Low_Pressure" 3 "Low Batter" 4 "High_Pressure(Reserved)" 5 "High_Temperature" 6 "Error_Mode" 7 "Not_used(Reserved)" ;
VAL_ 1324 TirePositionWarning_RHRTire 0 "Normal" 1 "Rapid_Air_Loss(Reserved)_" 2 "Low_Pressure" 3 "Low Batter" 4 "High_Pressure(Reserved)" 5 "High_Temperature" 6 "Error_Mode" 7 "Not_used(Reserved)" ;
VAL_ 1324 TirePressureWarningLampSts 0 "Lamp_Off" 1 "Lamp_Flashing(Reserved)" 2 "Lamp_On" 3 "Not_used" ;
VAL_ 1324 TirePressureSystemFailSts 0 "Fail_Not_Present" 1 "Fail_Present" ;
VAL_ 991 TMS_MotorLoopErrorLevel 0 "No Error" 1 "Derating function" 2 "Disabler" 3 "ShutDown" 4 "Reserved" 5 "Reserved" 6 "Reserved" 7 "Reserved" ;
VAL_ 991 TMS_BatteryLoopErrorLevel 0 "No Error（无差错）" 1 "Derating function（降额功能）" 2 "Disabler（解除）" 3 "ShutDown（关闭）" 4 "Reserved（保留）" 5 "Reserved（保留）" 6 "Reserved（保留）" 7 "Reserved（保留）" ;
VAL_ 1188 FrontDeforestDisplaySts 0 "Not_Active" 1 "Active" ;
VAL_ 1188 TMS_DisplayActive 0 "Off" 1 "On" ;
VAL_ 1188 TMS_ZoneSelectionDisplaySts 0 "Single_zone_mode" 1 "Dual_zone_mode" ;
VAL_ 1188 TMS_AutoDisplaySts 0 "Auto_Off" 1 "Auto_On" ;
VAL_ 1188 TMS_FiltertchangeDisplaySts 0 "Off" 1 "On" ;
VAL_ 1188 TMS_AUTODefrostOnSts 0 "Off" 1 "On" ;
VAL_ 1188 TMS_AUTODefrostDisplaySts 0 "Off" 1 "On" ;
VAL_ 1188 TMS_RefInSufDispSts 0 "Off" 1 "On" ;
VAL_ 1188 TMS_CooltInSufDispSts 0 "Off" 1 "On" ;
VAL_ 1188 TMS_DLOnOffSts 0 "Off" 1 "On" ;
VAL_ 1188 TMS_DROnOffSts 0 "Off" 1 "On" ;
VAL_ 1188 TMS_PLOnOffSts 0 "Off" 1 "On" ;
VAL_ 1188 WorkingSts 0 "Not_Active" 1 "Active" ;
VAL_ 1188 TMS_PROnOffSts 0 "Off" 1 "On" ;
VAL_ 1188 TMS_DCOnOffSts 0 "Off" 1 "On" ;
VAL_ 1188 TMS_ACFastCool 0 "Off" 1 "On" ;
VAL_ 1188 TMS_ACFastHeat 0 "Off" 1 "On" ;
VAL_ 1188 TMS_LoveRemind 0 "Off" 1 "On" ;
VAL_ 1188 TMS_InteCleanCar 0 "Off" 1 "On" ;
VAL_ 1188 TMS_ACVentilationSts 0 "Off" 1 "On" ;
VAL_ 1188 TMS_AutoAirCleanSts 0 "Off" 1 "On" ;
VAL_ 1188 PM25Sts 0 "Not_Active" 1 "Active" ;
VAL_ 1188 TMS_ACModeCustomSts 0 "Not_active" 1 "ECO" 2 "Comfortable" 3 "Strong________________________________________________________" ;
VAL_ 1188 TMS_ACRequestDisplaySts 0 "Off" 1 "On" ;
VAL_ 1188 TMS_AUTODefLevelSts 0 "Not_Active" 1 "OFF" 2 "Low" 3 "Medium" 4 "High" ;
VAL_ 1188 TMS_KeepWarm 0 "Not_active" 1 "Open_AC_" 2 "Open_NotAC" 3 "Closed" ;
VAL_ 1188 TMS_DSwingSts 0 "Not_active" 1 "AllZone_Swing" 2 "Single_Swing" 3 "Mirro_Swing" 4 "Free_Swing" ;
VAL_ 1188 TMS_PSwingSts 0 "Not_active" 1 "AllZone_Swing" 2 "Single_Swing" 3 "Mirro_Swing" 4 "Free_Swing" ;
VAL_ 1188 TMS_TuisongDispSts 0 "Not_Request" 1 "Avoid_fog" 2 "Enhanced_Def" 3 "Enhanced_Purification" 4 "Swing_Operation" ;
VAL_ 1188 TMS_ModeAdjustDisplaySts 0 "BlowFace" 1 "BlowFaceAndBlowFoot" 2 "BlowFoot" 3 "BlowFootAndBlowWindow" 4 "BlowWindow" 5 "Not Active" 6 "BlowFaceAndBlowWindow" 7 "BlowFaceAndBlowFootAndBlowWindow" 8 "Auto" ;
VAL_ 1188 TMS_CirculationModeDisplaySts 0 "Recirculation_mode" 1 "Air_circulation_mode" 2 "Two-Layer_Flow_Mode" 3 "Reserved" ;
VAL_ 1188 AirSwingSts 0 "Off" 1 "On" ;
VAL_ 1188 TemperatureUnit 0 "Centigrade(℃)" 1 "Fahrenheit(℉)" ;
VAL_ 1188 BlowAdvanceOnSts 0 "AdvanceOn" 1 "Not_AdvanceOn" ;
VAL_ 1188 BlowDelayOffSts 0 "DelayOff" 1 "Not_DelayOff" ;
VAL_ 1188 TMS_PM25_ExtSts 0 "Normal" 1 "failure" ;
VAL_ 1188 TMS_PM25_IncarSts 0 "Normal" 1 "failure" ;
VAL_ 1188 TMS_AQS_Sts 0 "Normal" 1 "failure" ;
VAL_ 1188 PM25overproofDisplaySts 0 "Off" 1 "On" ;
VAL_ 1188 AQSDisplaySts 0 "Off" 1 "On" ;
VAL_ 1188 PM25AutoRunSts 0 "Off" 1 "On" ;
VAL_ 1188 PM25AutoRunSetSts 0 "Off" 1 "On" ;
VAL_ 1188 FragranceWelcomeModeSts 0 "Off" 1 "On" ;
VAL_ 1188 FragranceDisplaysts 0 "Off" 1 "On" ;
VAL_ 1188 TMS_AQS_Level 0 "Good" 1 "Light_pollution" 2 "Moderate_pollution" 3 "High_levels_of_pollution" ;
VAL_ 1188 ACRequestCommand 0 "Not_Active" 1 "Cooling" 2 "Heating" 3 "Venting" 4 "Auto" ;
VAL_ 1188 PM25_Outcar_Level 0 "Good" 1 "Favorable_pollution" 2 "Light_pollution" 3 "Moderate_pollution" 4 "High_levels_of_pollution" 5 "Serious_pollution" 6 "Reserved" 7 "Reserved" ;
VAL_ 1188 PM25_Incar_Level 0 "Good" 1 "Favorable_pollution" 2 "Light_pollution" 3 "Moderate_pollution" 4 "High_levels_of_pollution" 5 "Serious_pollution" 6 "Reserved" 7 "Reserved" ;
VAL_ 1188 TMS_KeepWarmMemoryFb 0 "Not_Active" 1 "Memory_On" 2 "Memory_Off" 3 "Not_Used" ;
VAL_ 612 EPB_1_FltLamp 0 "Lamp OFF" 1 "Lamp ON" 2 "Lamp Flash" 3 "Reserved" ;
VAL_ 612 EPB_1_ParkLamp 0 "Lamp OFF" 1 "Lamp ON" 2 "Lamp Flash" 3 "Reserved" ;
VAL_ 612 EPB_1_ActrSt 0 "Unknow" 1 "Applied" 2 "Released" 3 "Applying" 4 "Releasing" 5 "CompletelyReleased" 6 "Half Applied" 7 "Reserved" ;
VAL_ 612 EPB_1_RWUSt 0 "No active" 1 "active" ;
VAL_ 612 EPB_1_TextDisp 0 "NO text message" 1 "Gradient too high" 2 "Clampforce not enough" 3 "fasten seatbelt" 4 "Press brake pedal" 5 "No_Release_Tip_for_Shift" 6 "Reserved" 7 "Reserved" 8 "Reserved" 9 "Reserved" 10 "Reserved" 11 "Reserved" 12 "Reserved" 13 "Reserved" 14 "Reserved" 15 "Reserved" ;
VAL_ 612 IPB_EPBErrorStatus 0 "No_Error" 1 "Error" ;
VAL_ 1193 AVHWarningMessage 0 "Off" 1 "Fasten DriverSeatBelt and Close the LHF door" ;
VAL_ 1193 CDPActive 0 "Not active" 1 "Active" ;
VAL_ 1193 HDCFailSts 0 "Fail not present" 1 "Fail present (lamp on)" ;
VAL_ 1193 HDCCtrlSts 0 "OFF" 1 "not active braking(lamp on)" 2 "On active braking(flash)" 3 "Not used" ;
VAL_ 1193 AVHSts 0 "Off" 1 "Standby" 2 "Active" 3 "Not Used" ;
VAL_ 1193 AVHFailSts 0 "Fail not present" 1 "Fail present (lamp on)" ;
VAL_ 1193 FWAWarningSts 0 "No failure" 1 "BrakeSys High Temperature Leve1" 2 "BrakeSys High Temperature Leve2" 3 "Not used" ;
VAL_ 1193 BrakeFluidSts 0 "Normal" 1 "Empty" 2 "Electric_error" 3 "Not used" ;
VAL_ 1193 BrakesystemFailSts 0 "Fail not present" 1 "Fail present" ;
VAL_ 1197 CST_Status 0 "CST is disabled" 1 "CST is Standby" 2 "CST is Active" 3 "CST is Failure" ;
VAL_ 1197 BrakepedalFeelSts 0 "Comfort" 1 "Sport" 2 "Offroad" 3 "Reserved" ;
VAL_ 1197 CST_SensitivitySts 0 "Not Active" 1 "Comfort Low" 2 "Comfort Middle" 3 "Comfort High" ;
VAL_ 1061 DriverSeatMsgStr_LvlSts 0 "OFF/Intial" 1 "Low" 2 "Middle" 3 "High" ;
VAL_ 1061 DriverSeatMsg_ModeSts 0 "NotActive" 1 "PulseMode" 2 "WaveMode" 3 "CatPawMode" 4 "SigleRowMode" 5 "CrossMode" 6 "ButterflyMode" 7 "WaistMode" 8 "SnakeMode" 9 "Special 1" 10 "Special 2" 11 "Special 3" 12 "Special 4" ;
VAL_ 1065 LeftSeatMsgStr_LvlSts 0 "OFF/Intial" 1 "Low" 2 "Middle" 3 "High" 4 "Reserved" 5 "Reserved" 6 "Reserved" 7 "Reserved" ;
VAL_ 1065 LeftSeatMsg_ModeSts 0 "NotActive" 1 "PulseMode" 2 "WaveMode" 3 "CatPawMode" 4 "SigleRowMode" 5 "CrossMode" 6 "ButterflyMode" 7 "WaistMode" 8 "SnakeMode" 9 "Special 1" 10 "Special 2" 11 "Special 3" 12 "Special 4" ;
VAL_ 1069 PassSeatMsgStr_LvlSts 0 "OFF/Intial" 1 "Low" 2 "Middle" 3 "High" 4 "Reserved" 5 "Reserved" 6 "Reserved" 7 "Reserved" ;
VAL_ 1069 PassSeatMsg_ModeSts 0 "NotActive" 1 "PulseMode" 2 "WaveMode" 3 "CatPawMode" 4 "SigleRowMode" 5 "CrossMode" 6 "ButterflyMode" 7 "WaistMode" 8 "SnakeMode" 9 "Special 1" 10 "Special 2" 11 "Special 3" 12 "Special 4" ;
VAL_ 1087 RightSeatMsgStr_LvlSts 0 "OFF/Intial" 1 "Low" 2 "Middle" 3 "High" 4 "Reserved" 5 "Reserved" 6 "Reserved" 7 "Reserved" ;
VAL_ 1087 RightSeatMsg_ModeSts 0 "NotActive" 1 "PulseMode" 2 "WaveMode" 3 "CatPawMode" 4 "SigleRowMode" 5 "CrossMode" 6 "ButterflyMode" 7 "WaistMode" 8 "SnakeMode" 9 "Special 1" 10 "Special 2" 11 "Special 3" 12 "Special 4" ;
VAL_ 1189 SRF_OperateSts 0 "Not Active" 1 "Tilt" 2 "Close" 3 "Opening" 4 "Stop" 5 "Closing" 6 "Open" 7 "Comfort_open" ;
VAL_ 1189 SRF_PositionSts 0 "Not Active" 1 "0%" 2 "10%" 3 "20%" 4 "30%" 5 "40%" 6 "50%" 7 "60%" 8 "70%" 9 "80%" 10 "90%" 11 "100%" 12 "Tilt" ;
VAL_ 1189 SRF_OverHeatProtect 0 "No_Error_Inactive" 1 "Active" ;
VAL_ 1189 SRF_Sunshade_OperateSts 0 "Not Active" 1 "Close" 2 "Opening" 3 "Stop" 4 "Closing" 5 "Open" 6 "Half_Open" 7 "Reserved" ;
VAL_ 1189 Sunshade_OverHeatProtect 0 "No_Error_Inactive" 1 "Active" ;
VAL_ 1192 SRF_Sunroof_ActualSts 0 "Not Active" 1 "Open" 2 "Close" 3 "Tilt" 4 "Reserved" 5 "Reserved" 6 "Reserved" 7 "Error" ;
VAL_ 1192 SRF_Sunshade_ActualSts 0 "Not Active" 1 "Open" 2 "Close" 3 "Tilt" 4 "Reserved" 5 "Reserved" 6 "Reserved" 7 "Error" ;
VAL_ 1192 SRF_Sunshade_PositionSts 0 "Not Active" 1 "0%" 2 "10%" 3 "20%" 4 "30%" 5 "40%" 6 "50%" 7 "60%" 8 "70%" 9 "80%" 10 "90%" 11 "100%" 12 "Reserved" ;
VAL_ 1143 OBC_CC_ConnectSts 0 "Not connected" 1 "Charge Connected" 2 "V2V" 3 "V2L" 4 "Half Connection" 5 "Error" 6 "Reserved" 7 "Reserved" ;
VAL_ 1143 CDU_MILSts 0 "Not Active" 1 "Active" ;
VAL_ 1295 BMS_BattFaultLampSts 0 "Lamp OFF" 1 "Lamp ON" ;
VAL_ 1295 BMS_OverTemp_LightSts 0 "Lamp OFF" 1 "Lamp ON" ;
VAL_ 1295 BMS_RemainChg_Time 2047 "Invalid" ;
VAL_ 1295 BMS_ThermalRunawayDis 0 "no thermalrunaway" 1 "thermalrunaway occur" ;
VAL_ 1295 BMS_TBOXIsolationFault 0 "no fault" 1 "Fault L1" 2 "Fault L2" 3 "Fault L3" ;
VAL_ 1295 BMS_PreWarmDis 0 "none" 1 "preheat state" 2 "keepwarm state" ;
VAL_ 1531 BMS_HvBattSoeActDisChaCyc 65534 "Abnormal" 65535 "Invalid" ;
VAL_ 1531 BMS_HvBattSoeActReChaCyc 65534 "Abnormal" 65535 "Invalid" ;
VAL_ 1531 BMS_HvBattRatedEnergy 16382 "Abnormal" 16383 "Invalid" ;
VAL_ 1531 BMS_HvBattRatedU 16382 "Abnormal" 16383 "Invalid" ;
VAL_ 1531 BMS_HvBattTypeCode 0 "reserved" 1 "LFP" 2 "LMO" 3 "LCO" 4 "NCM" 5 "Polymer Lithium ion" 6 "Supercapacitors" 7 "LTO" 252 "Fuel Cell" 255 "other type" ;
VAL_ 1531 BMS_HvBattManufcCode -2147483648 "Abnormal" -2147483648 "Invalid" ;
VAL_ 1531 BMS_HvBattTempSensorTotalNum 65534 "Abnormal" 65535 "Invalid" ;
VAL_ 1531 BMS_HvBattTempSensorTempMaxNum 254 "Abnormal" 255 "Invalid" ;
VAL_ 1531 BMS_HvBattTempSensorTempMinNum 254 "Abnormal" 255 "Invalid" ;
VAL_ 1531 BMS_HvBattTempMaxNum 254 "Abnormal" 255 "Invalid" ;
VAL_ 1531 BMS_HvBattTempMinNum 254 "Abnormal" 255 "Invalid" ;
VAL_ 1531 BMS_BattCellTotalNum 65534 "Abnormal" 65535 "Invalid" ;
VAL_ 1531 BMS_HvBattVoltMaxNum 254 "Abnormal" 255 "Invalid" ;
VAL_ 1531 BMS_HvBattVoltMinNum 254 "Abnormal" 255 "Invalid" ;
VAL_ 1531 BMS_ActualSOCMin 4095 "Invalid" ;
VAL_ 1531 BMS_ActualSOCMax 4095 "Invalid" ;
VAL_ 1224 BMS_HvBattCellVoltMax_Num 254 "Abnormal" 255 "Invalid" ;
VAL_ 1224 BMS_HvBattCellVoltMax 65534 "Abnormal" 65535 "Invalid" ;
VAL_ 1224 BMS_HvBattCellVoltMin_Num 254 "Abnormal" 255 "Invalid" ;
VAL_ 1224 BMS_HvBattCellVoltMin 65534 "Abnormal" 65535 "Invalid" ;
VAL_ 1224 BMS_Chg_Sts 1 "Parking chagre" 2 "Driving charge" 3 "no charge" 4 "charge complete" 14 "Abnomal" 15 "Invalid" ;
VAL_ 1235 EPS_2_Steer_ReturnRmd_Sts 0 "No_Active" 1 "ON" 2 "OFF" 3 "Reserved" ;
VAL_ 1235 EPS_2_Steer_ReturnRmd 0 "No Tip" 1 "Tip return finish" 2 "Tip return left" 3 "Tip return right" ;
VAL_ 1235 EPS_2_MFS_ShakeSts 0 "No_Active" 1 "ON" 2 "OFF" 3 "reserved" ;
VAL_ 1330 DWD_TextDisp 0 "No Active" 1 "Speed exceed 10km/h" 2 "Speed exceed 5km/h" 3 "Controller pedal undeploy" 4 "Slope exceed 10°" 5 "Driving mode is snow、mud、sand" 6 "Keep low speed" 7 "Out rearview mirror undeploy" 8 "Doors are open" 9 "Trunk are open" 10 "System is fail" 11 "System is not available" 12 "Sys exit" ;
VAL_ 1330 DWD_SoundIndcn 0 "No warning" 1 "Long beep" 2 "3Hz" 3 "1.5Hz" ;
VAL_ 1330 LSensorFailSts 0 "Sensor normal" 1 "Sensor fault" ;
VAL_ 1330 RSensorFailSts 0 "Sensor normal" 1 "Sensor fault" ;
VAL_ 1330 DWD_Distance 0 "No object" 1 "Object in zone 1, 0~5cm" 2 "Object in zone 2, 6~10cm" 3 "Object in zone 3, 11~15cm" 4 "Object in zone 4, 16~20cm" 5 "Object in zone 5, 21~25cm" 6 "Object in zone 6, 26~30cm" 7 "Object in zone 7, 31~35cm" 8 "Object in zone 8, 36~40cm" 9 "Object in zone 9, 41~45cm" 10 "Object in zone 10, 46~50cm" 11 "Object in zone 11, 51~55cm" 12 "Object in zone 12, 56~60cm" 13 "Object in zone 13, 61~65cm" 14 "Object in zone 14, 66~70cm" 15 "Object in zone 15, 71~75cm" 16 "Object in zone 16, 76~80cm" 17 "Object in zone 17, 81~85cm" 18 "Object in zone 18, 86~90cm" 19 "Object in zone 19, 91~95cm" 20 "Object in zone 20, 96~100cm" 21 "Object in zone 21, 101~105cm" 22 "Object in zone 22, 105~110cm" 23 "Object in zone 23, 111~115cm" 24 "Object in zone 24, 116~120cm" 25 "Object in zone 25, 121~125cm" 26 "Object in zone 26, 126~130cm" 27 "Object in zone 27, 131~135cm" 28 "Object in zone 28, 136~140cm" 29 "Object in zone 29, 141~145cm" 30 "Object in zone 30, 146~150cm" ;
VAL_ 1330 DWD_Switch 0 "Not Active" 1 "ON" 2 "OFF" 3 "Reserved" ;
VAL_ 1328 RADAR_1_RadarDetectSts 0 "No_Detecting_Startup" 1 "Front_Radar_Detecting" 2 "Rear_Radar_Detecting" 3 "Not_Used" ;
VAL_ 1328 RADAR_1_RadarWorkSts 0 "Not_Active" 1 "Active" ;
VAL_ 1328 RADAR_1_LHRRadarSensorDistance 63 "Sensor_Err" 62 "Startup" ;
VAL_ 1328 RADAR_1_RHMRRadarSensorDistance 63 "Sensor_Err" 62 "Startup" ;
VAL_ 1328 RADAR_1_LHMRRadarSensorDistance 63 "Sensor_Err" 62 "Startup" ;
VAL_ 1328 RADAR_1_RHRRadarSensorDistance 63 "Sensor_Err" 62 "Startup" ;
VAL_ 1328 RADAR_1_LHFRadarSensorDistance 31 "Sensor_Err" 30 "Startup" ;
VAL_ 1328 RADAR_1_RHFRadarSensorDistance 31 "Sensor_Err" 28 "Not_Used" 29 "Not_Used" 30 "Startup" ;
VAL_ 1328 RADAR_1_ParkingRadarSwSts 0 "Off" 1 "On" ;
VAL_ 1328 RADAR_1_RHMFRadarSensorDistance 31 "Sensor_Err" 30 "Startup" ;
VAL_ 1328 RADAR_1_LHMFRadarSensorDistance 31 "Sensor_Err" 30 "Startup" ;
VAL_ 1328 RADAR_1_AudibleBeepRate 0 "Off" 1 "On" 2 "4Hz" 3 "2Hz" 4 "1Hz" ;
VAL_ 259 EMS_EngineSpeed_Actual 65535 "Invalid" ;
VAL_ 1234 FRZCU_FRSeatHeiFb 0 "Not active" ;
VAL_ 1234 FRZCU_FRSeatLvlFb 0 "Not active" ;
VAL_ 1234 FRZCU_FRSeatBackAgFb 0 "Not active" ;
VAL_ 1234 FRZCU_FRSeatLegSpprtFb 0 "Not active" ;
VAL_ 1234 FRZCU_FRWinSts 0 "Not Active" 1 "Comfort" 2 "Close" 3 "Open" 4 "Other Position" 5 "Closing" 6 "Opening" 7 "Reserved" ;
VAL_ 1234 FRZCU_RRWinSts 0 "Not Active" 1 "Comfort" 2 "Close" 3 "Open" 4 "Other Position" 5 "Closing" 6 "Opening" 7 "Reserved" ;
VAL_ 1234 FRZCU_FRSeatLegRestAngleFb 0 "Not Active" ;
VAL_ 1234 FRZCU_FRSeatCushFb 0 "Not Active" ;
VAL_ 1234 FRZCU_FRSeatNeedMemory 0 "No Request" 1 "Request" ;
VAL_ 1234 FRZCU_FRMemoryFb 0 "Not Active" 1 "Success" 2 "Fail" 3 "Ongoing" ;
VAL_ 1234 FRZCU_FRRecoverFb 0 "Not Active" 1 "Success" 2 "Fail" 3 "Ongoing" ;
VAL_ 1234 FRZCU_EasyEntryExitFb 0 "Not Active" 1 "ON" 2 "OFF" 3 "Not Used" ;
VAL_ 1234 FRZCU_EnjoyableSeatWarning 0 "Not Active" 1 "Buckle tied" 2 "Occupied" ;
VAL_ 1234 FRZCU_EnjoyableSeatSts 0 "Not Active" 1 "Forward Moving" 2 "Backward Moving" ;
VAL_ 1234 SeatHeatLevelsFR 0 "OFF" 1 "Level1" 2 "Level2" 3 "Level3" 4 "AUTO(Reserved)" ;
VAL_ 1234 SeatVentLevelsFR 0 "OFF" 1 "Level1" 2 "Level2" 3 "Level3" ;
VAL_ 1234 SeatHeatLevelsRR 0 "OFF" 1 "Level1" 2 "Level2" 3 "Level3" 4 "AUTO(Reserved)" ;
VAL_ 1234 SeatVentLevelsRR 0 "OFF" 1 "Level1" 2 "Level2" 3 "Level3" ;
VAL_ 1234 FRZCU_FRSeatFoldFb 0 "Not Active" ;
VAL_ 517 MFSR_UP_SW 0 "Not_action" 1 "Pressed" 2 "Stuck" 3 "invalid" ;
VAL_ 517 MFSR_DW_SW 0 "Not_action" 1 "Pressed" 2 "Stuck" 3 "invalid" ;
VAL_ 517 MFSR_Left_SW 0 "Not_action" 1 "Pressed" 2 "Stuck" 3 "invalid" ;
VAL_ 517 MFSR_Right_SW 0 "Not_action" 1 "Pressed" 2 "Stuck" 3 "invalid" ;
VAL_ 517 MFSR_OK_SW 0 "Not_action" 1 "Pressed" 2 "Stuck" 3 "invalid" ;
VAL_ 517 MFSR_Voice_SW 0 "Not_action" 1 "Pressed" 2 "Stuck" 3 "invalid" ;
VAL_ 517 MFSR_Customize 0 "Not_action" 1 "Pressed" 2 "Stuck" 3 "invalid" ;
VAL_ 1096 TMS_AirPurgeReminderSts 0 "Not_Active" 1 "ON" 2 "OFF" 3 "Not_Used" ;
VAL_ 1096 TMS_BT_Reduce_Wind_SpeedSts 0 "Off" 1 "Active" ;
VAL_ 1096 TMS_First_BlowingSts 0 "Off" 1 "Active" ;
VAL_ 1096 TMS_CirculationInTunnelsSts 0 "Off" 1 "Active" ;
VAL_ 1096 TMS_crosscountry_coolingSts 0 "No_Request" 1 "Active" 2 "Not_Active" ;
VAL_ 1096 TMS_ParkingAirConditioningStatus 0 "Inactive" 1 "AUTO" 2 "ventilate" ;
VAL_ 1096 TMS_CoolantFillSts 0 "No_Request" 1 "Request" ;
VAL_ 1096 TMS_UVC_ControlSts 0 "No_Request" 1 "Close_Request" 2 "Open_Request" 3 "AUTO" ;
VAL_ 1096 TMS_UVC_LuminanceSts 0 "No_Request" 1 "level_1" 2 "level_2" 3 "Reserved" 4 "Reserved" 5 "Reserved" 6 "Reserved" 7 "Reserved" ;
VAL_ 1096 TMS_ICC_Lightoff_Sts 0 "No_Request" 1 "FraganceLight_on_Sts" 2 "FraganceLight_off_Sts" 3 "Reserved" ;
VAL_ 1096 TMS_ICC_Memoff_Sts 0 "No_Request" 1 "FraganceMem_on" 2 "FraganceMem_off" 3 "Reserved" ;
VAL_ 1096 TMS_keepwarmSet_TemperatureSts 0 "Temperature_20°C" 1 "Temperature_25°C" 2 "Temperature_30°C" 3 "Temperature_35°C" 4 "Temperature_40°C" 5 "Temperature_45°C" 6 "Temperature_50°C" 7 "Temperature_55°C" 8 "Temperature_60°C" 9 "reserved" 10 "reserved" 11 "reserved" 12 "reserved" 13 "reserved" 14 "reserved" 15 "reserved" 16 "reserved" 17 "reserved" 18 "reserved" 19 "reserved" 20 "reserved" 21 "reserved" 22 "reserved" 23 "reserved" 24 "reserved" 25 "reserved" 26 "reserved" 27 "reserved" 28 "reserved" 29 "reserved" 30 "reserved" 31 "reserved" 32 "reserved" 33 "reserved" 34 "reserved" 35 "reserved" 36 "reserved" 37 "reserved" 38 "reserved" 39 "reserved" 40 "reserved" 41 "reserved" 42 "reserved" 43 "reserved" 44 "reserved" 45 "reserved" 46 "reserved" 47 "reserved" 48 "reserved" 49 "reserved" 50 "reserved" 51 "reserved" 52 "reserved" 53 "reserved" 54 "reserved" 55 "reserved" 56 "reserved" 57 "reserved" 58 "reserved" 59 "reserved" 60 "reserved" 61 "reserved" 62 "reserved" 63 "reserved" 64 "reserved" 65 "reserved" 66 "reserved" 67 "reserved" 68 "reserved" 69 "reserved" 70 "reserved" 71 "reserved" 72 "reserved" 73 "reserved" 74 "reserved" 75 "reserved" 76 "reserved" 77 "reserved" 78 "reserved" 79 "reserved" 80 "reserved" 81 "reserved" 82 "reserved" 83 "reserved" 84 "reserved" 85 "reserved" 86 "reserved" 87 "reserved" 88 "reserved" 89 "reserved" 90 "reserved" 91 "reserved" 92 "reserved" 93 "reserved" 94 "reserved" 95 "reserved" 96 "reserved" 97 "reserved" 98 "reserved" 99 "reserved" 100 "reserved" 101 "reserved" 102 "reserved" 103 "reserved" 104 "reserved" 105 "reserved" 106 "reserved" 107 "reserved" 108 "reserved" 109 "reserved" 110 "reserved" 111 "reserved" 112 "reserved" 113 "reserved" 114 "reserved" 115 "reserved" 116 "reserved" 117 "reserved" 118 "reserved" 119 "reserved" 120 "reserved" 121 "reserved" 122 "reserved" 123 "reserved" 124 "reserved" 125 "reserved" 126 "reserved" 127 "reserved" 128 "reserved" 129 "reserved" 130 "reserved" 131 "reserved" 132 "reserved" 133 "reserved" 134 "reserved" 135 "reserved" 136 "reserved" 137 "reserved" 138 "reserved" 139 "reserved" 140 "reserved" 141 "reserved" 142 "reserved" 143 "reserved" 144 "reserved" 145 "reserved" 146 "reserved" 147 "reserved" 148 "reserved" 149 "reserved" 150 "reserved" 151 "reserved" 152 "reserved" 153 "reserved" 154 "reserved" 155 "reserved" 156 "reserved" 157 "reserved" 158 "reserved" 159 "reserved" 160 "reserved" 161 "reserved" 162 "reserved" 163 "reserved" 164 "reserved" 165 "reserved" 166 "reserved" 167 "reserved" 168 "reserved" 169 "reserved" 170 "reserved" 171 "reserved" 172 "reserved" 173 "reserved" 174 "reserved" 175 "reserved" 176 "reserved" 177 "reserved" 178 "reserved" 179 "reserved" 180 "reserved" 181 "reserved" 182 "reserved" 183 "reserved" 184 "reserved" 185 "reserved" 186 "reserved" 187 "reserved" 188 "reserved" 189 "reserved" 190 "reserved" 191 "reserved" 192 "reserved" 193 "reserved" 194 "reserved" 195 "reserved" 196 "reserved" 197 "reserved" 198 "reserved" 199 "reserved" 200 "reserved" 201 "reserved" 202 "reserved" 203 "reserved" 204 "reserved" 205 "reserved" 206 "reserved" 207 "reserved" 208 "reserved" 209 "reserved" 210 "reserved" 211 "reserved" 212 "reserved" 213 "reserved" 214 "reserved" 215 "reserved" 216 "reserved" 217 "reserved" 218 "reserved" 219 "reserved" 220 "reserved" 221 "reserved" 222 "reserved" 223 "reserved" 224 "reserved" 225 "reserved" 226 "reserved" 227 "reserved" 228 "reserved" 229 "reserved" 230 "reserved" 231 "reserved" 232 "reserved" 233 "reserved" 234 "reserved" 235 "reserved" 236 "reserved" 237 "reserved" 238 "reserved" 239 "reserved" 240 "reserved" 241 "reserved" 242 "reserved" 243 "reserved" 244 "reserved" 245 "reserved" 246 "reserved" 247 "reserved" 248 "reserved" 249 "reserved" 250 "reserved" 251 "reserved" 252 "reserved" 253 "reserved" 254 "reserved" ;
VAL_ 1096 TMS_BiochemicalFuncSts 0 "Not Active" 1 "ON" 2 "OFF" 3 "Reserved" ;
VAL_ 1096 TMS_TimedVentilationSts 0 "Not Active" 1 "ON" 2 "OFF" 3 "Reserved" ;
VAL_ 1240 TMS_CFSSwitchFb 0 "OFF" 1 "ON" ;
VAL_ 1240 TDU_CFSPosOneType 0 "No Frag" 1 "Type 1" 2 "Type 2" 3 "Type 3" 4 "Type 4" 5 "Type 5" 6 "Unfilled" 7 "Position one active" 8 "Type 6" 9 "Type7" 10 "Type8" 11 "Type9" 12 "Type10" 13 "Type11" 14 "Type12" 15 "Not Active" ;
VAL_ 1240 TDU_CFSPosTwoType 0 "No Frag" 1 "Type 1" 2 "Type 2" 3 "Type 3" 4 "Type 4" 5 "Type 5" 6 "Unfilled" 7 "Position one active" 8 "Type 6" 9 "Type7" 10 "Type8" 11 "Type9" 12 "Type10" 13 "Type11" 14 "Type12" 15 "Not Active" ;
VAL_ 1240 TDU_CFSPosThreeType 0 "No Frag" 1 "Type 1" 2 "Type 2" 3 "Type 3" 4 "Type 4" 5 "Type 5" 6 "Unfilled" 7 "Position one active" 8 "Type 6" 9 "Type7" 10 "Type8" 11 "Type9" 12 "Type10" 13 "Type11" 14 "Type12" 15 "Not Active" ;
VAL_ 1240 TDU_CFSRunOut 0 "No Unset" 1 "Position One Runout" 2 "Position Two Runout" 3 "Position One and Two Runout" 4 "Position Three Runout" 5 "Position One and Three Runout" 6 "Position Two and Three Runout" 7 "Position One and Two and Three Runout" 8 "Reserved" 9 "Reserved" 10 "Reserved" 11 "Reserved" 12 "Reserved" 13 "Reserved" 14 "Reserved" 15 "Not Active" ;
VAL_ 1240 TMS_CFSShortWarn 0 "No Unset" 1 "Position One ShortWarn" 2 "Position Two ShortWarn" 3 "Position One and Two ShortWarn" 4 "Position Three ShortWarn" 5 "Position One and Three ShortWarn" 6 "Position Two and Three ShortWarn" 7 "Position One and Two and Three ShortWarn" 8 "Reserved" 9 "Reserved" 10 "Reserved" 11 "Reserved" 12 "Reserved" 13 "Reserved" 14 "Reserved" 15 "Not Active" ;
VAL_ 1240 TMS_CFSLevelSetFb 0 "Not Active" 1 "Level 1" 2 "Level 2" 3 "Level 3" 4 "Reserved" 5 "Reserved" 6 "Reserved" 7 "Reserved" 8 "Reserved" 9 "Reserved" 10 "Reserved" 11 "Reserved" 12 "Reserved" 13 "Reserved" 14 "Reserved" 15 "Reserved" ;
VAL_ 1240 TMS_CFSPosSetFb 0 "Not Active" 1 "Position One" 2 "Position Two" 3 "Position Three" ;
VAL_ 1240 TMS_PM25SwitchFb 0 "OFF" 1 "On" ;
VAL_ 1240 TMS_ThrModeStsFb 0 "Blow Face" 1 "Blow Face and Blow Foot" 2 "Blow Foot" 3 "Auto" 4 "Reserved" 5 "Reserved" 6 "Reserved" 7 "Not Active" ;
VAL_ 1240 TMS_ThrSetTempFb_C 31 "Not active" ;
VAL_ 1240 TMS_ThrCLMSwitchFb 0 "OFF" 1 "On" ;
VAL_ 1240 TMS_ThrAutoSwitchFb 0 "Auto OFF" 1 "Auto On" ;
VAL_ 1240 TMS_ThrBlowSpeedLevelKeyStsFb 0 "Not Active" 1 "Level  1" 2 "Level  2" 3 "Level  3" 4 "Level  4" 5 "Level  5" 6 "Level  6" 7 "Level  7" 8 "Level  0" 9 "Reserved" 10 "Reserved" 11 "Reserved" 12 "Reserved" 13 "Reserved" 14 "Reserved" 15 "Reserved" ;
VAL_ 638 FRZCU_HoodSts 0 "Close" 1 "Ajar_" 2 "full_open" 3 "Reserved" ;
VAL_ 638 FRZCU_AuthenResult 0 "not_success" 1 "success_" ;
VAL_ 638 FRZCU_PowerMode 0 "Off" 1 "Comfortable" 2 "ON" 3 "Reserved" ;
VAL_ 638 FRZCU_TrunkSts 0 "Close" 1 "Ajar_" 2 "full_open" 3 "Reserved" ;
VAL_ 638 FRZCU_HandleSwitchStsFL 0 "Not_Active" 1 "Outside" 2 "Inside" 3 "Bothside" ;
VAL_ 638 FRZCU_HandleSwitchStsFR 0 "Not_Active" 1 "Outside" 2 "Inside" 3 "Bothside" ;
VAL_ 638 FRZCU_HandleSwitchStsRR 0 "Not_Active" 1 "Outside" 2 "Inside" 3 "Bothside" ;
VAL_ 638 FRZCU_HandleSwitchStsRL 0 "Not_Active" 1 "Outside" 2 "Inside" 3 "Bothside" ;
VAL_ 638 SeatLength_target_Passenger 0 "Not_active" 1 "0" 2 "10%" 3 "20%" 4 "30%" 5 "40%" 6 "50%" 7 "60%" 8 "70%" 9 "80%" 10 "90%" 11 "100%" 12 "Reserved" 13 "Reserved" 14 "Reserved" 15 "Reserved" ;
VAL_ 638 SeatBackrest_target_Passenger 0 "Not_active" 1 "0" 2 "5%" 3 "10%" 4 "15%" 5 "20%" 6 "25%" 7 "30%" 8 "35%" 9 "40%" 10 "45%" 11 "50%" 12 "55%" 13 "60%" 14 "65%" 15 "70%" 16 "75%" 17 "80%" 18 "85%" 19 "90%" 20 "95%" 21 "100%" 22 "Reserved" 23 "Reserved" 24 "Reserved" 25 "Reserved" 26 "Reserved" 27 "Reserved" 28 "Reserved" 29 "Reserved" 30 "Reserved" 31 "Reserved" ;
VAL_ 638 FRZCU_TrunkLockSts 0 "Locked" 1 "Unlocked" 2 "Superlocked" 3 "Unknown" ;
VAL_ 638 FRZCU_HoodLockSts 0 "Locked" 1 "Unlocked" 2 "Superlocked" 3 "Unknown" ;
VAL_ 638 FrontBackSpeedAdj_Cmd 0 "No_Request" 1 "Low" 2 "Medium" 3 "High" 4 "Reserved" 5 "Reserved" 6 "Reserved" 7 "invalid" ;
VAL_ 638 FRZCU_GloveboxSW 0 "OFF" 1 "ON" ;
VAL_ 638 FRZCU_FRReleaseLockSts 0 "None" 1 "Releasing" 2 "Released" 3 "Reset" 4 "Resetting" 5 "Reserved" 6 "Reserved" 7 "Reserved" ;
VAL_ 638 FRZCU_RRReleaseLockSts 0 "None" 1 "Releasing" 2 "Released" 3 "Reset" 4 "Resetting" 5 "Reserved" 6 "Reserved" 7 "Reserved" ;
VAL_ 638 FRZCU_PELockInKeyWarning 0 "Not_Active" 1 "Active" ;
VAL_ 638 FRZCU_PowerOFFWarning 0 "Not_Active" 1 "Active" ;
VAL_ 638 FRZCU_KeylessWarning 0 "Not_Active" 1 "Active" ;
VAL_ 638 FRZCU_OTAPwrDwnReqFb 0 "No_Command" 1 "Success" 2 "Fail" 3 "Resrved" ;
VAL_ 638 FRZCU_OTAPwrOnReqFb 0 "No_Command" 1 "Success" 2 "Fail" 3 "Resrved" ;
VAL_ 949 PEPS_InformationSource 0 "Not_Active" 1 "Smart_Information" 2 "RKE_Information" 3 "Near_Access" ;
VAL_ 949 PEPS_OrderInformation 0 "OFF" 1 "Lock" 2 "Unlock" 4 "Trunk" 5 "Welcome_On" 6 "Welcome_Off" 7 "RKE_Search_Car" 8 "Power_Slide_Door_Left" ;
VAL_ 949 PEPS_IDInformation 0 "Not_Active" 1 "Transmitter_1" 2 "Transmitter_2" 3 "Transmitter_3" 4 "Transmitter_4" 5 "Transmitter_BLT1" 6 "Transmitter_BLT2" 7 "Transmitter_BLT3" 8 "Transmitter_NFC1" 9 "Transmitter_NFC2" 10 "Transmitter_NFC3" ;
VAL_ 949 PEPS_KeySts 0 "Not_Active" 1 "PEPS_Key_In" 2 "PEPS_Key_Near_Flant" 3 "PEPS_Key_Near_Frant" 4 "PEPS_Key_Near_Trunkant" 5 "Unknow" ;
VAL_ 949 PEPS_ETRUnLockReq 0 "Not_Request" 1 "Request" ;
VAL_ 1028 PEPS_WelcomeON 0 "Default_value" 1 "Welcome_light_OFF" 2 "Welcome_light_ON" 3 "Reserved" ;
VAL_ 1028 PEPS_VehicleSearchReq 0 "No_Request" 1 "Request" 2 "Reseved" 3 "Reseved" ;
VAL_ 1028 PEPS_SATOReminder 0 "No_Command" 1 "Remind_stop" 2 "Remind_start" 3 "Reseved" ;
VAL_ 1028 PEPS_PLGUnlockReq 0 "Not_Request" 1 "Request" 2 "Reseved" 3 "Reseved" ;
VAL_ 1028 PEPS_RKETrunkSts 0 "Not_Active" 1 "Long_Press" 2 "Short_Press" 3 "Not_Used" ;
VAL_ 1028 PEPS_SSBInhibitCWCSts 0 "Default" 1 "Disable" 2 "Reseved" 3 "Reseved" ;
VAL_ 1028 PEPS_WirelessChargingCtrSts 0 "Default" 1 "Disable" 2 "Reseved" 3 "Reseved" ;
VAL_ 1028 PEPS_EmgyShutdown 0 "No_Happen" 1 "Happen" 2 "Reseved" 3 "Reseved" ;
VAL_ 1028 PEPS_SSBInputFailure 0 "Not_Fail" 1 "Fail" 2 "Reseved" 3 "Reseved" ;
VAL_ 1028 PEPS_SmartSystemWarning1_1 0 "Normal" 1 "Identifier_is_out_of_vehicle" 2 "Reseved" 3 "Reseved" ;
VAL_ 1028 PEPS_SmartSystemWarning2_2 0 "Normal" 1 "Identifier_is_out_of_vehicle_range_when_vehicle_starts_running" 2 "Reseved" 3 "Reseved" ;
VAL_ 1028 PEPS_SmartSystemWarning3_1 0 "Normal" 1 "Identifier_low_battery_detected" 2 "Reseved" 3 "Reseved" ;
VAL_ 1028 PEPS_SmartSystemWarning3_2 0 "Normal" 1 "Engine_start_not_possible_if_gear_box_not_in_P_or_N_position" 2 "Reseved" 3 "Reseved" ;
VAL_ 1028 PEPS_SmartSystemWarning4_2 0 "Normal_" 1 "Engine_start_attempted_without_pressing_clutch/brake_pedal" 2 "Reseved" 3 "Reseved" ;
VAL_ 1028 PEPS_SmartSystemWarning4_3 0 "Normal" 1 "Switching_OFF_while_Gear_box_not_in_P_position" 2 "Reseved" 3 "Reseved" ;
VAL_ 1028 PEPS_SystemWarning 0 "Normal" 1 "Fault" 2 "Reseved" 3 "Reseved" ;
VAL_ 1028 PEPS_BLTKeyPESts 0 "OFF" 1 "ON" 2 "Reseved" 3 "Reseved" ;
VAL_ 1291 BMS_TBOXHvBattMaxT 254 "Abnormal" 255 "Invalid" ;
VAL_ 1291 BMS_TBOXHvBattMinT 254 "Abnormal" 255 "Invalid" ;
VAL_ 1291 BMS_SOCLight 127 "Invalid" ;
VAL_ 1104 RLCR_2_RCWWarn 0 "No Warning" 1 "Level1 Warning" 2 "Level2 Warning" 3 "Not Used" ;
VAL_ 1104 RLCR_2_RCTAWarn 0 "No Warning" 1 "Warning" ;
VAL_ 1104 RLCR_2_BSDLCWONOFFSts 0 "Not active" 1 "OFF" 2 "ON" 3 "Reserved" ;
VAL_ 1104 RLCR_2_DOWONOFFSts 0 "Not active" 1 "OFF" 2 "ON" 3 "Reserved" ;
VAL_ 1104 RLCR_2_RCWONOFFSts 0 "Not active" 1 "OFF" 2 "ON" 3 "Reserved" ;
VAL_ 1104 RLCR_2_RCTARCTBONOFFSts 0 "OFF" 1 "warning" 2 "Reserved" 3 "Reserved" ;
VAL_ 1271 RRCR_2_RCWWarn 0 "No Warning" 1 "Level1 Warning" 2 "Level2 Warning" 3 "Not Used" ;
VAL_ 1271 RRCR_2_RCTAWarn 0 "No Warning" 1 "Warning" ;
VAL_ 1271 RRCR_2_BSDLCWONOFFSts 0 "Not active" 1 "OFF" 2 "ON" 3 "Reserved" ;
VAL_ 1271 RRCR_2_DOWONOFFSts 0 "Not active" 1 "OFF" 2 "ON" 3 "Reserved" ;
VAL_ 1271 RRCR_2_RCWONOFFSts 0 "Not active" 1 "OFF" 2 "ON" 3 "Reserved" ;
VAL_ 1271 RRCR_2_RCTARCTBONOFFSts 0 "OFF" 1 "warning" 2 "Reserved" 3 "Reserved" ;
VAL_ 587 LHRPulseCounterFailSts 0 "Fail Not Present" 1 "Fail Present" ;
VAL_ 587 RHRPulseCounterFailSts 0 "Fail Not Present" 1 "Fail Present" ;
VAL_ 587 RHFPulseCounterFailSts 0 "Fail Not Present" 1 "Fail Present" ;
VAL_ 587 LHFPulseCounterFailSts 0 "Fail Not Present" 1 "Fail Present" ;
VAL_ 587 LHFWheelDriveDirection 0 "Init" 1 "Forward" 2 "Backward" 3 "Stop" 4 "Invalid" 5 "reserved" 6 "reserved" 7 "reserved" ;
VAL_ 587 RHFWheelDriveDirection 0 "Init" 1 "Forward" 2 "Backward" 3 "Stop" 4 "Invalid" 5 "reserved" 6 "reserved" 7 "reserved" ;
VAL_ 587 LHRWheelDriveDirection 0 "Init" 1 "Forward" 2 "Backward" 3 "Stop" 4 "Invalid" 5 "reserved" 6 "reserved" 7 "reserved" ;
VAL_ 587 RHRWheelDriveDirection 0 "Init" 1 "Forward" 2 "Backward" 3 "Stop" 4 "Invalid" 5 "reserved" 6 "reserved" 7 "reserved" ;
VAL_ 1338 FMCU_ErrLvlDis 0 "No Error" 1 "Err_level1" 2 "Err_level2" 3 "Err_level3" 4 "Err_level4" 5 "Err_level5" 6 "Err_level6" ;
VAL_ 1338 FMCU_SpdAct_EDR 65535 "Invalid" ;
VAL_ 777 ISGF_ErrLvl 0 "No Error" 1 "Err_level1" 2 "Err_level2" 3 "Err_level3" 4 "Err_level4" 5 "Err_level5" 6 "Err_level6" ;
VAL_ 1403 RMCU_ErrLvlDis 0 "No Error" 1 "Err_level1" 2 "Err_level2" 3 "Err_level3" 4 "Err_level4" 5 "Err_level5" 6 "Err_level6" ;
VAL_ 1403 RMCU_Speed_EDR 65535 "Invalid" ;
VAL_ 1299 BMS_PackVoltageDis 65534 "Abnormal" 65535 "Invalid" ;
VAL_ 1299 BMS_PackCurrentDis 65534 "Abnormal" 65535 "Invalid" ;
VAL_ 1099 ISGF_SysTempOvrInd 0 "Lamp off" 1 "Lamp on" ;
VAL_ 1130 TCU_23_GBFaultstatus 0 "No failure" 1 "GB failure" 2 "High oil over temperature" 3 "Clutch over temperature" ;
VAL_ 1130 TCU_23_TeachInState 0 "Default" 1 "Successful" 2 "Fault" 3 "Teach in process" 4 "require teach in" ;
VAL_ 1180 ACU_1_AirBagFailSts 0 "Fail no present, lamp off" 1 "Fail no present, lamp flashing" 2 "Fail present, lamp on" 3 "Lamp on, but no warning information displaying on the LCD" ;
VAL_ 1180 ACU_1_ThdRowLBeltWarning 0 "No Warning" 1 "Warning" ;
VAL_ 1180 ACU_1_ThdRowRBeltWarning 0 "No Warning" 1 "Warning" ;
VAL_ 1180 ACU_1_PsngrSeatBeltWarning 0 "Not warning" 1 "Reserve" 2 "Warning" 3 "Not used" ;
VAL_ 1180 ACU_1_SecRowLBeltWarning 0 "No Warning" 1 "Warning" ;
VAL_ 1180 ACU_1_SecRowMBeltWarning 0 "No Warning" 1 "Warning" ;
VAL_ 1180 ACU_1_SecRowRBeltWarning 0 "No Warning" 1 "Warning" ;
VAL_ 1180 ACU_1_PsngrSeatOccupiedSts 0 "not occupied" 1 "occupied" 2 "open circuit" 3 "short circuit" ;
VAL_ 811 BMS_Chg_Sts 1 "Parking chagre" 2 "Driving charge" 3 "no charge" 4 "charge complete" 14 "Abnomal" 15 "Invalid" ;
VAL_ 1269 LISDShowCMDSts 0 "OFF" 1 "ON" ;
VAL_ 1269 LISDShowModeSts 0 "Default value" 1 "BatteryCharging" 2 "Brand" 3 "TiresPressures" 4 "Weather" 5 "Greetings" 6 "Package" 7 "Panda" 8 "PredestrianCrossing" 9 "PingPong" 10 "Kite" 11 "Coffee" 12 "Reserved" 13 "Reserved" 14 "Reserved" 15 "Reserved" ;
VAL_ 1269 LISD_TransmitStatus 0 "Default value" 1 "Success" 2 "Fail" 3 "Idle" ;
VAL_ 1269 LISD_DisplayStatus 0 "Not Active" 1 "ON" 2 "OFF" 3 "Reserved" ;
VAL_ 1269 LISD_ParkingShowModSts 0 "Default value" 1 "Mode1" 2 "Mode2" 3 "Mode3" 4 "Mode4" 5 "Reserved" 6 "Reserved" 7 "Reserved" 8 "Reserved" 9 "Reserved" 10 "Reserved" 11 "Reserved" 12 "Reserved" 13 "Reserved" 14 "Reserved" 15 "Reserved" ;
VAL_ 1269 LISD_ParkingShowCMDSts 0 "Not Active" 1 "ON" 2 "OFF" 3 "Reserved" ;
VAL_ 1233 RISDShowCMDSts 0 "OFF" 1 "ON" ;
VAL_ 1233 RISDShowModeSts 0 "Default value" 1 "BatteryCharging" 2 "Brand" 3 "TiresPressures" 4 "Weather" 5 "Greetings" 6 "Package" 7 "Panda" 8 "PredestrianCrossing" 9 "PingPong" 10 "Kite" 11 "Coffee" 12 "Reserved" 13 "Reserved" 14 "Reserved" 15 "Reserved" ;
VAL_ 1233 RISD_TransmitStatus 0 "Default value" 1 "Success" 2 "Fail" 3 "Idle" ;
VAL_ 1233 RISD_DisplayStatus 0 "Not Active" 1 "ON" 2 "OFF" ;
VAL_ 1233 RISD_ParkingShowModSts 0 "Default value" 1 "Mode1" 2 "Mode2" 3 "Mode3" 4 "Mode4" 5 "Reserved" 6 "Reserved" 7 "Reserved" 8 "Reserved" 9 "Reserved" 10 "Reserved" 11 "Reserved" 12 "Reserved" 13 "Reserved" 14 "Reserved" 15 "Reserved" ;
VAL_ 1233 RISD_ParkingShowCMDSts 0 "Not Active" 1 "ON" 2 "OFF" ;
VAL_ 1169 LC_DIYMusicShowModSts 0 "Not Active" 1 "Mode1" 2 "Mode2" 3 "Reserved" ;
VAL_ 1169 LC_RandomMusicShowSts 0 "Not Active" 1 "Active" 2 "Reserved" 3 "Reserved" ;
VAL_ 1169 LC_LiShowModSts 0 "Not Active" 1 "OFF" 2 "Mode1" 3 "Mode2" 4 "Mode3" 5 "Mode4(Reserved)" 6 "Mode5(Reserved)" ;
VAL_ 1427 ILCF_1_LogoParkingSts 0 "Not Active" 1 "ON" 2 "OFF" 3 "Reserved" ;
VAL_ 1427 ILCF_1_LogoChargingSts 0 "Not Active" 1 "ON" 2 "OFF" 3 "Reserved" ;
VAL_ 1427 ILCF_1_DIYMusicShowModSts 0 "Not Active" 1 "Mode1" 2 "Mode2" 3 "Mode3" ;
VAL_ 1427 ILCF_1_RandomMusicShowSts 0 "Not Active" 1 "Active" 2 "Reserved" 3 "Reserved" ;
VAL_ 1427 ILCF_1_LogoColorAdjSts 0 "Not Active" ;
VAL_ 821 ADS_5_ILOASts 0 "Off" 1 "On" 2 "Evasioning" 3 "Retreat" 4 "Evasion finished" 5 "None" 6 "Reserved" 7 "Reserved" ;
VAL_ 821 ADS_5_ICAQuitReason 0 "None" 1 "Bad Weather" 2 "Large curve" 3 "ODD not meet" 4 "reserved" 5 "reserved" 6 "reserved" 7 "reserved" ;
VAL_ 821 ADS_5_ISLISt 0 "OFF" 1 "ON" 2 "failure" 3 "Reserved" ;
VAL_ 821 ADS_5_ILOATextInfo 0 "None" 1 "Evading oversized vehicle" 2 "Avoiding obstacles" 3 "Reserved" ;
VAL_ 821 ADS_5_ILOAActdirection 0 "Not active" 1 "Left" 2 "Right" 3 "Reserved" ;
VAL_ 821 ADS_5_LKS_warning 0 "no warning" 1 "warning" ;
VAL_ 821 ADS_5_ISLIOverSpeedWarn 0 "No warning" 1 "Waning1" 2 "Waning2" 3 "Waning3" ;
VAL_ 821 ADS_5_ISLISpeedLimitSign 0 "No display" 1 "Cancellation sign" 2 "5" 3 "10" 4 "15" 5 "20" 6 "25" 7 "30" 8 "35" 9 "40" 10 "45" 11 "50" 12 "55" 13 "60" 14 "65" 15 "70" 16 "75" 17 "80" 18 "85" 19 "90" 20 "95" 21 "100" 22 "105" 23 "110" 24 "115" 25 "120" 26 "125" 27 "130" 28 "135" 29 "140" 30 "145" 31 "150" 32 "155" 33 "160" 34 "165" 35 "170" 36 "175" 37 "180" 38 "185" 39 "190" 40 "195" 41 "200" 42 "Reserved" 43 "Reserved" 44 "Reserved" 45 "Reserved" 46 "Reserved" 47 "Reserved" 48 "Reserved" 49 "Reserved" 50 "Reserved" 51 "Reserved" 52 "Reserved" 53 "Reserved" 54 "Reserved" 55 "Reserved" 56 "Reserved" 57 "Reserved" 58 "Reserved" 59 "Reserved" 60 "Reserved" 61 "Reserved" 62 "Reserved" 63 "Reserved" 64 "Reserved" 65 "Reserved" 66 "Reserved" 67 "Reserved" 68 "Reserved" 69 "Reserved" 70 "Reserved" 71 "Reserved" 72 "Reserved" 73 "Reserved" 74 "Reserved" 75 "Reserved" 76 "Reserved" 77 "Reserved" 78 "Reserved" 79 "Reserved" 80 "Reserved" 81 "Reserved" 82 "Reserved" 83 "Reserved" 84 "Reserved" 85 "Reserved" 86 "Reserved" 87 "Reserved" 88 "Reserved" 89 "Reserved" 90 "Reserved" 91 "Reserved" 92 "Reserved" 93 "Reserved" 94 "Reserved" 95 "Reserved" 96 "Reserved" 97 "Reserved" 98 "Reserved" 99 "Reserved" 100 "Reserved" 101 "Reserved" 102 "Reserved" 103 "Reserved" 104 "Reserved" 105 "Reserved" 106 "Reserved" 107 "Reserved" 108 "Reserved" 109 "Reserved" 110 "Reserved" 111 "Reserved" 112 "Reserved" 113 "Reserved" 114 "Reserved" 115 "Reserved" 116 "Reserved" 117 "Reserved" 118 "Reserved" 119 "Reserved" 120 "Reserved" 121 "Reserved" 122 "Reserved" 123 "Reserved" 124 "Reserved" 125 "Reserved" 126 "Reserved" 127 "Reserved" 128 "Reserved" 129 "Reserved" 130 "Reserved" 131 "Reserved" 132 "Reserved" 133 "Reserved" 134 "Reserved" 135 "Reserved" 136 "Reserved" 137 "Reserved" 138 "Reserved" 139 "Reserved" 140 "Reserved" 141 "Reserved" 142 "Reserved" 143 "Reserved" 144 "Reserved" 145 "Reserved" 146 "Reserved" 147 "Reserved" 148 "Reserved" 149 "Reserved" 150 "Reserved" 151 "Reserved" 152 "Reserved" 153 "Reserved" 154 "Reserved" 155 "Reserved" 156 "Reserved" 157 "Reserved" 158 "Reserved" 159 "Reserved" 160 "Reserved" 161 "Reserved" 162 "Reserved" 163 "Reserved" 164 "Reserved" 165 "Reserved" 166 "Reserved" 167 "Reserved" 168 "Reserved" 169 "Reserved" 170 "Reserved" 171 "Reserved" 172 "Reserved" 173 "Reserved" 174 "Reserved" 175 "Reserved" 176 "Reserved" 177 "Reserved" 178 "Reserved" 179 "Reserved" 180 "Reserved" 181 "Reserved" 182 "Reserved" 183 "Reserved" 184 "Reserved" 185 "Reserved" 186 "Reserved" 187 "Reserved" 188 "Reserved" 189 "Reserved" 190 "Reserved" 191 "Reserved" 192 "Reserved" 193 "Reserved" 194 "Reserved" 195 "Reserved" 196 "Reserved" 197 "Reserved" 198 "Reserved" 199 "Reserved" 200 "Reserved" 201 "Reserved" 202 "Reserved" 203 "Reserved" 204 "Reserved" 205 "Reserved" 206 "Reserved" 207 "Reserved" 208 "Reserved" 209 "Reserved" 210 "Reserved" 211 "Reserved" 212 "Reserved" 213 "Reserved" 214 "Reserved" 215 "Reserved" 216 "Reserved" 217 "Reserved" 218 "Reserved" 219 "Reserved" 220 "Reserved" 221 "Reserved" 222 "Reserved" 223 "Reserved" 224 "Reserved" 225 "Reserved" 226 "Reserved" 227 "Reserved" 228 "Reserved" 229 "Reserved" 230 "Reserved" 231 "Reserved" 232 "Reserved" 233 "Reserved" 234 "Reserved" 235 "Reserved" 236 "Reserved" 237 "Reserved" 238 "Reserved" 239 "Reserved" 240 "Reserved" 241 "Reserved" 242 "Reserved" 243 "Reserved" 244 "Reserved" 245 "Reserved" 246 "Reserved" 247 "Reserved" 248 "Reserved" 249 "Reserved" 250 "Reserved" 251 "Reserved" 252 "Reserved" 253 "Reserved" 254 "Reserved" 255 "Reserved" ;
VAL_ 821 ADS_5_EgoLeftLineHeatgAg 511 "Invalid" ;
VAL_ 821 ADS_5_EgoLeLineID 0 "Invalid" 1 "Valid" ;
VAL_ 821 ADS_5_EgoLeLineColor 0 "No display" 1 "Color_Unknown" 2 "Color_White" 3 "Color_Yellow" ;
VAL_ 821 ADS_5_EgoLeLineTyp 0 "No display" 1 "Type_Unknown" 2 "Type_Solid_Line" 3 "Type_Dashed_Line" ;
VAL_ 821 ADS_5_EgoLeLineHozlDst 511 "Invalid" ;
VAL_ 821 ADS_5_NeborLeLineID 0 "Invalid" 1 "Valid" ;
VAL_ 821 ADS_5_NeborLeLineColor 0 "No display" 1 "Color_Unknown" 2 "Color_White" 3 "Color_Yellow" ;
VAL_ 821 ADS_5_NeborLeLineTyp 0 "No display" 1 "Type_Unknown" 2 "Type_Solid_Line" 3 "Type_Dashed_Line" ;
VAL_ 821 ADS_5_EgoLeLineCrvt 1023 "Invalid" ;
VAL_ 821 ADS_5_NeborLeLineHozlDst 511 "Invalid" ;
VAL_ 821 ADS_5_NeborRiLineID 0 "Invalid" 1 "Valid" ;
VAL_ 821 ADS_5_NeborRiLineColor 0 "No display" 1 "Color_Unknown" 2 "Color_White" 3 "Color_Yellow" ;
VAL_ 821 ADS_5_NeborRiLineTyp 0 "No display" 1 "Type_Unknown" 2 "Type_Solid_Line" 3 "Type_Dashed_Line" ;
VAL_ 821 ADS_5_NeborLeLineCrvt 1023 "Invalid" ;
VAL_ 821 ADS_5_NeborRiLineHozlDst 511 "Invalid" ;
VAL_ 821 ADS_5_ELKSettingSt 0 "None" 1 "On" 2 "Off" 3 "reserved" ;
VAL_ 821 ADS_5_LDWLDPSnvtySet 0 "None" 1 "high" 2 "low" 3 "reserved" ;
VAL_ 821 ADS_5_LDWWarnType 0 "None" 1 "warning only" 2 "vibration  only" 3 "warning and vibration" ;
VAL_ 821 ADS_5_NeborRiLineCrvt 1023 "Invalid" ;
VAL_ 821 ADS_5_IESSwtSet 0 "None" 1 "ON" 2 "Off" 3 "reserved" ;
VAL_ 821 ADS_5_IHCSettingSt 0 "None" 1 "ON" 2 "OFF" 3 "reserved" ;
VAL_ 821 ADS_5_ISLIWarningMod 0 "None" 1 "Display warning;" 2 "Sound+display warning" 3 "Off" ;
VAL_ 821 ADS_5_ICAEnableBtnSts 0 "None" 1 "ON" 2 "Off" 3 "reserved" ;
VAL_ 821 ADS_5_FCM_Camera_textinfo 0 "Camera normal" 1 "Camera failure" 2 "Camera blocked" 3 "Camera high temperature" ;
VAL_ 821 ADS_5_EgoRiLineID 0 "Invalid" 1 "Valid" ;
VAL_ 821 ADS_5_EgoRiLineTyp 0 "No display" 1 "Type_Unknown" 2 "Type_Solid_Line" 3 "Type_Dashed_Line" ;
VAL_ 821 ADS_5_EgoRiLineColor 0 "No display" 1 "Color_Unknown" 2 "Color_White" 3 "Color_Yellow" ;
VAL_ 819 ADS_4_AEBStatus 0 "OFF" 1 "ON" 2 "Failure" 3 "available" 4 "active" 5 "pre-fill" 6 "blindness" 7 "Reserved" ;
VAL_ 819 ADS_4_ACCSts 0 "Off" 1 "Passive" 2 "Standby" 3 "Active_Control" 4 "BrakeOnly" 5 "Override" 6 "StandWait" 7 "failure" 8 "StandActive" 9 "reserved" 10 "reserved" 11 "reserved" 12 "reserved" 13 "reserved" 14 "reserved" 15 "reserved" ;
VAL_ 819 ADS_4_TimeGapSet 0 "None" 1 "Time Gap1" 2 "Time Gap2" 3 "Time Gap3" 4 "Time Gap4" 5 "Time Gap5" 6 "Reserved" 7 "Reserved" ;
VAL_ 819 ADS_4_FcwMode 0 "OFF" 1 "ON" 2 "Failure" 3 "Active" 4 "blindness" 5 "Reserved" 6 "Reserved" 7 "Reserved" ;
VAL_ 819 ADS_4_AEBReqType 0 "NoReq" 1 "AEBm" 2 "AEBp" 3 "AEBVru" 4 "EBA" 5 "LTA" 6 "CPTA" 7 "Reserved" ;
VAL_ 819 ADS_4_SetSpd 255 "Invalid" ;
VAL_ 819 ADS_4_DAIStatus 0 "On" 1 "Off" 2 "Failure" 3 "None" ;
VAL_ 819 ADS_4_ACCTextMessage 0 "No Display" 1 "ACC Activated" 2 "ACC Cannot Be Activated" 3 "ACC Cancelled" 4 "ACC failure" 5 "Weather abnormal" 6 "Driver Override" 7 "Active Decelerate" 8 "Cruise speed can not be added" 9 "ACC abort and take over request" 10 "Maximum decelerate to ahead speed sign" 11 "System add timegap to front big vehicle" 12 "Cut in reminder" 13 "Large curve remider" 14 "Auto drive off reminder" 15 "takeover timeout" ;
VAL_ 819 ADS_4_LongiTakeOverReq 0 "No Request" 1 "Request" ;
VAL_ 819 ADS_4_SetSpdUnit 0 "Km/h" 1 "Mile/h" ;
VAL_ 819 ADS_4_GoNotifier 0 "None" 1 "Go Notifier" 2 "Go Visual Notifier" 3 "Handson visual warning" 4 "Handson and DMS warning" 5 "Press gas reminder" 6 "Reserved" 7 "Reserved" ;
VAL_ 819 ADS_4_DAISts 0 "None" 1 "active Drive Off" 2 "Reserved" 3 "Reserved" ;
VAL_ 819 ADS_4_Radar_textinfo 0 "Radar normal" 1 "Radar failure" 2 "Radar blocked" 3 "Reserved" 4 "Reserved" 5 "Reserved" 6 "Reserved" 7 "Reserved" ;
VAL_ 819 ADS_4_SCF_PopoverReq 0 "No Request" 1 "Driver confirm Request" ;
VAL_ 819 ADS_4_DrvrCfmSCFDispFb 0 "not confirmed" 1 "confirme" ;
VAL_ 819 ADS_4_SCF_SpdLimUnit 0 "Unknown" 1 "km/h" 2 "Miles/h" 3 "Reserved" ;
VAL_ 819 ADS_4_SCF_SpdLimSts 0 "OFF" 1 "STANDBY" 2 "ACTIVE" 3 "REVERSIBLE_FAILURE" 4 "IREVERSIBLE FAILURE" 5 "Reserved" 6 "Reserved" 7 "Reserved" ;
VAL_ 819 ADS_4_ACCObjTyp 0 "No type" 1 "Car" 2 "Truck" 3 "Motorcycle" 4 "Pedestrian" 5 "Cyclist" 6 "Bus" 7 "Reserved" 8 "Reserved" 9 "Reserved" 10 "Reserved" 11 "Reserved" 12 "Reserved" 13 "Reserved" 14 "Reserved" 15 "Reserved" ;
VAL_ 819 ADS_4_FrntFarObjTyp 0 "No type" 1 "Car" 2 "Truck" 3 "Motorcycle" 4 "Pedestrian" 5 "Cyclist" 6 "Bus" 7 "Reserved" 8 "Reserved" 9 "Reserved" 10 "Reserved" 11 "Reserved" 12 "Reserved" 13 "Reserved" 14 "Reserved" 15 "Reserved" ;
VAL_ 819 ADS_4_FrntFarObjID 0 "Invalid" 1 "Valid" ;
VAL_ 819 ADS_4_ACCObjID 0 "Invalid" 1 "Valid" ;
VAL_ 819 ADS_4_LeObjID 0 "Invalid" 1 "Valid" ;
VAL_ 819 ADS_4_LeObjTyp 0 "No type" 1 "Car" 2 "Truck" 3 "Motorcycle" 4 "Pedestrian" 5 "Cyclist" 6 "Bus" 7 "Reserved" 8 "Reserved" 9 "Reserved" 10 "Reserved" 11 "Reserved" 12 "Reserved" 13 "Reserved" 14 "Reserved" 15 "Reserved" ;
VAL_ 819 ADS_4_RiObjID 0 "Invalid" 1 "Valid" ;
VAL_ 819 ADS_4_RiObjTyp 0 "No type" 1 "Car" 2 "Truck" 3 "Motorcycle" 4 "Pedestrian" 5 "Cyclist" 6 "Bus" 7 "Reserved" 8 "Reserved" 9 "Reserved" 10 "Reserved" 11 "Reserved" 12 "Reserved" 13 "Reserved" 14 "Reserved" 15 "Reserved" ;
VAL_ 819 ADS_4_SCFSwtSet 0 "None" 1 "ON" 2 "Off" 3 "reserved" ;
VAL_ 819 ADS_4_AEBSettingSt 0 "None" 1 "ON" 2 "Off" 3 "reserved" ;
VAL_ 819 ADS_4_FCWSettingSt 0 "None" 1 "Off" 2 "high" 3 "middle" 4 "low" 5 "reserved" 6 "reserved" 7 "reserved" ;
VAL_ 819 ADS_4_DAISwtSet 0 "None" 1 "ON" 2 "Off" 3 "reserved" ;
VAL_ 819 ADS_4_CruiseAccelerateSts 0 "None" 1 "Accelerating" 2 "Decelerating" 3 "Reserved" ;
VAL_ 1172 ExternalTemperature_C 254 "invalid" ;
VAL_ 1172 BlowSpeedLevelDisplaySts 0 "Not_Active" 1 "Level_1" 2 "Level_2" 3 "Level_3" 4 "Level_4" 5 "Level_5" 6 "Level_6" 7 "Level_7" 8 "Level_8" 9 "Level_9" 10 "Level_10" 11 "Reserved" 12 "Level_0" 13 "Reserved" 14 "Reserved" 15 "Reserved" ;
VAL_ 1147 CCP_1_FrontAutoACSwitchReq 0 "No_Pressed" 1 "Pressed" ;
VAL_ 1147 CCP_1_FrontOFFSwitchReq 0 "No_Pressed" 1 "Pressed" ;
VAL_ 1147 CCP_1_FBlowSpdCtrlSwitchReq 0 "No_Request" 1 "Speed_1_Request" 2 "Speed_2_Request" 3 "Speed_3_Request" 4 "Speed_4_Request" 5 "Speed_5_Request" 6 "Speed_6_Request" 7 "Speed_7_Request" 8 "Speed_8_Request" 9 "Speed_9_Request" 10 "Speed_10_Request" 12 "Speed_0_Request" 15 "Invalid" ;
VAL_ 1147 FLCCP_MainSetHeatReq 0 "Not_Active" 1 "OFF" 2 "Seat_heating_Level1" 3 "Seat_heating_Level2" 4 "Seat_heating_Level3" ;
VAL_ 1147 FLCCP_MainSetVentilationReq 0 "Not_Active" 1 "OFF" 2 "Seat_Ventilation_Level1" 3 "Seat_Ventilation_Level2" 4 "Seat_Ventilation_Level3" ;
VAL_ 1147 CCP_1_ACFastCool 0 "Not_Active" 1 "On" 2 "Off" 3 "Not_Used" ;
SIG_GROUP_ 612 EPB_R_1_0x264_E2E_P01_1 1 : Fusa_264_1 Fusa_264_2 Fusa_264_3 Fusa_264_4 Fusa_264_5 EPB_R_1_CRC1 EPB_R_1_RollgCntr1 EPB_1_FltLamp EPB_1_ParkLamp EPB_1_ActrSt EPB_1_RWUSt EPB_1_TextDisp IPB_EPBErrorStatus;
SIG_GROUP_ 1291 BMS_2_G_0x50B_E2E_P01_1 1 : BMS_2_G_CRC BMS_2_G_RollgCntr BMS_2_G_Resd BMS_TBOXInsulation_R BMS_TBOXErrorNumber BMS_TBOXHvBattMaxT BMS_TBOXHvBattMinT BMS_SOCLight;
SIG_GROUP_ 1104 RLCR_2_0x450_E2E_P01_1 1 : RLCR_2_CRC1 RLCR_2_RollgCntr1 RLCR_2_Resd1 RLCR_2_RCWWarn RLCR_2_RCTAWarn RLCR_2_BSDLCWONOFFSts RLCR_2_DOWONOFFSts RLCR_2_RCWONOFFSts RLCR_2_RCTARCTBONOFFSts;
SIG_GROUP_ 1271 RRCR_2_0x4F7_E2E_P01_1 1 : RRCR_2_CRC1 RRCR_2_RollgCntr1 RRCR_2_Resd1 RRCR_2_RCWWarn RRCR_2_RCTAWarn RRCR_2_BSDLCWONOFFSts RRCR_2_DOWONOFFSts RRCR_2_RCWONOFFSts RRCR_2_RCTARCTBONOFFSts;
SIG_GROUP_ 1180 New_Signal_Group_49C 1 : ACU_1_PsngrSeatOccupiedSts ACU_1_SecRowRBeltWarning ACU_1_SecRowMBeltWarning ACU_1_SecRowLBeltWarning ACU_1_PsngrSeatBeltWarning ACU_1_ThdRowRBeltWarning ACU_1_ThdRowLBeltWarning ACU_1_AirBagFailSts ABM_1_Rollover_Status ACU_1_CRC1 ACU_1_RollgCntr1 New_Signal_49C_1 New_Signal_49C_2 New_Signal_49C_3 New_Signal_49C_4 New_Signal_49C_5 New_Signal_49C_6 New_Signal_49C_7 New_Signal_49C_8 New_Signal_49C_9;
